VERSION ""

NS_ :

BS_:

BU_: AHLM ASBS CBC DIAGNOST DPDM DTCM ECM EHPS ESC ESL ESM ETM GPF HCP IC IRCM OCM ORC PTS RF_HUB SCCM SGW TBM TCM TPM

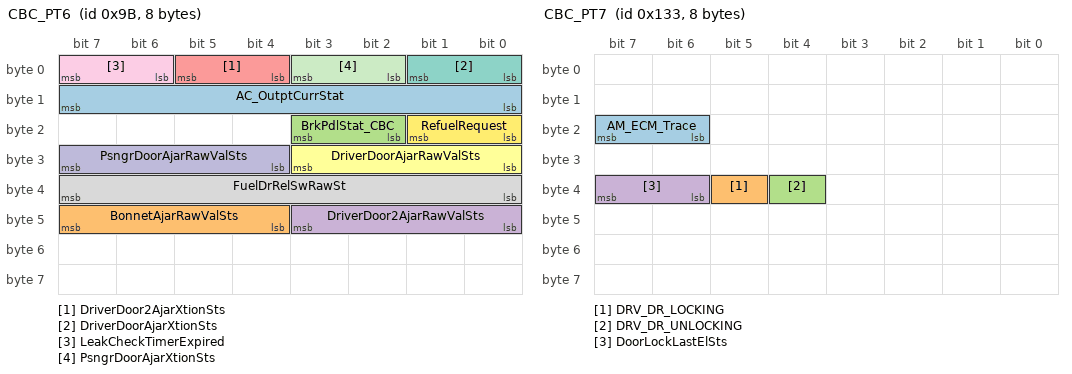
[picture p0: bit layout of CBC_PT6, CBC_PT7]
BO_ 155 CBC_PT6: 8 CBC
 SG_ AC_OutptCurrStat : 8|8@1+ (0.008,0) [0|2] "Amp"  ECM,SGW
 SG_ BonnetAjarRawValSts : 44|4@1+ (1,0) [0|0] ""  ECM,HCP,ORC,SGW
 SG_ BrkPdlStat_CBC : 18|2@1+ (1,0) [0|0] ""  RF_HUB,SGW
 SG_ DriverDoor2AjarRawValSts : 40|4@1+ (1,0) [0|0] ""  ECM,ORC,SGW
 SG_ DriverDoor2AjarXtionSts : 4|2@1+ (1,0) [0|0] ""  ECM,SGW
 SG_ DriverDoorAjarRawValSts : 24|4@1+ (1,0) [0|0] ""  ECM,ESC,ORC,SGW
 SG_ DriverDoorAjarXtionSts : 0|2@1+ (1,0) [0|0] ""  ECM,ESC,SGW
 SG_ FuelDrRelSwRawSt : 32|8@1+ (0.019607843,0) [0|4.98] "Volts"  ECM,SGW
 SG_ LeakCheckTimerExpired : 6|2@1+ (1,0) [0|0] ""  ECM,SGW
 SG_ PsngrDoorAjarRawValSts : 28|4@1+ (1,0) [0|0] ""  ECM,ESC,ORC,SGW
 SG_ PsngrDoorAjarXtionSts : 2|2@1+ (1,0) [0|0] ""  ECM,ESC,SGW
 SG_ RefuelRequest : 16|2@1+ (1,0) [0|0] ""  ECM,SGW

BO_ 307 CBC_PT7: 8 CBC
 SG_ AM_ECM_Trace : 22|2@1+ (1,0) [0|0] ""  ECM,SGW
 SG_ DRV_DR_LOCKING : 37|1@1+ (1,0) [0|1] ""  SGW
 SG_ DRV_DR_UNLOCKING : 36|1@1+ (1,0) [0|1] ""  HCP,SGW
 SG_ DoorLockLastElSts : 38|2@1+ (1,0) [0|3] ""  HCP,SGW

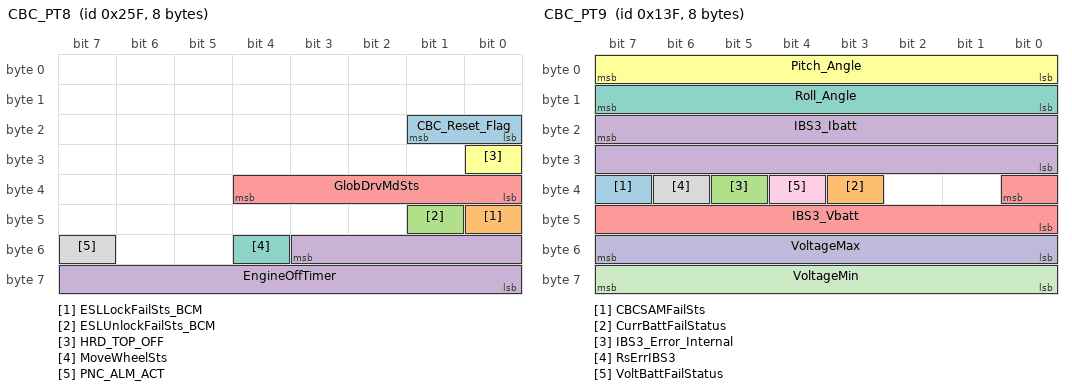
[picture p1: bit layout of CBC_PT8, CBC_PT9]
BO_ 607 CBC_PT8: 8 CBC
 SG_ CBC_Reset_Flag : 16|2@1+ (1,0) [0|0] ""  ECM,SGW
 SG_ ESLLockFailSts_BCM : 40|1@1+ (1,0) [0|0] ""  IC,SGW
 SG_ ESLUnlockFailSts_BCM : 41|1@1+ (1,0) [0|0] ""  IC,SGW
 SG_ EngineOffTimer : 51|12@0+ (1,0) [0|4080] "min"  ECM,ETM,SGW,TBM
 SG_ GlobDrvMdSts : 32|5@1+ (1,0) [0|0] ""  DTCM,ECM,ESC,IC,IRCM,ORC,SGW
 SG_ HRD_TOP_OFF : 24|1@1+ (1,0) [0|0] ""  SGW
 SG_ MoveWheelSts : 52|1@1+ (1,0) [0|0] ""  IC,SGW
 SG_ PNC_ALM_ACT : 55|1@1+ (1,0) [0|0] ""  SGW

BO_ 319 CBC_PT9: 8 CBC
 SG_ CBCSAMFailSts : 39|1@1+ (1,0) [0|0] ""  ECM,SGW
 SG_ CurrBattFailStatus : 35|1@1+ (1,0) [0|0] ""  ECM,SGW
 SG_ IBS3_Error_Internal : 37|1@1+ (1,0) [0|0] ""  ECM,SGW
 SG_ IBS3_Ibatt : 23|16@0+ (0.02,-1000) [-1000|310.68] "A"  ECM,ETM,SGW,TBM
 SG_ IBS3_Vbatt : 32|9@0+ (0.025,5) [5|17.75] "V"  ECM,ETM,HCP,ORC,SGW,TBM
 SG_ Pitch_Angle : 0|8@1+ (1,-90) [-90|90] "°"  IC,SGW
 SG_ Roll_Angle : 8|8@1+ (1,-90) [-90|90] "°"  IC,SGW
 SG_ RsErrIBS3 : 38|1@1+ (1,0) [0|0] ""  ECM,SGW
 SG_ VoltBattFailStatus : 36|1@1+ (1,0) [0|0] ""  ECM,HCP,SGW
 SG_ VoltageMax : 48|8@1+ (0.025,10.6) [10.6|16.975] "Volts"  ECM,SGW
 SG_ VoltageMin : 56|8@1+ (0.025,10.6) [10.6|16.975] "Volts"  ECM,SGW

BO_ 456 CBC_VTA: 4 CBC
 SG_ VTA_STAT : 0|3@1+ (1,0) [0|0] ""  ETM,RF_HUB,SGW,TBM

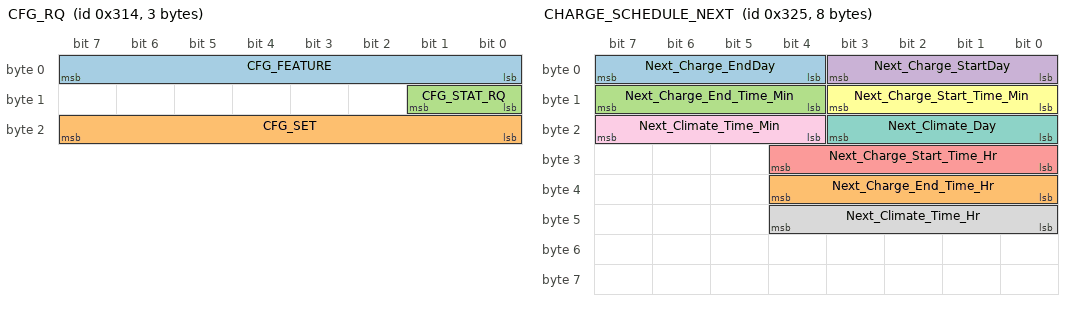
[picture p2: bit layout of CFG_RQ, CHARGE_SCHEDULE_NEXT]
BO_ 788 CFG_RQ: 3 CBC
 SG_ CFG_FEATURE : 0|8@1+ (1,0) [0|0] ""  ESC,HCP,IC,IRCM,PTS,RF_HUB,SGW
 SG_ CFG_SET : 16|8@1+ (1,0) [0|255] ""  ESC,HCP,IC,IRCM,PTS,RF_HUB,SGW
 SG_ CFG_STAT_RQ : 8|2@1+ (1,0) [0|0] ""  ESC,HCP,IC,IRCM,PTS,RF_HUB,SGW

BO_ 805 CHARGE_SCHEDULE_NEXT: 8 HCP
 SG_ Next_Charge_EndDay : 4|4@1+ (1,0) [0|0] ""  CBC,SGW
 SG_ Next_Charge_End_Time_Hr : 32|5@1+ (1,0) [0|23] "Hours"  CBC,SGW
 SG_ Next_Charge_End_Time_Min : 12|4@1+ (5,0) [0|55] "min"  CBC,SGW
 SG_ Next_Charge_StartDay : 0|4@1+ (1,0) [0|0] ""  CBC,SGW
 SG_ Next_Charge_Start_Time_Hr : 24|5@1+ (1,0) [0|23] "Hours"  CBC,SGW
 SG_ Next_Charge_Start_Time_Min : 8|4@1+ (5,0) [0|55] "min"  CBC,SGW
 SG_ Next_Climate_Day : 16|4@1+ (1,0) [0|0] ""  CBC,SGW,TBM
 SG_ Next_Climate_Time_Hr : 40|5@1+ (1,0) [0|23] "Hours"  CBC,SGW,TBM
 SG_ Next_Climate_Time_Min : 20|4@1+ (5,0) [0|55] "min"  CBC,SGW,TBM

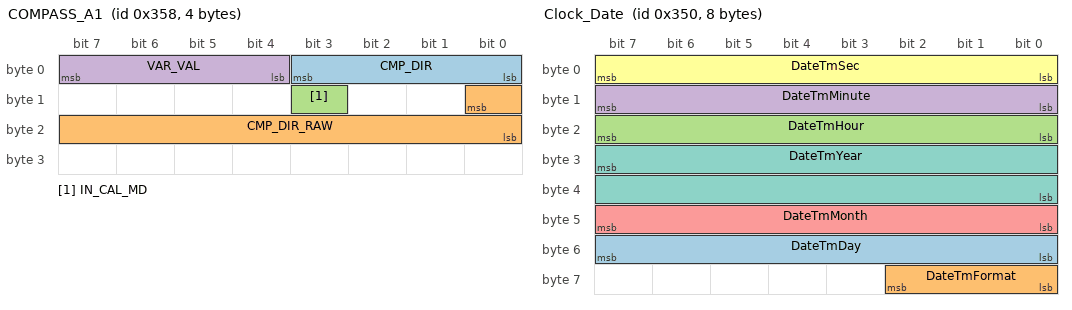
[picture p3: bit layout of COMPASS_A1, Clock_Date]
BO_ 856 COMPASS_A1: 4 CBC
 SG_ CMP_DIR : 0|4@1+ (1,0) [0|0] ""  IC,SGW
 SG_ CMP_DIR_RAW : 8|9@0+ (1,0) [0|359] "Degrees"  SGW
 SG_ IN_CAL_MD : 11|1@1+ (1,0) [0|0] ""  SGW
 SG_ VAR_VAL : 4|4@1+ (1,1) [1|15] ""  SGW

BO_ 219 CfgRqIC: 3 IC
 SG_ CfgFeature : 0|8@1+ (1,0) [0|0] ""  ORC,SGW
 SG_ CfgStatRq : 8|2@1+ (1,0) [0|0] ""  ORC,SGW

BO_ 848 Clock_Date: 8 CBC
 SG_ DateTmDay : 48|8@1+ (1,0) [1|31] "Days"  HCP,IC,RF_HUB,SGW,TPM
 SG_ DateTmFormat : 56|3@1+ (1,0) [0|0] ""  HCP,IC,SGW
 SG_ DateTmHour : 16|8@1+ (1,0) [0|23] "Hours"  HCP,IC,RF_HUB,SGW
 SG_ DateTmMinute : 8|8@1+ (1,0) [0|59] "min"  HCP,IC,RF_HUB,SGW
 SG_ DateTmMonth : 40|8@1+ (1,0) [1|12] "Months"  HCP,IC,RF_HUB,SGW,TPM
 SG_ DateTmSec : 0|8@1+ (1,0) [0|59] "sec"  HCP,IC,SGW
 SG_ DateTmYear : 31|16@0+ (1,0) [0|65534] "Years"  HCP,IC,RF_HUB,SGW,TPM

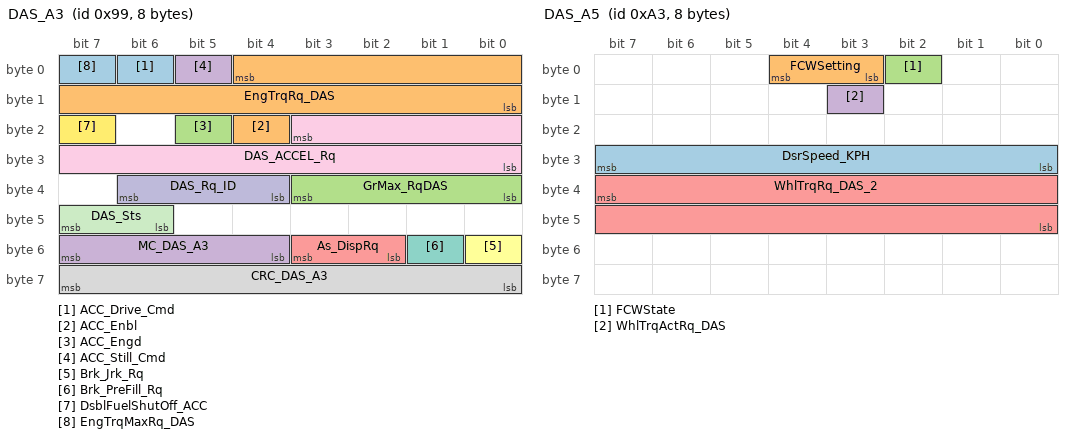
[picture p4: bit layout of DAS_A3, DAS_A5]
BO_ 153 DAS_A3: 8 IRCM
 SG_ ACC_Drive_Cmd : 6|1@1+ (1,0) [0|0] ""  ESC,SGW
 SG_ ACC_Enbl : 20|1@1+ (1,0) [0|0] ""  CBC,ESC,IC,SGW
 SG_ ACC_Engd : 21|1@1+ (1,0) [0|0] ""  ESC,ETM,IC,SGW,TBM
 SG_ ACC_Still_Cmd : 5|1@1+ (1,0) [0|0] ""  ESC,ORC,SGW
 SG_ As_DispRq : 50|2@1+ (1,0) [0|0] ""  ESC,IC,ORC,SGW
 SG_ Brk_Jrk_Rq : 48|1@1+ (1,0) [0|0] ""  ESC,SGW
 SG_ Brk_PreFill_Rq : 49|1@1+ (1,0) [0|0] ""  ESC,SGW
 SG_ CRC_DAS_A3 : 56|8@1+ (1,0) [0|0] ""  ESC,SGW
 SG_ DAS_ACCEL_Rq : 19|12@0+ (0.004885,-16) [-16|4] "m/s²"  ESC,ORC,SGW
 SG_ DAS_Rq_ID : 36|3@1+ (1,0) [0|0] ""  ESC,ORC,SGW
 SG_ DAS_Sts : 46|2@1+ (1,0) [0|0] ""  ESC,SGW
 SG_ DsblFuelShutOff_ACC : 23|1@1+ (1,0) [0|0] ""  ESC,SGW
 SG_ EngTrqMaxRq_DAS : 7|1@1+ (1,0) [0|0] ""  ESC,SGW
 SG_ EngTrqRq_DAS : 4|13@0+ (0.25,-500) [-500|1547.5] "Nm"  ESC,SGW
 SG_ GrMax_RqDAS : 32|4@1+ (1,0) [0|0] ""  ESC,SGW
 SG_ MC_DAS_A3 : 52|4@1+ (1,0) [0|15] ""  ESC,SGW

BO_ 232 DAS_A4: 8 IRCM
 SG_ ACCFaulted : 50|1@1+ (1,0) [0|0] ""  ETM,IC,ORC,SGW,TBM
 SG_ ACCNA_DASMSts : 52|1@1+ (1,0) [0|0] ""  IC,SGW
 SG_ ACCOnOff : 36|3@1+ (1,0) [0|0] ""  ECM,ETM,IC,ORC,SGW,TBM
 SG_ ACConlyNA_DASMSts : 48|1@1+ (1,0) [0|0] ""  ETM,IC,SGW,TBM
 SG_ CIPV_Fused : 30|1@1+ (1,0) [0|0] ""  ORC,SGW
 SG_ CameraBlocked : 54|1@1+ (1,0) [0|0] ""  CBC,IC,ORC,SGW
 SG_ CameraFailure : 55|1@1+ (1,0) [0|0] ""  IC,ORC,SGW
 SG_ FCWBrakingOff : 47|1@1+ (1,0) [0|0] ""  IC,SGW
 SG_ FCW_BrkOn : 29|1@1+ (1,0) [0|0] ""  CBC,ORC,SGW
 SG_ FCW_Error : 26|2@1+ (1,0) [0|0] ""  IC,ORC,SGW
 SG_ FCWonlyNA_DASMSts : 51|1@1+ (1,0) [0|0] ""  IC,SGW
 SG_ HMI_Screens : 0|8@1+ (1,0) [0|254] "Text"  IC,SGW
 SG_ NCCNA_DASMSts : 53|1@1+ (1,0) [0|0] ""  IC,SGW
 SG_ NCConlyNA_DASMSts : 49|1@1+ (1,0) [0|0] ""  ETM,IC,SGW,TBM
 SG_ ObjIntrstDist : 56|8@1+ (1,0) [0|253] "m"  ORC,SGW,TCM
 SG_ RadarBlocked : 46|1@1+ (1,0) [0|0] ""  CBC,IC,ORC,SGW
 SG_ SetSpeed_KPH : 8|8@1+ (1,0) [0|250] "km/h"  ECM,IC,SGW,TCM
 SG_ SetSpeed_MPH : 16|8@1+ (1,0) [0|250] "mph"  IC,ORC,SGW,TCM
 SG_ Sm_ICON_Dspl : 40|6@1+ (1,0) [0|0] ""  IC,SGW

BO_ 163 DAS_A5: 8 IRCM
 SG_ DsrSpeed_KPH : 24|8@1+ (1,0) [0|250] "km/h"  SGW,TCM
 SG_ FCWSetting : 3|2@1+ (1,0) [0|0] ""  CBC,ORC,SGW
 SG_ FCWState : 2|1@1+ (1,0) [0|0] ""  CBC,IC,ORC,SGW
 SG_ WhlTrqActRq_DAS : 11|1@1+ (1,0) [0|0] ""  ESC,SGW
 SG_ WhlTrqRq_DAS_2 : 39|16@0+ (2,-36878) [-36878|94190] "Nm"  ESC,SGW

BO_ 250 DAS_A6: 8 IRCM
 SG_ IRCM_AHB_On : 47|1@1+ (1,0) [0|0] ""  CBC,SGW
 SG_ Lane_DispPopupSts : 16|8@1+ (1,0) [0|254] ""  IC,SGW

BO_ 2015 DG_RQ_GLOBAL: 8 DIAGNOST
 SG_ DG_RQ_GLOBAL : 7|64@0+ (1,0) [0|0] ""  ECM,HCP,TCM

BO_ 1089 DG_RQ_GLOBAL_UDS: 8 DIAGNOST
 SG_ DG_RQ_GLOBAL_UDS : 7|64@0+ (1,0) [0|0] ""  AHLM,ASBS,CBC,DPDM,DTCM,ECM,EHPS,ESC,ESL,ESM,ETM,GPF,HCP,IC,IRCM,OCM,ORC,PTS,RF_HUB,SCCM,TBM,TCM,TPM

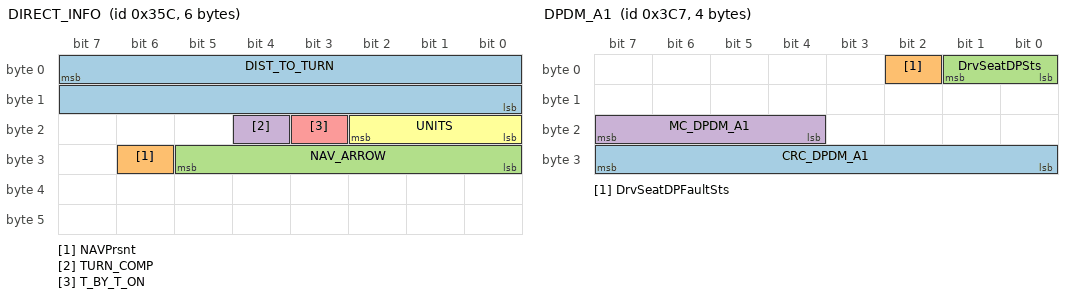
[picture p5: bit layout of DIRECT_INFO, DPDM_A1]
BO_ 860 DIRECT_INFO: 6 CBC
 SG_ DIST_TO_TURN : 7|16@0+ (1,0) [0|65534] ""  IC,SGW
 SG_ NAVPrsnt : 30|1@1+ (1,0) [0|0] ""  IC,SGW
 SG_ NAV_ARROW : 24|6@1+ (1,0) [1|63] "Arrow"  IC,SGW
 SG_ TURN_COMP : 20|1@1+ (1,0) [0|0] ""  IC,SGW
 SG_ T_BY_T_ON : 19|1@1+ (1,0) [0|0] ""  IC,SGW
 SG_ UNITS : 16|3@1+ (1,0) [0|0] ""  IC,SGW

BO_ 967 DPDM_A1: 4 DPDM
 SG_ CRC_DPDM_A1 : 24|8@1+ (1,0) [0|0] ""  ECM,SGW
 SG_ DrvSeatDPFaultSts : 2|1@1+ (1,0) [0|0] ""  ECM,ORC,SGW
 SG_ DrvSeatDPSts : 0|2@1+ (1,0) [0|0] ""  ECM,ESC,IRCM,ORC,RF_HUB,SGW
 SG_ MC_DPDM_A1 : 20|4@1+ (1,0) [0|15] ""  ECM,SGW

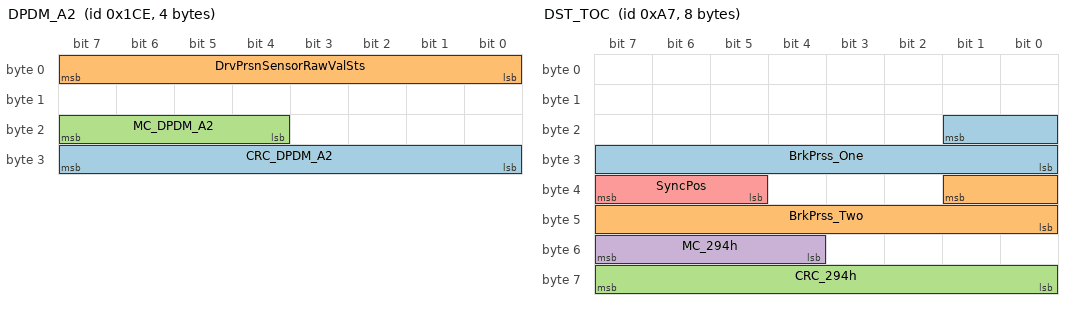
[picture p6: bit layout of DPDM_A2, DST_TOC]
BO_ 462 DPDM_A2: 4 DPDM
 SG_ CRC_DPDM_A2 : 24|8@1+ (1,0) [0|0] ""  ECM,SGW
 SG_ DrvPrsnSensorRawValSts : 0|8@1+ (1,0) [0|255] ""  ECM,SGW
 SG_ MC_DPDM_A2 : 20|4@1+ (1,0) [0|15] ""  ECM,SGW

BO_ 167 DST_TOC: 8 ESC
 SG_ BrkPrss_One : 17|10@0+ (0.0048828125,0) [0|4.9951171875] "Volts"  ECM,SGW
 SG_ BrkPrss_Two : 33|10@0+ (0.0048828125,0) [0|4.9951171875] "Volts"  ECM,SGW
 SG_ CRC_294h : 56|8@1+ (1,0) [0|0] ""  SGW
 SG_ MC_294h : 52|4@1+ (1,0) [0|15] ""  SGW
 SG_ SyncPos : 37|3@1+ (1,0) [0|0] ""  ECM,SGW

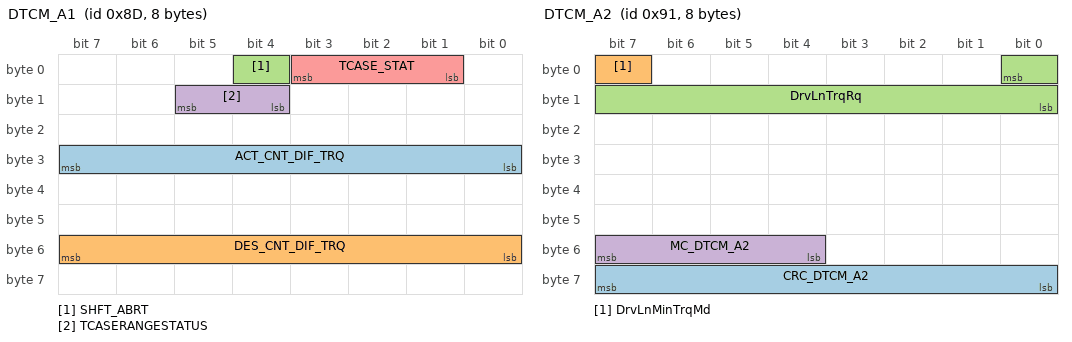
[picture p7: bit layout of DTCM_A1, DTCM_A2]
BO_ 141 DTCM_A1: 8 DTCM
 SG_ ACT_CNT_DIF_TRQ : 24|8@1+ (10,0) [0|2540] "Nm"  ESC,SGW
 SG_ DES_CNT_DIF_TRQ : 48|8@1+ (10,0) [0|2540] "Nm"  SGW
 SG_ SHFT_ABRT : 4|1@1+ (1,0) [0|0] ""  SGW
 SG_ TCASERANGESTATUS : 12|2@1+ (1,0) [0|0] ""  ECM,HCP,SGW,TCM
 SG_ TCASE_STAT : 1|3@1+ (1,0) [0|0] ""  ASBS,CBC,ECM,ESC,ETM,HCP,IC,IRCM,ORC,PTS,RF_HUB,SGW,TBM,TCM

BO_ 145 DTCM_A2: 8 DTCM
 SG_ CRC_DTCM_A2 : 56|8@1+ (1,0) [0|0] ""  ECM,SGW
 SG_ DrvLnMinTrqMd : 7|1@1+ (1,0) [0|0] ""  ECM,SGW
 SG_ DrvLnTrqRq : 0|9@0+ (2,0) [0|1020] "Nm"  ECM,SGW
 SG_ MC_DTCM_A2 : 52|4@1+ (1,0) [0|15] ""  ECM,SGW

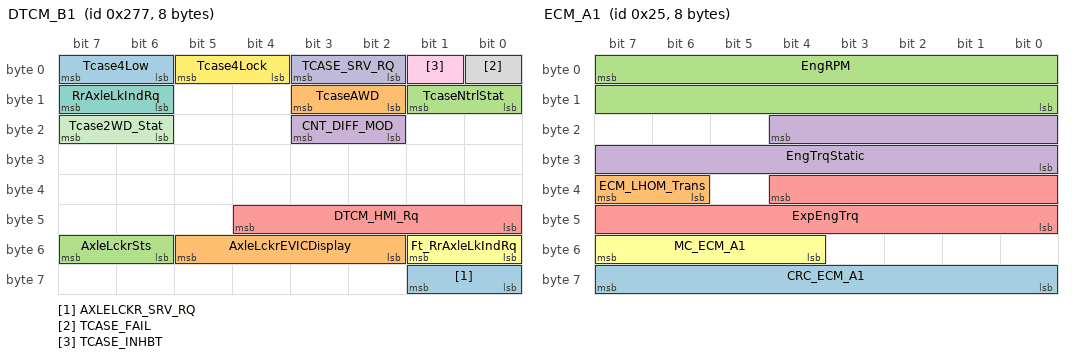
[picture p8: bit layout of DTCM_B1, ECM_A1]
BO_ 631 DTCM_B1: 8 DTCM
 SG_ AXLELCKR_SRV_RQ : 56|2@1+ (1,0) [0|0] ""  IC,SGW
 SG_ AxleLckrEVICDisplay : 50|4@1+ (1,0) [0|0] ""  ETM,IC,SGW
 SG_ AxleLckrSts : 54|2@1+ (1,0) [0|0] ""  ESC,ETM,IC,ORC,SGW
 SG_ CNT_DIFF_MOD : 18|2@1+ (1,0) [0|0] ""  SGW
 SG_ DTCM_HMI_Rq : 40|5@1+ (1,0) [0|0] ""  IC,SGW
 SG_ Ft_RrAxleLkIndRq : 48|2@1+ (1,0) [0|0] ""  CBC,ETM,IC,SGW
 SG_ RrAxleLkIndRq : 14|2@1+ (1,0) [0|0] ""  CBC,ETM,IC,ORC,SGW
 SG_ TCASE_FAIL : 0|1@1+ (1,0) [0|0] ""  ECM,SGW
 SG_ TCASE_INHBT : 1|1@1+ (1,0) [0|0] ""  SGW
 SG_ TCASE_SRV_RQ : 2|2@1+ (1,0) [0|0] ""  ESC,ETM,IC,SGW,TBM
 SG_ Tcase2WD_Stat : 22|2@1+ (1,0) [0|0] ""  CBC,ETM,IC,SGW
 SG_ Tcase4Lock : 4|2@1+ (1,0) [0|0] ""  CBC,ETM,IC,SGW
 SG_ Tcase4Low : 6|2@1+ (1,0) [0|0] ""  CBC,ETM,IC,SGW
 SG_ TcaseAWD : 10|2@1+ (1,0) [0|0] ""  CBC,ETM,IC,SGW
 SG_ TcaseNtrlStat : 8|2@1+ (1,0) [0|0] ""  CBC,ETM,IC,SGW

BO_ 1900 D_RQ_AHCP: 8 DIAGNOST
 SG_ D_RQ_AHCP : 7|64@0+ (1,0) [0|0] ""  HCP

BO_ 1897 D_RQ_AHLM: 8 DIAGNOST
 SG_ D_RQ_AHLM : 7|64@0+ (1,0) [0|0] ""  AHLM

BO_ 1866 D_RQ_ASBS: 8 DIAGNOST
 SG_ D_RQ_ASBS : 7|64@0+ (1,0) [0|0] ""  ASBS

BO_ 2023 D_RQ_BPCM: 8 DIAGNOST
 SG_ D_RQ_BPCM : 7|64@0+ (1,0) [0|0] ""  HCP

BO_ 2020 D_RQ_BSMO: 8 DIAGNOST
 SG_ D_RQ_BSMO : 7|64@0+ (1,0) [0|0] ""  ESC

BO_ 1568 D_RQ_CBC: 8 DIAGNOST
 SG_ D_RQ_CBC : 7|64@0+ (1,0) [0|0] ""  CBC

BO_ 1875 D_RQ_DASM: 8 DIAGNOST
 SG_ D_RQ_DASM : 7|64@0+ (1,0) [0|0] ""  IRCM

BO_ 1873 D_RQ_DPDM: 8 DIAGNOST
 SG_ D_RQ_DPDM : 7|64@0+ (1,0) [0|0] ""  DPDM

BO_ 1867 D_RQ_DTCM: 8 DIAGNOST
 SG_ D_RQ_DTCM : 7|64@0+ (1,0) [0|0] ""  DTCM

BO_ 2016 D_RQ_ECM: 8 DIAGNOST
 SG_ D_RQ_ECM : 7|64@0+ (1,0) [0|0] ""  ECM

BO_ 1882 D_RQ_EPS: 8 DIAGNOST
 SG_ D_RQ_EPS : 7|64@0+ (1,0) [0|0] ""  EHPS

BO_ 1863 D_RQ_ESC: 8 DIAGNOST
 SG_ D_RQ_ESC : 7|64@0+ (1,0) [0|0] ""  ESC

BO_ 1864 D_RQ_ESL: 8 DIAGNOST
 SG_ D_RQ_ESL : 7|64@0+ (1,0) [0|0] ""  ESL

BO_ 1865 D_RQ_ESM: 8 DIAGNOST
 SG_ D_RQ_ESM : 7|64@0+ (1,0) [0|0] ""  ESM

BO_ 1906 D_RQ_GPF: 8 DIAGNOST
 SG_ D_RQ_GPF : 7|64@0+ (1,0) [0|0] ""  GPF

BO_ 2018 D_RQ_HCP: 8 DIAGNOST
 SG_ D_RQ_HCP : 7|64@0+ (1,0) [0|0] ""  HCP

BO_ 1858 D_RQ_IC: 8 DIAGNOST
 SG_ D_RQ_IC : 7|64@0+ (1,0) [0|0] ""  IC

BO_ 1901 D_RQ_IDCM: 8 DIAGNOST
 SG_ D_RQ_IDCM : 7|64@0+ (1,0) [0|0] ""  HCP

BO_ 1886 D_RQ_OCM: 8 DIAGNOST
 SG_ D_RQ_OCM : 7|64@0+ (1,0) [0|0] ""  OCM

BO_ 1860 D_RQ_ORC: 8 DIAGNOST
 SG_ D_RQ_ORC : 7|64@0+ (1,0) [0|0] ""  ORC

BO_ 1890 D_RQ_PTS: 8 DIAGNOST
 SG_ D_RQ_PTS : 7|64@0+ (1,0) [0|0] ""  PTS

BO_ 1856 D_RQ_RF_HUB: 8 DIAGNOST
 SG_ D_RQ_RF_HUB : 7|64@0+ (1,0) [0|0] ""  RF_HUB

BO_ 1891 D_RQ_SCCM: 8 DIAGNOST
 SG_ D_RQ_SCCM : 7|64@0+ (1,0) [0|0] ""  SCCM

BO_ 1150 D_RQ_SGW: 8 DIAGNOST
 SG_ D_RQ_SGW : 7|64@0+ (1,0) [0|0] ""  SGW

BO_ 1963 D_RQ_TBM: 8 DIAGNOST
 SG_ D_RQ_TBM : 7|64@0+ (1,0) [0|0] ""  TBM

BO_ 2017 D_RQ_TCM: 8 DIAGNOST
 SG_ D_RQ_TCM : 7|64@0+ (1,0) [0|0] ""  TCM

BO_ 1859 D_RQ_TPM: 8 DIAGNOST
 SG_ D_RQ_TPM : 7|64@0+ (1,0) [0|0] ""  TPM

BO_ 1260 D_RS_AHCP: 8 HCP
 SG_ D_RS_AHCP : 7|64@0+ (1,0) [0|0] ""  DIAGNOST,ETM,SGW,TBM

BO_ 1257 D_RS_AHLM: 8 AHLM
 SG_ D_RS_AHLM : 7|64@0+ (1,0) [0|0] ""  DIAGNOST,ETM,SGW,TBM

BO_ 1226 D_RS_ASBS: 8 ASBS
 SG_ D_RS_ASBS : 7|64@0+ (1,0) [0|0] ""  DIAGNOST,ETM,SGW,TBM

BO_ 2031 D_RS_BPCM: 8 HCP
 SG_ D_RS_BPCM : 7|64@0+ (1,0) [0|0] ""  DIAGNOST,ETM,SGW,TBM

BO_ 2028 D_RS_BSMO: 8 ESC
 SG_ D_RS_BSMO : 7|64@0+ (1,0) [0|0] ""  DIAGNOST,ETM,SGW,TBM

BO_ 1284 D_RS_CBC: 8 CBC
 SG_ D_RS_CBC : 7|64@0+ (1,0) [0|0] ""  DIAGNOST,ETM,SGW,TBM

BO_ 1235 D_RS_DASM: 8 IRCM
 SG_ D_RS_DASM : 7|64@0+ (1,0) [0|0] ""  DIAGNOST,ETM,SGW,TBM

BO_ 1233 D_RS_DPDM: 8 DPDM
 SG_ D_RS_DPDM : 7|64@0+ (1,0) [0|0] ""  DIAGNOST,ETM,SGW,TBM

BO_ 1227 D_RS_DTCM: 8 DTCM
 SG_ D_RS_DTCM : 7|64@0+ (1,0) [0|0] ""  DIAGNOST,ETM,SGW,TBM

BO_ 2024 D_RS_ECM: 8 ECM
 SG_ D_RS_ECM : 7|64@0+ (1,0) [0|0] ""  DIAGNOST,ETM,SGW,TBM

BO_ 1242 D_RS_EPS: 8 EHPS
 SG_ D_RS_EPS : 7|64@0+ (1,0) [0|0] ""  DIAGNOST,ETM,SGW,TBM

BO_ 1223 D_RS_ESC: 8 ESC
 SG_ D_RS_ESC : 7|64@0+ (1,0) [0|0] ""  DIAGNOST,ETM,SGW,TBM

BO_ 1224 D_RS_ESL: 8 ESL
 SG_ D_RS_ESL : 7|64@0+ (1,0) [0|0] ""  DIAGNOST,ETM,SGW,TBM

BO_ 1225 D_RS_ESM: 8 ESM
 SG_ D_RS_ESM : 7|64@0+ (1,0) [0|0] ""  DIAGNOST,ETM,SGW,TBM

BO_ 1266 D_RS_GPF: 8 GPF
 SG_ D_RS_GPF : 7|64@0+ (1,0) [0|0] ""  DIAGNOST,ETM,SGW,TBM

BO_ 2026 D_RS_HCP: 8 HCP
 SG_ D_RS_HCP : 7|64@0+ (1,0) [0|0] ""  DIAGNOST,ETM,SGW,TBM

BO_ 1218 D_RS_IC: 8 IC
 SG_ D_RS_IC : 7|64@0+ (1,0) [0|0] ""  DIAGNOST,ETM,SGW,TBM

BO_ 1261 D_RS_IDCM: 8 HCP
 SG_ D_RS_IDCM : 7|64@0+ (1,0) [0|0] ""  DIAGNOST,ETM,SGW,TBM

BO_ 1246 D_RS_OCM: 8 OCM
 SG_ D_RS_OCM : 7|64@0+ (1,0) [0|0] ""  DIAGNOST,ETM,SGW,TBM

BO_ 1220 D_RS_ORC: 8 ORC
 SG_ D_RS_ORC : 7|64@0+ (1,0) [0|0] ""  DIAGNOST,ETM,SGW,TBM

BO_ 1250 D_RS_PTS: 8 PTS
 SG_ D_RS_PTS : 7|64@0+ (1,0) [0|0] ""  DIAGNOST,ETM,SGW,TBM

BO_ 1216 D_RS_RF_HUB: 8 RF_HUB
 SG_ D_RS_RF_HUB : 7|64@0+ (1,0) [0|0] ""  DIAGNOST,ETM,SGW,TBM

BO_ 1251 D_RS_SCCM: 8 SCCM
 SG_ D_RS_SCCM : 7|64@0+ (1,0) [0|0] ""  DIAGNOST,ETM,SGW,TBM

BO_ 1151 D_RS_SGW: 8 SGW
 SG_ D_RS_SGW : 7|64@0+ (1,0) [0|0] ""  DIAGNOST,ETM,TBM

BO_ 1323 D_RS_TBM: 8 SGW
 SG_ D_RS_TBM : 7|64@0+ (1,0) [0|0] ""  DIAGNOST

BO_ 2025 D_RS_TCM: 8 TCM
 SG_ D_RS_TCM : 7|64@0+ (1,0) [0|0] ""  DIAGNOST,ETM,SGW,TBM

BO_ 1219 D_RS_TPM: 8 TPM
 SG_ D_RS_TPM : 7|64@0+ (1,0) [0|0] ""  DIAGNOST,ETM,SGW,TBM

BO_ 37 ECM_A1: 8 ECM
 SG_ CRC_ECM_A1 : 56|8@1+ (1,0) [0|0] ""  ESC,IRCM,SGW,TCM
 SG_ ECM_LHOM_Trans : 38|2@1+ (1,0) [0|0] ""  SGW,TCM
 SG_ EngRPM : 7|16@0+ (1,0) [0|65534] "rpm"  AHLM,CBC,DTCM,EHPS,ESC,ETM,IC,IRCM,ORC,RF_HUB,SGW,TBM,TCM
 SG_ EngTrqStatic : 20|13@0+ (0.25,-500) [-500|1547.5] "Nm"  DTCM,ESC,ETM,IRCM,ORC,SGW,TBM,TCM
 SG_ ExpEngTrq : 36|13@0+ (0.25,-500) [-500|1547.5] "Nm"  DTCM,ESC,IRCM,SGW
 SG_ MC_ECM_A1 : 52|4@1+ (1,0) [0|15] ""  ESC,IRCM,SGW,TCM

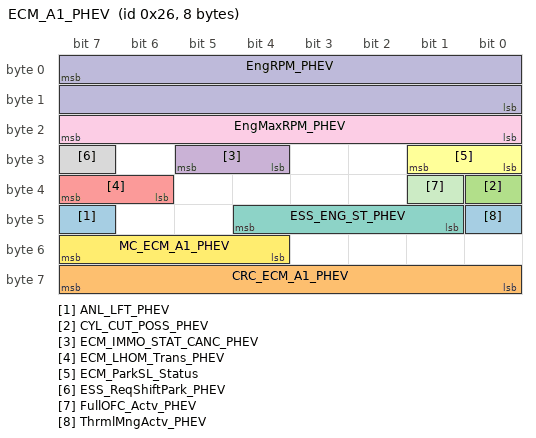
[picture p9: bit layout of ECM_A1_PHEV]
BO_ 38 ECM_A1_PHEV: 8 ECM
 SG_ ANL_LFT_PHEV : 47|1@1+ (1,0) [0|0] ""  CBC,SGW
 SG_ CRC_ECM_A1_PHEV : 56|8@1+ (1,0) [0|0] ""  DTCM,ESC,HCP,IRCM,SGW,TCM
 SG_ CYL_CUT_POSS_PHEV : 32|1@1+ (1,0) [0|0] ""  SGW
 SG_ ECM_IMMO_STAT_CANC_PHEV : 28|2@1+ (1,0) [0|0] ""  CBC,HCP,SGW
 SG_ ECM_LHOM_Trans_PHEV : 38|2@1+ (1,0) [0|0] ""  HCP,SGW
 SG_ ECM_ParkSL_Status : 24|2@1+ (1,0) [0|0] ""  SGW,TCM
 SG_ ESS_ENG_ST_PHEV : 41|4@1+ (1,0) [0|0] ""  CBC,DTCM,ESC,IC,IRCM,ORC,PTS,SGW,TCM
 SG_ ESS_ReqShiftPark_PHEV : 31|1@1+ (1,0) [0|0] ""  SGW,TCM
 SG_ EngMaxRPM_PHEV : 16|8@1+ (50,0) [0|12700] "rpm"  HCP,SGW
 SG_ EngRPM_PHEV : 7|16@0+ (1,0) [0|65534] "rpm"  AHLM,CBC,EHPS,ESC,ETM,HCP,IC,IRCM,ORC,RF_HUB,SGW,TBM,TCM
 SG_ FullOFC_Actv_PHEV : 33|1@1+ (1,0) [0|0] ""  ESC,SGW
 SG_ MC_ECM_A1_PHEV : 52|4@1+ (1,0) [0|15] ""  DTCM,ESC,HCP,IRCM,SGW,TCM
 SG_ ThrmlMngActv_PHEV : 40|1@1+ (1,0) [0|0] ""  HCP,IRCM,SGW

BO_TX_BU_ 2015 : DIAGNOST,SGW;
BO_TX_BU_ 1089 : DIAGNOST,SGW;
BO_TX_BU_ 1900 : DIAGNOST,ETM,SGW,TBM;
BO_TX_BU_ 1897 : DIAGNOST,ETM,SGW,TBM;
BO_TX_BU_ 1866 : DIAGNOST,ETM,SGW,TBM;
BO_TX_BU_ 2023 : DIAGNOST,ETM,SGW,TBM;
BO_TX_BU_ 2020 : DIAGNOST,ETM,SGW,TBM;
BO_TX_BU_ 1568 : DIAGNOST,ETM,SGW,TBM;
BO_TX_BU_ 1875 : DIAGNOST,ETM,SGW,TBM;
BO_TX_BU_ 1873 : DIAGNOST,ETM,SGW,TBM;
BO_TX_BU_ 1867 : DIAGNOST,ETM,SGW,TBM;
BO_TX_BU_ 2016 : DIAGNOST,ETM,SGW,TBM;
BO_TX_BU_ 1882 : DIAGNOST,ETM,SGW,TBM;
BO_TX_BU_ 1863 : DIAGNOST,ETM,SGW,TBM;
BO_TX_BU_ 1864 : DIAGNOST,ETM,SGW,TBM;
BO_TX_BU_ 1865 : DIAGNOST,ETM,SGW,TBM;
BO_TX_BU_ 1906 : DIAGNOST,ETM,SGW,TBM;
BO_TX_BU_ 2018 : DIAGNOST,ETM,SGW,TBM;
BO_TX_BU_ 1858 : DIAGNOST,ETM,SGW,TBM;
BO_TX_BU_ 1901 : DIAGNOST,ETM,SGW,TBM;
BO_TX_BU_ 1886 : DIAGNOST,ETM,SGW,TBM;
BO_TX_BU_ 1860 : DIAGNOST,ETM,SGW,TBM;
BO_TX_BU_ 1890 : DIAGNOST,ETM,SGW,TBM;
BO_TX_BU_ 1856 : DIAGNOST,ETM,SGW,TBM;
BO_TX_BU_ 1891 : DIAGNOST,ETM,SGW,TBM;
BO_TX_BU_ 1150 : DIAGNOST,ETM,SGW,TBM;
BO_TX_BU_ 1963 : DIAGNOST,SGW;
BO_TX_BU_ 2017 : DIAGNOST,ETM,SGW,TBM;
BO_TX_BU_ 1859 : DIAGNOST,ETM,SGW,TBM;
BO_TX_BU_ 1323 : SGW,TBM;
CM_ SG_ 155 AC_OutptCurrStat "AC output current status";
CM_ SG_ 155 BonnetAjarRawValSts "Hood ajar status";
CM_ SG_ 155 BrkPdlStat_CBC "Brake pedal state reported by CBC";
CM_ SG_ 155 DriverDoor2AjarRawValSts "Drivers door switch - 2 ajar status";
CM_ SG_ 155 DriverDoor2AjarXtionSts "Drivers door switch - 2 ajar transition status";
CM_ SG_ 155 DriverDoorAjarRawValSts "Drivers door ajar status";
CM_ SG_ 155 DriverDoorAjarXtionSts "Drivers door ajar transition status";
CM_ SG_ 155 FuelDrRelSwRawSt "Raw voltage of fuel door release switch in the cabin";
CM_ SG_ 155 LeakCheckTimerExpired "Status of leak test timer";
CM_ SG_ 155 PsngrDoorAjarRawValSts "Passengers door ajar status";
CM_ SG_ 155 PsngrDoorAjarXtionSts "Front passenger door ajar transition status";
CM_ SG_ 155 RefuelRequest "Driver has initiated a refueling event";
CM_ SG_ 307 AM_ECM_Trace "Aftermarket ECM trace";
CM_ SG_ 307 DRV_DR_LOCKING "Vehicle driver-side door is locking.";
CM_ SG_ 307 DRV_DR_UNLOCKING "Vehicle driver-side door is unlocking.";
CM_ SG_ 307 DoorLockLastElSts "Electric door lock last known status.";
CM_ SG_ 607 CBC_Reset_Flag "CBC reset flag";
CM_ SG_ 607 ESLLockFailSts_BCM "Display info on failed lock; Failed = [1]";
CM_ SG_ 607 ESLUnlockFailSts_BCM "Display info on failed unlock; Failed = [1]";
CM_ SG_ 607 EngineOffTimer "Engine off timer - engine off ignition NOT lock.";
CM_ SG_ 607 GlobDrvMdSts "Global drive mode status";
CM_ SG_ 607 HRD_TOP_OFF "Removable hard top is off";
CM_ SG_ 607 MoveWheelSts "Display message to move steering wheel; Active = [1]";
CM_ SG_ 607 PNC_ALM_ACT "Panic alarm active; [1] = True";
CM_ SG_ 319 CBCSAMFailSts "Fault present in BCM related to the SAM strategy";
CM_ SG_ 319 CurrBattFailStatus "Failure Status of Current meas. (internal defect)";
CM_ SG_ 319 IBS3_Error_Internal "Error in IBS calibration data; No Error = [0], Error = [1]";
CM_ SG_ 319 IBS3_Ibatt "Battery current";
CM_ SG_ 319 IBS3_Vbatt "Battery voltage measured at the terminals";
CM_ SG_ 319 Pitch_Angle "Pitch angle; Disable = [FE]";
CM_ SG_ 319 Roll_Angle "Roll angle";
CM_ SG_ 319 RsErrIBS3 "Response Error IBS; Error=[1]";
CM_ SG_ 319 VoltBattFailStatus "Failure Status of Voltage meas. (internal defect)";
CM_ SG_ 319 VoltageMax "Maximum regulation voltage permitted by CBC in the SAM strategy";
CM_ SG_ 319 VoltageMin "Minimum regulation voltage permitted by CBC in the SAM strategy";
CM_ SG_ 456 VTA_STAT "VTA status";
CM_ SG_ 788 CFG_FEATURE "Configurable feature";
CM_ SG_ 788 CFG_SET "Specific setting or value (see reference)";
CM_ SG_ 788 CFG_STAT_RQ "Configurable feature status request";
CM_ SG_ 805 Next_Charge_EndDay "Next schedule end day to stop charging";
CM_ SG_ 805 Next_Charge_End_Time_Hr "End time of next charge schedule window (hours, in 24hr format)";
CM_ SG_ 805 Next_Charge_End_Time_Min "End time of next charge schedule window (in minutes)";
CM_ SG_ 805 Next_Charge_StartDay "Next schedule start day for charging";
CM_ SG_ 805 Next_Charge_Start_Time_Hr "Start time of next charge schedule window (hours, in 24hr format)";
CM_ SG_ 805 Next_Charge_Start_Time_Min "Start time of next charge schedule window (in minutes)";
CM_ SG_ 805 Next_Climate_Day "Next climate scheduled departure day";
CM_ SG_ 805 Next_Climate_Time_Hr "Next climate scheduled departure time (hours, in 24hr format)";
CM_ SG_ 805 Next_Climate_Time_Min "Next climate scheduled departure time (minutes)";
CM_ SG_ 856 CMP_DIR "Compass direction (WK/LX)";
CM_ SG_ 856 CMP_DIR_RAW "Compass direction raw";
CM_ SG_ 856 IN_CAL_MD "In Calibration Mode";
CM_ SG_ 856 VAR_VAL "RCM Variance Value";
CM_ SG_ 219 CfgFeature "Configurable feature";
CM_ SG_ 219 CfgStatRq "Configurable feature status request";
CM_ SG_ 848 DateTmDay "Day";
CM_ SG_ 848 DateTmFormat "Date and Time Format";
CM_ SG_ 848 DateTmHour "Time of day: HOURS";
CM_ SG_ 848 DateTmMinute "Time of day: MINUTES";
CM_ SG_ 848 DateTmMonth "Month";
CM_ SG_ 848 DateTmSec "Time of day: SECONDS";
CM_ SG_ 848 DateTmYear "Date year";
CM_ SG_ 153 ACC_Drive_Cmd "ACC drive off commanded; True = [1]";
CM_ SG_ 153 ACC_Enbl "ACC cruise control enabled; True = [1]";
CM_ SG_ 153 ACC_Engd "ACC engaged; True = [1]";
CM_ SG_ 153 ACC_Still_Cmd "ACC stop commanded; True = [1]";
CM_ SG_ 153 As_DispRq "Assistance system display request (priority)";
CM_ SG_ 153 Brk_Jrk_Rq "Brake jerk request; True = [1]";
CM_ SG_ 153 Brk_PreFill_Rq "Brakes pre-fill request; True = [1]";
CM_ SG_ 153 CRC_DAS_A3 "CRC-checksum byte 1 to 7 according to SAE J1850";
CM_ SG_ 153 DAS_ACCEL_Rq "DASM acceleration request";
CM_ SG_ 153 DAS_Rq_ID "DAS request ID";
CM_ SG_ 153 DAS_Sts "DASM fault status";
CM_ SG_ 153 DsblFuelShutOff_ACC "Disable fuel shutoff; True = [1]";
CM_ SG_ 153 EngTrqMaxRq_DAS "Engine torque request maximum; True = [1]";
CM_ SG_ 153 EngTrqRq_DAS "Requested engine torque";
CM_ SG_ 153 GrMax_RqDAS "Requested gear, upper limit";
CM_ SG_ 153 MC_DAS_A3 "Message counter";
CM_ SG_ 232 ACCFaulted "ACC faulted; True = [1]";
CM_ SG_ 232 ACCNA_DASMSts "ACC/FCW not avail: vehicle system error; True = [1]";
CM_ SG_ 232 ACCOnOff "ACC on off status";
CM_ SG_ 232 ACConlyNA_DASMSts "ACC only not available: vehicle system error; True = [1]";
CM_ SG_ 232 CIPV_Fused "Closest in-path vehicle is fused; True = [1]";
CM_ SG_ 232 CameraBlocked "ACC FCW limited functionality: camera blocked; True = [1]";
CM_ SG_ 232 CameraFailure "ACC/FCW limited functionality: camera failure; True = [1]";
CM_ SG_ 232 FCWBrakingOff "FCW autobraking disabled; True = [1]";
CM_ SG_ 232 FCW_BrkOn "FCW braking is on; true = [1]";
CM_ SG_ 232 FCW_Error "Forward collision warning error";
CM_ SG_ 232 FCWonlyNA_DASMSts "FCW only not available: vehicle system error; True = [1]";
CM_ SG_ 232 HMI_Screens "HMI screens";
CM_ SG_ 232 NCCNA_DASMSts "NCC/FCW not avail: vehicle system error; True = [1]";
CM_ SG_ 232 NCConlyNA_DASMSts "NCC only not available: vehicle system error; True = [1]";
CM_ SG_ 232 ObjIntrstDist "Object of interest distance";
CM_ SG_ 232 RadarBlocked "ACC FCW not available: clean radar snsr; True = [1]";
CM_ SG_ 232 SetSpeed_KPH "Desired set speed in kilometers per hour";
CM_ SG_ 232 SetSpeed_MPH "Desired set speed in miles per hour";
CM_ SG_ 232 Sm_ICON_Dspl "Small graphic display";
CM_ SG_ 163 DsrSpeed_KPH "Desired speed in kilometers per hour";
CM_ SG_ 163 FCWSetting "Forward collision warning sensitivity setting";
CM_ SG_ 163 FCWState "FCW system operating state; On = [1]";
CM_ SG_ 163 WhlTrqActRq_DAS "Wheel torque request active; True = [1]";
CM_ SG_ 163 WhlTrqRq_DAS_2 "Requested wheel torque by ACC/DASM";
CM_ SG_ 250 IRCM_AHB_On "Auto high beam on request from the IRCM ECU";
CM_ SG_ 250 Lane_DispPopupSts "Lane Management Pop-up Messages.TEXT MSG n corresponds to a raw value of 'n'";
CM_ SG_ 2015 DG_RQ_GLOBAL "Diagnostic-Request";
CM_ SG_ 1089 DG_RQ_GLOBAL_UDS "Diagnostic-Request";
CM_ SG_ 860 DIST_TO_TURN "Numeric distance to next turn";
CM_ SG_ 860 NAVPrsnt "A navigation system module is present";
CM_ SG_ 860 NAV_ARROW "Navigation arrow type";
CM_ SG_ 860 TURN_COMP "Turn complete";
CM_ SG_ 860 T_BY_T_ON "Turn by turn on";
CM_ SG_ 860 UNITS "Unit of measure";
CM_ SG_ 967 CRC_DPDM_A1 "CRC-checksum byte 1 to 5 according to SAE J1850";
CM_ SG_ 967 DrvSeatDPFaultSts "Driver Detection Fault Status";
CM_ SG_ 967 DrvSeatDPSts "Driver Presence Status";
CM_ SG_ 967 MC_DPDM_A1 "Message counter";
CM_ SG_ 462 CRC_DPDM_A2 "CRC-checksum byte 1 to 5 according to SAE J1850";
CM_ SG_ 462 DrvPrsnSensorRawValSts "Pressure sensor raw value status";
CM_ SG_ 462 MC_DPDM_A2 "Message counter";
CM_ SG_ 167 BrkPrss_One "Brake Pressure One (P1)";
CM_ SG_ 167 BrkPrss_Two "Brake Pressure Two (P2 if supported)";
CM_ SG_ 167 CRC_294h "CRC-checksum byte 1 to 7 according to SAE J1850";
CM_ SG_ 167 MC_294h "Message counter";
CM_ SG_ 167 SyncPos "Signal P2 sync position";
CM_ SG_ 141 ACT_CNT_DIF_TRQ "Actual center differential torque lock";
CM_ SG_ 141 DES_CNT_DIF_TRQ "Desired center differential torque lock";
CM_ SG_ 141 SHFT_ABRT "Shift has been abortet";
CM_ SG_ 141 TCASERANGESTATUS "This signal is used for update the Transfer case Range status";
CM_ SG_ 141 TCASE_STAT "Transfer Case Status";
CM_ SG_ 145 CRC_DTCM_A2 "CRC-checksum byte 1 to 7 according to SAE J1850";
CM_ SG_ 145 DrvLnMinTrqMd "Drive line engine torque request: min.-mode";
CM_ SG_ 145 DrvLnTrqRq "Drive line requested engine torque";
CM_ SG_ 145 MC_DTCM_A2 "Message counter";
CM_ SG_ 631 AXLELCKR_SRV_RQ "Axle locker service indicator request";
CM_ SG_ 631 AxleLckrEVICDisplay "Axle locker HMI display request";
CM_ SG_ 631 AxleLckrSts "Axle locker status";
CM_ SG_ 631 CNT_DIFF_MOD "Actual mode of center differential";
CM_ SG_ 631 DTCM_HMI_Rq "DTCM AWD / 4WD HMI display request";
CM_ SG_ 631 Ft_RrAxleLkIndRq "Front and Rear axle lock indicator request";
CM_ SG_ 631 RrAxleLkIndRq "Rear axle lock indicator request";
CM_ SG_ 631 TCASE_FAIL "T Case System Fault (Limp in)";
CM_ SG_ 631 TCASE_INHBT "All wheel drive mode inhibited";
CM_ SG_ 631 TCASE_SRV_RQ "Transfer case service indicator request";
CM_ SG_ 631 Tcase2WD_Stat "Transfer case 2 wheel drive status";
CM_ SG_ 631 Tcase4Lock "Transfer case 4WD locked status";
CM_ SG_ 631 Tcase4Low "Transfer case low range LED status";
CM_ SG_ 631 TcaseAWD "Transfer case High range / AWD LED status";
CM_ SG_ 631 TcaseNtrlStat "Transfer case neutral LED status";
CM_ SG_ 1900 D_RQ_AHCP "Diagnostic-Request";
CM_ SG_ 1897 D_RQ_AHLM "Diagnostic-Request";
CM_ SG_ 1866 D_RQ_ASBS "Diagnostic-Request";
CM_ SG_ 2023 D_RQ_BPCM "Diagnostic-Request";
CM_ SG_ 2020 D_RQ_BSMO "Diagnostic-Request";
CM_ SG_ 1568 D_RQ_CBC "Diagnostic-Request";
CM_ SG_ 1875 D_RQ_DASM "Diagnostic-Request";
CM_ SG_ 1873 D_RQ_DPDM "Diagnostic-Request";
CM_ SG_ 1867 D_RQ_DTCM "Diagnostic-Request";
CM_ SG_ 2016 D_RQ_ECM "Diagnostic-Request";
CM_ SG_ 1882 D_RQ_EPS "Diagnostic-Request";
CM_ SG_ 1863 D_RQ_ESC "Diagnostic-Request";
CM_ SG_ 1864 D_RQ_ESL "Diagnostic-Request";
CM_ SG_ 1865 D_RQ_ESM "Diagnostic-Request";
CM_ SG_ 1906 D_RQ_GPF "Diagnostic-Request";
CM_ SG_ 2018 D_RQ_HCP "Diagnostic-Request";
CM_ SG_ 1858 D_RQ_IC "Diagnostic-Request";
CM_ SG_ 1901 D_RQ_IDCM "Diagnostic-Request";
CM_ SG_ 1886 D_RQ_OCM "Diagnostic-Request";
CM_ SG_ 1860 D_RQ_ORC "Diagnostic-Request";
CM_ SG_ 1890 D_RQ_PTS "Diagnostic-Request";
CM_ SG_ 1856 D_RQ_RF_HUB "Diagnostic-Request";
CM_ SG_ 1891 D_RQ_SCCM "Diagnostic-Request";
CM_ SG_ 1150 D_RQ_SGW "Diagnostic-Request";
CM_ SG_ 1963 D_RQ_TBM "Diagnostic-Request";
CM_ SG_ 2017 D_RQ_TCM "Diagnostic-Request";
CM_ SG_ 1859 D_RQ_TPM "Diagnostic-Request";
CM_ SG_ 1260 D_RS_AHCP "Diagnostic-Response";
CM_ SG_ 1257 D_RS_AHLM "Diagnostic-Response";
CM_ SG_ 1226 D_RS_ASBS "Diagnostic-Response";
CM_ SG_ 2031 D_RS_BPCM "Diagnostic-Response";
CM_ SG_ 2028 D_RS_BSMO "Diagnostic-Response";
CM_ SG_ 1284 D_RS_CBC "Diagnostic-Response";
CM_ SG_ 1235 D_RS_DASM "Diagnostic-Response";
CM_ SG_ 1233 D_RS_DPDM "Diagnostic-Response";
CM_ SG_ 1227 D_RS_DTCM "Diagnostic-Response";
CM_ SG_ 2024 D_RS_ECM "Diagnostic-Response";
CM_ SG_ 1242 D_RS_EPS "Diagnostic-Response";
CM_ SG_ 1223 D_RS_ESC "Diagnostic-Response";
CM_ SG_ 1224 D_RS_ESL "Diagnostic-Response";
CM_ SG_ 1225 D_RS_ESM "Diagnostic-Response";
CM_ SG_ 1266 D_RS_GPF "Diagnostic-Response";
CM_ SG_ 2026 D_RS_HCP "Diagnostic-Response";
CM_ SG_ 1218 D_RS_IC "Diagnostic-Response";
CM_ SG_ 1261 D_RS_IDCM "Diagnostic-Response";
CM_ SG_ 1246 D_RS_OCM "Diagnostic-Response";
CM_ SG_ 1220 D_RS_ORC "Diagnostic-Response";
CM_ SG_ 1250 D_RS_PTS "Diagnostic-Response";
CM_ SG_ 1216 D_RS_RF_HUB "Diagnostic-Response";
CM_ SG_ 1251 D_RS_SCCM "Diagnostic-Response";
CM_ SG_ 1151 D_RS_SGW "Diagnostic-Response";
CM_ SG_ 1323 D_RS_TBM "Diagnostic-Response";
CM_ SG_ 2025 D_RS_TCM "Diagnostic-Response";
CM_ SG_ 1219 D_RS_TPM "Diagnostic-Response";
CM_ SG_ 37 CRC_ECM_A1 "CRC-checksum byte 1 to 7 according to SAE J1850";
CM_ SG_ 37 ECM_LHOM_Trans "Torque Accuracy Information for Transmission";
CM_ SG_ 37 EngRPM "Engine revolutions per minute";
CM_ SG_ 37 EngTrqStatic "Static engine torque / Effective engine torque";
CM_ SG_ 37 ExpEngTrq "Expected Engine Torque based on target engine speed";
CM_ SG_ 37 MC_ECM_A1 "Message counter";
CM_ SG_ 38 ANL_LFT_PHEV "Starter motor running (Cranking)";
CM_ SG_ 38 CRC_ECM_A1_PHEV "CRC-checksum byte 1 to 7 according to SAE J1850";
CM_ SG_ 38 CYL_CUT_POSS_PHEV "Cylinder cut-out conditions fulfilled";
CM_ SG_ 38 ECM_IMMO_STAT_CANC_PHEV "ECM immobilizer status";
CM_ SG_ 38 ECM_LHOM_Trans_PHEV "Torque Accuracy Information for Transmission";
CM_ SG_ 38 ECM_ParkSL_Status "ECM command to park pawl hold solenoid (Energize/De-energize)";
CM_ SG_ 38 ESS_ENG_ST_PHEV "ESS Engine State";
CM_ SG_ 38 ESS_ReqShiftPark_PHEV "ESS Request shift to Park.  1 = True, 0 = False";
CM_ SG_ 38 EngMaxRPM_PHEV "Engine maximum RPM";
CM_ SG_ 38 EngRPM_PHEV "Engine revolutions per minute";
CM_ SG_ 38 FullOFC_Actv_PHEV "Cylinder cut-out";
CM_ SG_ 38 MC_ECM_A1_PHEV "Message counter";
CM_ SG_ 38 ThrmlMngActv_PHEV "Indicates ECM RPM Limitation Status, Active = 1";
BA_DEF_ BO_  "App-Botschaft" ENUM  "nein","ja";
BA_DEF_ BO_  "CanMsgMinLen" INT 0 8;
BA_DEF_ BO_  "DiagRequest" ENUM  "nein","ja";
BA_DEF_ BO_  "DiagResponse" ENUM  "nein","ja";
BA_DEF_ BO_  "DiagState" ENUM  "nein","ja";
BA_DEF_ BO_  "GenMsgCycleTime" INT 0 65535;
BA_DEF_ BO_  "GenMsgCycleTimeActive" INT 0 65535;
BA_DEF_ BO_  "GenMsgDelayTime" INT 0 65535;
BA_DEF_ BO_  "GenMsgNrOfRepetitions" INT 0 65535;
BA_DEF_ BO_  "GenMsgSendType" ENUM  "cyclicX","spontanX","cyclicIfActiveX","spontanWithDelay","cyclicAndSpontanX","cyclicAndSpontanWithDelay","spontanWithRepitition","cyclicIfActiveAndSpontanWD","cyclicIfActiveFast","cyclicWithRepeatOnDemand","none";
BA_DEF_ BO_  "GenMsgStartDelayTime" INT 0 65535;
BA_DEF_ BO_  "GenMsgStartValue" STRING ;
BA_DEF_ BO_  "NWM-Botschaft" ENUM  "nein","ja";
BA_DEF_ BO_  "TpTxIndex" INT 0 99;
BA_DEF_ SG_  "FlexKomComment" STRING ;
BA_DEF_ SG_  "FlexKomIsMotorola" ENUM  "nein","ja";
BA_DEF_ SG_  "FlexKomSID" INT 0 2147483647;
BA_DEF_ SG_  "FlexKomSigLaenge" INT 0 64;
BA_DEF_ SG_  "FlexKomSigName" STRING ;
BA_DEF_ SG_  "FlexKomSigStartPos" INT 0 63;
BA_DEF_ SG_  "FlexKomSigStartValue" STRING ;
BA_DEF_ SG_  "GenSigCycleTime" INT 0 65535;
BA_DEF_ SG_  "GenSigCycleTimeActive" INT 0 65535;
BA_DEF_ SG_  "GenSigSendType" ENUM  "cyclicX","spontanX","cyclicIfActiveX","spontanWithDelay","cyclicAndSpontanX","cyclicAndSpontanWithDelay","spontanWithRepitition","cyclicIfActiveAndSpontanWD","cyclicIfActiveFast","cyclicWithRepeatOnDemand","none";
BA_DEF_ SG_  "GenSigSNA" STRING ;
BA_DEF_ SG_  "GenSigStartValue" HEX 0 2147483648;
BA_DEF_ SG_  "GenSigTimeout_AHLM" INT 0 65535;
BA_DEF_ SG_  "GenSigTimeout_ASBS" INT 0 65535;
BA_DEF_ SG_  "GenSigTimeout_CBC" INT 0 65535;
BA_DEF_ SG_  "GenSigTimeout_DPDM" INT 0 65535;
BA_DEF_ SG_  "GenSigTimeout_DTCM" INT 0 65535;
BA_DEF_ SG_  "GenSigTimeout_EHPS" INT 0 65535;
BA_DEF_ SG_  "GenSigTimeout_ESC" INT 0 65535;
BA_DEF_ SG_  "GenSigTimeout_ESL" INT 0 65535;
BA_DEF_ SG_  "GenSigTimeout_ESM" INT 0 65535;
BA_DEF_ SG_  "GenSigTimeout_ETM" INT 0 65535;
BA_DEF_ SG_  "GenSigTimeout_IC" INT 0 65535;
BA_DEF_ SG_  "GenSigTimeout_OCM" INT 0 65535;
BA_DEF_ SG_  "GenSigTimeout_ORC" INT 0 65535;
BA_DEF_ SG_  "GenSigTimeout_PTS" INT 0 65535;
BA_DEF_ SG_  "GenSigTimeout_RF_HUB" INT 0 65535;
BA_DEF_ SG_  "GenSigTimeout_SCCM" INT 0 65535;
BA_DEF_ SG_  "GenSigTimeout_TBM" INT 0 65535;
BA_DEF_ SG_  "GenSigTimeout_TCM" INT 0 65535;
BA_DEF_ SG_  "GenSigTimeout_TPM" INT 0 65535;
BA_DEF_ SG_  "RID" STRING ;
BA_DEF_ SG_  "SystemSignalLongSymbol" STRING ;
BA_DEF_DEF_  "App-Botschaft" "nein";
BA_DEF_DEF_  "CanMsgMinLen" 0;
BA_DEF_DEF_  "DiagRequest" "nein";
BA_DEF_DEF_  "DiagResponse" "nein";
BA_DEF_DEF_  "DiagState" "nein";
BA_DEF_DEF_  "GenMsgCycleTime" 0;
BA_DEF_DEF_  "GenMsgCycleTimeActive" 0;
BA_DEF_DEF_  "GenMsgDelayTime" 0;
BA_DEF_DEF_  "GenMsgNrOfRepetitions" 0;
BA_DEF_DEF_  "GenMsgSendType" "cyclicX";
BA_DEF_DEF_  "GenMsgStartDelayTime" 0;
BA_DEF_DEF_  "GenMsgStartValue" "";
BA_DEF_DEF_  "NWM-Botschaft" "nein";
BA_DEF_DEF_  "TpTxIndex" 0;
BA_DEF_DEF_  "FlexKomComment" "";
BA_DEF_DEF_  "FlexKomIsMotorola" "nein";
BA_DEF_DEF_  "FlexKomSID" 0;
BA_DEF_DEF_  "FlexKomSigLaenge" 0;
BA_DEF_DEF_  "FlexKomSigName" "";
BA_DEF_DEF_  "FlexKomSigStartPos" 0;
BA_DEF_DEF_  "FlexKomSigStartValue" "";
BA_DEF_DEF_  "GenSigCycleTime" 0;
BA_DEF_DEF_  "GenSigCycleTimeActive" 0;
BA_DEF_DEF_  "GenSigSendType" "cyclicX";
BA_DEF_DEF_  "GenSigSNA" "";
BA_DEF_DEF_  "GenSigStartValue" 0;
BA_DEF_DEF_  "GenSigTimeout_AHLM" 0;
BA_DEF_DEF_  "GenSigTimeout_ASBS" 0;
BA_DEF_DEF_  "GenSigTimeout_CBC" 0;
BA_DEF_DEF_  "GenSigTimeout_DPDM" 0;
BA_DEF_DEF_  "GenSigTimeout_DTCM" 0;
BA_DEF_DEF_  "GenSigTimeout_EHPS" 0;
BA_DEF_DEF_  "GenSigTimeout_ESC" 0;
BA_DEF_DEF_  "GenSigTimeout_ESL" 0;
BA_DEF_DEF_  "GenSigTimeout_ESM" 0;
BA_DEF_DEF_  "GenSigTimeout_ETM" 0;
BA_DEF_DEF_  "GenSigTimeout_IC" 0;
BA_DEF_DEF_  "GenSigTimeout_OCM" 0;
BA_DEF_DEF_  "GenSigTimeout_ORC" 0;
BA_DEF_DEF_  "GenSigTimeout_PTS" 0;
BA_DEF_DEF_  "GenSigTimeout_RF_HUB" 0;
BA_DEF_DEF_  "GenSigTimeout_SCCM" 0;
BA_DEF_DEF_  "GenSigTimeout_TBM" 0;
BA_DEF_DEF_  "GenSigTimeout_TCM" 0;
BA_DEF_DEF_  "GenSigTimeout_TPM" 0;
BA_DEF_DEF_  "RID" "";
BA_DEF_DEF_  "SystemSignalLongSymbol" "";
BA_ "GenMsgStartValue" BO_ 155 "3FFF0C00000000FFh";
BA_ "GenMsgStartDelayTime" BO_ 155 10;
BA_ "GenMsgNrOfRepetitions" BO_ 155 2;
BA_ "GenMsgDelayTime" BO_ 155 20;
BA_ "GenMsgCycleTime" BO_ 155 20;
BA_ "GenMsgStartValue" BO_ 307 "FF030CFFh";
BA_ "GenMsgStartDelayTime" BO_ 307 10;
BA_ "GenMsgNrOfRepetitions" BO_ 307 2;
BA_ "GenMsgDelayTime" BO_ 307 20;
BA_ "GenMsgCycleTime" BO_ 307 100;
BA_ "GenMsgStartValue" BO_ 607 "0000000000000FFFh";
BA_ "GenMsgStartDelayTime" BO_ 607 40;
BA_ "GenMsgSendType" BO_ 607 5;
BA_ "GenMsgNrOfRepetitions" BO_ 607 2;
BA_ "GenMsgDelayTime" BO_ 607 20;
BA_ "GenMsgCycleTime" BO_ 607 1000;
BA_ "GenMsgStartValue" BO_ 319 "5A5AFFFF01FF0000h";
BA_ "GenMsgStartDelayTime" BO_ 319 30;
BA_ "GenMsgNrOfRepetitions" BO_ 319 2;
BA_ "GenMsgDelayTime" BO_ 319 20;
BA_ "GenMsgCycleTime" BO_ 319 100;
BA_ "GenMsgStartValue" BO_ 456 "00000000h";
BA_ "GenMsgStartDelayTime" BO_ 456 30;
BA_ "GenMsgSendType" BO_ 456 5;
BA_ "GenMsgNrOfRepetitions" BO_ 456 2;
BA_ "GenMsgDelayTime" BO_ 456 20;
BA_ "GenMsgCycleTime" BO_ 456 500;
BA_ "GenMsgStartValue" BO_ 788 "000000h";
BA_ "GenMsgSendType" BO_ 788 2;
BA_ "GenMsgNrOfRepetitions" BO_ 788 2;
BA_ "GenMsgDelayTime" BO_ 788 20;
BA_ "GenMsgCycleTimeActive" BO_ 788 50;
BA_ "GenMsgStartValue" BO_ 805 "0000000000000000h";
BA_ "GenMsgSendType" BO_ 805 5;
BA_ "GenMsgNrOfRepetitions" BO_ 805 2;
BA_ "GenMsgDelayTime" BO_ 805 20;
BA_ "GenMsgCycleTime" BO_ 805 1000;
BA_ "GenMsgStartValue" BO_ 856 "FF000000h";
BA_ "GenMsgStartDelayTime" BO_ 856 50;
BA_ "GenMsgNrOfRepetitions" BO_ 856 2;
BA_ "GenMsgDelayTime" BO_ 856 20;
BA_ "GenMsgCycleTime" BO_ 856 1000;
BA_ "GenMsgStartValue" BO_ 219 "000000h";
BA_ "GenMsgSendType" BO_ 219 2;
BA_ "GenMsgNrOfRepetitions" BO_ 219 2;
BA_ "GenMsgDelayTime" BO_ 219 20;
BA_ "GenMsgCycleTimeActive" BO_ 219 50;
BA_ "GenMsgStartValue" BO_ 848 "FFFFFFFFFFFFFF3Fh";
BA_ "GenMsgNrOfRepetitions" BO_ 848 2;
BA_ "GenMsgDelayTime" BO_ 848 20;
BA_ "GenMsgCycleTime" BO_ 848 1000;
BA_ "GenMsgStartValue" BO_ 153 "1FFF0CCB000000FFh";
BA_ "GenMsgNrOfRepetitions" BO_ 153 2;
BA_ "GenMsgDelayTime" BO_ 153 20;
BA_ "GenMsgCycleTime" BO_ 153 20;
BA_ "GenMsgStartValue" BO_ 232 "00FFFF00000000FFh";
BA_ "GenMsgNrOfRepetitions" BO_ 232 2;
BA_ "GenMsgDelayTime" BO_ 232 20;
BA_ "GenMsgCycleTime" BO_ 232 60;
BA_ "GenMsgStartValue" BO_ 163 "000000FF000000FFh";
BA_ "GenMsgNrOfRepetitions" BO_ 163 2;
BA_ "GenMsgDelayTime" BO_ 163 20;
BA_ "GenMsgCycleTime" BO_ 163 20;
BA_ "GenMsgStartValue" BO_ 250 "0000000000000000h";
BA_ "GenMsgSendType" BO_ 250 5;
BA_ "GenMsgNrOfRepetitions" BO_ 250 2;
BA_ "GenMsgDelayTime" BO_ 250 20;
BA_ "GenMsgCycleTime" BO_ 250 60;
BA_ "GenMsgStartValue" BO_ 2015 "0000000000000000h";
BA_ "GenMsgNrOfRepetitions" BO_ 2015 2;
BA_ "GenMsgDelayTime" BO_ 2015 20;
BA_ "DiagState" BO_ 2015 1;
BA_ "GenMsgStartValue" BO_ 1089 "0000000000000000h";
BA_ "GenMsgNrOfRepetitions" BO_ 1089 2;
BA_ "GenMsgDelayTime" BO_ 1089 20;
BA_ "DiagState" BO_ 1089 1;
BA_ "GenMsgStartValue" BO_ 860 "000000000FFFh";
BA_ "GenMsgSendType" BO_ 860 5;
BA_ "GenMsgNrOfRepetitions" BO_ 860 2;
BA_ "GenMsgDelayTime" BO_ 860 20;
BA_ "GenMsgCycleTime" BO_ 860 1000;
BA_ "GenMsgStartValue" BO_ 967 "000000FFh";
BA_ "GenMsgSendType" BO_ 967 5;
BA_ "GenMsgNrOfRepetitions" BO_ 967 2;
BA_ "GenMsgDelayTime" BO_ 967 20;
BA_ "GenMsgCycleTime" BO_ 967 200;
BA_ "GenMsgStartValue" BO_ 462 "FF0000FFh";
BA_ "GenMsgNrOfRepetitions" BO_ 462 2;
BA_ "GenMsgDelayTime" BO_ 462 20;
BA_ "GenMsgCycleTime" BO_ 462 50;
BA_ "GenMsgStartValue" BO_ 167 "04000000C00000FFh";
BA_ "GenMsgNrOfRepetitions" BO_ 167 2;
BA_ "GenMsgDelayTime" BO_ 167 20;
BA_ "GenMsgCycleTime" BO_ 167 20;
BA_ "GenMsgStartValue" BO_ 141 "CEC0FFFFFFFFFFFFh";
BA_ "GenMsgNrOfRepetitions" BO_ 141 2;
BA_ "GenMsgDelayTime" BO_ 141 20;
BA_ "GenMsgCycleTime" BO_ 141 20;
BA_ "GenMsgStartValue" BO_ 145 "01FF7F00000000FFh";
BA_ "GenMsgNrOfRepetitions" BO_ 145 2;
BA_ "GenMsgDelayTime" BO_ 145 20;
BA_ "GenMsgCycleTime" BO_ 145 20;
BA_ "GenMsgStartValue" BO_ 631 "0000000000000000h";
BA_ "GenMsgSendType" BO_ 631 5;
BA_ "GenMsgNrOfRepetitions" BO_ 631 2;
BA_ "GenMsgDelayTime" BO_ 631 20;
BA_ "GenMsgCycleTime" BO_ 631 1000;
BA_ "GenMsgStartValue" BO_ 1900 "0000000000000000h";
BA_ "GenMsgSendType" BO_ 1900 1;
BA_ "GenMsgNrOfRepetitions" BO_ 1900 2;
BA_ "GenMsgDelayTime" BO_ 1900 20;
BA_ "DiagRequest" BO_ 1900 1;
BA_ "GenMsgStartValue" BO_ 1897 "0000000000000000h";
BA_ "GenMsgSendType" BO_ 1897 1;
BA_ "GenMsgNrOfRepetitions" BO_ 1897 2;
BA_ "GenMsgDelayTime" BO_ 1897 20;
BA_ "DiagRequest" BO_ 1897 1;
BA_ "GenMsgStartValue" BO_ 1866 "0000000000000000h";
BA_ "GenMsgSendType" BO_ 1866 1;
BA_ "GenMsgNrOfRepetitions" BO_ 1866 2;
BA_ "GenMsgDelayTime" BO_ 1866 20;
BA_ "DiagRequest" BO_ 1866 1;
BA_ "GenMsgStartValue" BO_ 2023 "0000000000000000h";
BA_ "GenMsgSendType" BO_ 2023 1;
BA_ "GenMsgNrOfRepetitions" BO_ 2023 2;
BA_ "GenMsgDelayTime" BO_ 2023 20;
BA_ "DiagRequest" BO_ 2023 1;
BA_ "GenMsgStartValue" BO_ 2020 "0000000000000000h";
BA_ "GenMsgSendType" BO_ 2020 1;
BA_ "GenMsgNrOfRepetitions" BO_ 2020 2;
BA_ "GenMsgDelayTime" BO_ 2020 20;
BA_ "DiagRequest" BO_ 2020 1;
BA_ "GenMsgStartValue" BO_ 1568 "0000000000000000h";
BA_ "GenMsgSendType" BO_ 1568 1;
BA_ "GenMsgNrOfRepetitions" BO_ 1568 2;
BA_ "GenMsgDelayTime" BO_ 1568 20;
BA_ "DiagRequest" BO_ 1568 1;
BA_ "GenMsgStartValue" BO_ 1875 "0000000000000000h";
BA_ "GenMsgSendType" BO_ 1875 1;
BA_ "GenMsgNrOfRepetitions" BO_ 1875 2;
BA_ "GenMsgDelayTime" BO_ 1875 20;
BA_ "DiagRequest" BO_ 1875 1;
BA_ "GenMsgStartValue" BO_ 1873 "0000000000000000h";
BA_ "GenMsgSendType" BO_ 1873 1;
BA_ "GenMsgNrOfRepetitions" BO_ 1873 2;
BA_ "GenMsgDelayTime" BO_ 1873 20;
BA_ "DiagRequest" BO_ 1873 1;
BA_ "GenMsgStartValue" BO_ 1867 "0000000000000000h";
BA_ "GenMsgSendType" BO_ 1867 1;
BA_ "GenMsgNrOfRepetitions" BO_ 1867 2;
BA_ "GenMsgDelayTime" BO_ 1867 20;
BA_ "DiagRequest" BO_ 1867 1;
BA_ "GenMsgStartValue" BO_ 2016 "0000000000000000h";
BA_ "GenMsgSendType" BO_ 2016 1;
BA_ "GenMsgNrOfRepetitions" BO_ 2016 2;
BA_ "GenMsgDelayTime" BO_ 2016 20;
BA_ "DiagRequest" BO_ 2016 1;
BA_ "GenMsgStartValue" BO_ 1882 "0000000000000000h";
BA_ "GenMsgSendType" BO_ 1882 1;
BA_ "GenMsgNrOfRepetitions" BO_ 1882 2;
BA_ "GenMsgDelayTime" BO_ 1882 20;
BA_ "DiagRequest" BO_ 1882 1;
BA_ "GenMsgStartValue" BO_ 1863 "0000000000000000h";
BA_ "GenMsgSendType" BO_ 1863 1;
BA_ "GenMsgNrOfRepetitions" BO_ 1863 2;
BA_ "GenMsgDelayTime" BO_ 1863 20;
BA_ "DiagRequest" BO_ 1863 1;
BA_ "GenMsgStartValue" BO_ 1864 "0000000000000000h";
BA_ "GenMsgSendType" BO_ 1864 1;
BA_ "GenMsgNrOfRepetitions" BO_ 1864 2;
BA_ "GenMsgDelayTime" BO_ 1864 20;
BA_ "DiagRequest" BO_ 1864 1;
BA_ "GenMsgStartValue" BO_ 1865 "0000000000000000h";
BA_ "GenMsgSendType" BO_ 1865 1;
BA_ "GenMsgNrOfRepetitions" BO_ 1865 2;
BA_ "GenMsgDelayTime" BO_ 1865 20;
BA_ "DiagRequest" BO_ 1865 1;
BA_ "GenMsgStartValue" BO_ 1906 "0000000000000000h";
BA_ "GenMsgSendType" BO_ 1906 1;
BA_ "GenMsgNrOfRepetitions" BO_ 1906 2;
BA_ "GenMsgDelayTime" BO_ 1906 20;
BA_ "DiagRequest" BO_ 1906 1;
BA_ "GenMsgStartValue" BO_ 2018 "0000000000000000h";
BA_ "GenMsgSendType" BO_ 2018 1;
BA_ "GenMsgNrOfRepetitions" BO_ 2018 2;
BA_ "GenMsgDelayTime" BO_ 2018 20;
BA_ "DiagRequest" BO_ 2018 1;
BA_ "GenMsgStartValue" BO_ 1858 "0000000000000000h";
BA_ "GenMsgSendType" BO_ 1858 1;
BA_ "GenMsgNrOfRepetitions" BO_ 1858 2;
BA_ "GenMsgDelayTime" BO_ 1858 20;
BA_ "DiagRequest" BO_ 1858 1;
BA_ "GenMsgStartValue" BO_ 1901 "0000000000000000h";
BA_ "GenMsgSendType" BO_ 1901 1;
BA_ "GenMsgNrOfRepetitions" BO_ 1901 2;
BA_ "GenMsgDelayTime" BO_ 1901 20;
BA_ "DiagRequest" BO_ 1901 1;
BA_ "GenMsgStartValue" BO_ 1886 "0000000000000000h";
BA_ "GenMsgSendType" BO_ 1886 1;
BA_ "GenMsgNrOfRepetitions" BO_ 1886 2;
BA_ "GenMsgDelayTime" BO_ 1886 20;
BA_ "DiagRequest" BO_ 1886 1;
BA_ "GenMsgStartValue" BO_ 1860 "0000000000000000h";
BA_ "GenMsgSendType" BO_ 1860 1;
BA_ "GenMsgNrOfRepetitions" BO_ 1860 2;
BA_ "GenMsgDelayTime" BO_ 1860 20;
BA_ "DiagRequest" BO_ 1860 1;
BA_ "GenMsgStartValue" BO_ 1890 "0000000000000000h";
BA_ "GenMsgSendType" BO_ 1890 1;
BA_ "GenMsgNrOfRepetitions" BO_ 1890 2;
BA_ "GenMsgDelayTime" BO_ 1890 20;
BA_ "DiagRequest" BO_ 1890 1;
BA_ "GenMsgStartValue" BO_ 1856 "0000000000000000h";
BA_ "GenMsgSendType" BO_ 1856 1;
BA_ "GenMsgNrOfRepetitions" BO_ 1856 2;
BA_ "GenMsgDelayTime" BO_ 1856 20;
BA_ "DiagRequest" BO_ 1856 1;
BA_ "GenMsgStartValue" BO_ 1891 "0000000000000000h";
BA_ "GenMsgSendType" BO_ 1891 1;
BA_ "GenMsgNrOfRepetitions" BO_ 1891 2;
BA_ "GenMsgDelayTime" BO_ 1891 20;
BA_ "DiagRequest" BO_ 1891 1;
BA_ "GenMsgStartValue" BO_ 1150 "0000000000000000h";
BA_ "GenMsgSendType" BO_ 1150 1;
BA_ "GenMsgNrOfRepetitions" BO_ 1150 2;
BA_ "GenMsgDelayTime" BO_ 1150 20;
BA_ "DiagRequest" BO_ 1150 1;
BA_ "GenMsgStartValue" BO_ 1963 "0000000000000000h";
BA_ "GenMsgSendType" BO_ 1963 1;
BA_ "GenMsgNrOfRepetitions" BO_ 1963 2;
BA_ "GenMsgDelayTime" BO_ 1963 20;
BA_ "DiagRequest" BO_ 1963 1;
BA_ "GenMsgStartValue" BO_ 2017 "0000000000000000h";
BA_ "GenMsgSendType" BO_ 2017 1;
BA_ "GenMsgNrOfRepetitions" BO_ 2017 2;
BA_ "GenMsgDelayTime" BO_ 2017 20;
BA_ "DiagRequest" BO_ 2017 1;
BA_ "GenMsgStartValue" BO_ 1859 "0000000000000000h";
BA_ "GenMsgSendType" BO_ 1859 1;
BA_ "GenMsgNrOfRepetitions" BO_ 1859 2;
BA_ "GenMsgDelayTime" BO_ 1859 20;
BA_ "DiagRequest" BO_ 1859 1;
BA_ "GenMsgStartValue" BO_ 1260 "0000000000000000h";
BA_ "GenMsgSendType" BO_ 1260 1;
BA_ "GenMsgNrOfRepetitions" BO_ 1260 2;
BA_ "GenMsgDelayTime" BO_ 1260 20;
BA_ "DiagResponse" BO_ 1260 1;
BA_ "GenMsgStartValue" BO_ 1257 "0000000000000000h";
BA_ "GenMsgSendType" BO_ 1257 1;
BA_ "GenMsgNrOfRepetitions" BO_ 1257 2;
BA_ "GenMsgDelayTime" BO_ 1257 20;
BA_ "DiagResponse" BO_ 1257 1;
BA_ "GenMsgStartValue" BO_ 1226 "0000000000000000h";
BA_ "GenMsgSendType" BO_ 1226 1;
BA_ "GenMsgNrOfRepetitions" BO_ 1226 2;
BA_ "GenMsgDelayTime" BO_ 1226 20;
BA_ "DiagResponse" BO_ 1226 1;
BA_ "GenMsgStartValue" BO_ 2031 "0000000000000000h";
BA_ "GenMsgSendType" BO_ 2031 1;
BA_ "GenMsgNrOfRepetitions" BO_ 2031 2;
BA_ "GenMsgDelayTime" BO_ 2031 20;
BA_ "DiagResponse" BO_ 2031 1;
BA_ "GenMsgStartValue" BO_ 2028 "0000000000000000h";
BA_ "GenMsgSendType" BO_ 2028 1;
BA_ "GenMsgNrOfRepetitions" BO_ 2028 2;
BA_ "GenMsgDelayTime" BO_ 2028 20;
BA_ "DiagResponse" BO_ 2028 1;
BA_ "GenMsgStartValue" BO_ 1284 "0000000000000000h";
BA_ "GenMsgSendType" BO_ 1284 1;
BA_ "GenMsgNrOfRepetitions" BO_ 1284 2;
BA_ "GenMsgDelayTime" BO_ 1284 20;
BA_ "DiagResponse" BO_ 1284 1;
BA_ "GenMsgStartValue" BO_ 1235 "0000000000000000h";
BA_ "GenMsgSendType" BO_ 1235 1;
BA_ "GenMsgNrOfRepetitions" BO_ 1235 2;
BA_ "GenMsgDelayTime" BO_ 1235 20;
BA_ "DiagResponse" BO_ 1235 1;
BA_ "GenMsgStartValue" BO_ 1233 "0000000000000000h";
BA_ "GenMsgSendType" BO_ 1233 1;
BA_ "GenMsgNrOfRepetitions" BO_ 1233 2;
BA_ "GenMsgDelayTime" BO_ 1233 20;
BA_ "DiagResponse" BO_ 1233 1;
BA_ "GenMsgStartValue" BO_ 1227 "0000000000000000h";
BA_ "GenMsgSendType" BO_ 1227 1;
BA_ "GenMsgNrOfRepetitions" BO_ 1227 2;
BA_ "GenMsgDelayTime" BO_ 1227 20;
BA_ "DiagResponse" BO_ 1227 1;
BA_ "GenMsgStartValue" BO_ 2024 "0000000000000000h";
BA_ "GenMsgSendType" BO_ 2024 1;
BA_ "GenMsgNrOfRepetitions" BO_ 2024 2;
BA_ "GenMsgDelayTime" BO_ 2024 20;
BA_ "DiagResponse" BO_ 2024 1;
BA_ "GenMsgStartValue" BO_ 1242 "0000000000000000h";
BA_ "GenMsgSendType" BO_ 1242 1;
BA_ "GenMsgNrOfRepetitions" BO_ 1242 2;
BA_ "GenMsgDelayTime" BO_ 1242 20;
BA_ "DiagResponse" BO_ 1242 1;
BA_ "GenMsgStartValue" BO_ 1223 "0000000000000000h";
BA_ "GenMsgSendType" BO_ 1223 1;
BA_ "GenMsgNrOfRepetitions" BO_ 1223 2;
BA_ "GenMsgDelayTime" BO_ 1223 20;
BA_ "DiagResponse" BO_ 1223 1;
BA_ "GenMsgStartValue" BO_ 1224 "0000000000000000h";
BA_ "GenMsgSendType" BO_ 1224 1;
BA_ "GenMsgNrOfRepetitions" BO_ 1224 2;
BA_ "GenMsgDelayTime" BO_ 1224 20;
BA_ "DiagResponse" BO_ 1224 1;
BA_ "GenMsgStartValue" BO_ 1225 "0000000000000000h";
BA_ "GenMsgSendType" BO_ 1225 1;
BA_ "GenMsgNrOfRepetitions" BO_ 1225 2;
BA_ "GenMsgDelayTime" BO_ 1225 20;
BA_ "DiagResponse" BO_ 1225 1;
BA_ "GenMsgStartValue" BO_ 1266 "0000000000000000h";
BA_ "GenMsgSendType" BO_ 1266 1;
BA_ "GenMsgNrOfRepetitions" BO_ 1266 2;
BA_ "GenMsgDelayTime" BO_ 1266 20;
BA_ "DiagResponse" BO_ 1266 1;
BA_ "GenMsgStartValue" BO_ 2026 "0000000000000000h";
BA_ "GenMsgSendType" BO_ 2026 1;
BA_ "GenMsgNrOfRepetitions" BO_ 2026 2;
BA_ "GenMsgDelayTime" BO_ 2026 20;
BA_ "DiagResponse" BO_ 2026 1;
BA_ "GenMsgStartValue" BO_ 1218 "0000000000000000h";
BA_ "GenMsgSendType" BO_ 1218 1;
BA_ "GenMsgNrOfRepetitions" BO_ 1218 2;
BA_ "GenMsgDelayTime" BO_ 1218 20;
BA_ "DiagResponse" BO_ 1218 1;
BA_ "GenMsgStartValue" BO_ 1261 "0000000000000000h";
BA_ "GenMsgSendType" BO_ 1261 1;
BA_ "GenMsgNrOfRepetitions" BO_ 1261 2;
BA_ "GenMsgDelayTime" BO_ 1261 20;
BA_ "DiagResponse" BO_ 1261 1;
BA_ "GenMsgStartValue" BO_ 1246 "0000000000000000h";
BA_ "GenMsgSendType" BO_ 1246 1;
BA_ "GenMsgNrOfRepetitions" BO_ 1246 2;
BA_ "GenMsgDelayTime" BO_ 1246 20;
BA_ "DiagResponse" BO_ 1246 1;
BA_ "GenMsgStartValue" BO_ 1220 "0000000000000000h";
BA_ "GenMsgSendType" BO_ 1220 1;
BA_ "GenMsgNrOfRepetitions" BO_ 1220 2;
BA_ "GenMsgDelayTime" BO_ 1220 20;
BA_ "DiagResponse" BO_ 1220 1;
BA_ "GenMsgStartValue" BO_ 1250 "0000000000000000h";
BA_ "GenMsgSendType" BO_ 1250 1;
BA_ "GenMsgNrOfRepetitions" BO_ 1250 2;
BA_ "GenMsgDelayTime" BO_ 1250 20;
BA_ "DiagResponse" BO_ 1250 1;
BA_ "GenMsgStartValue" BO_ 1216 "0000000000000000h";
BA_ "GenMsgSendType" BO_ 1216 1;
BA_ "GenMsgNrOfRepetitions" BO_ 1216 2;
BA_ "GenMsgDelayTime" BO_ 1216 20;
BA_ "DiagResponse" BO_ 1216 1;
BA_ "GenMsgStartValue" BO_ 1251 "0000000000000000h";
BA_ "GenMsgSendType" BO_ 1251 1;
BA_ "GenMsgNrOfRepetitions" BO_ 1251 2;
BA_ "GenMsgDelayTime" BO_ 1251 20;
BA_ "DiagResponse" BO_ 1251 1;
BA_ "GenMsgStartValue" BO_ 1151 "0000000000000000h";
BA_ "GenMsgSendType" BO_ 1151 1;
BA_ "GenMsgNrOfRepetitions" BO_ 1151 2;
BA_ "GenMsgDelayTime" BO_ 1151 20;
BA_ "DiagResponse" BO_ 1151 1;
BA_ "GenMsgStartValue" BO_ 1323 "0000000000000000h";
BA_ "GenMsgSendType" BO_ 1323 1;
BA_ "GenMsgNrOfRepetitions" BO_ 1323 2;
BA_ "GenMsgDelayTime" BO_ 1323 20;
BA_ "DiagResponse" BO_ 1323 1;
BA_ "GenMsgStartValue" BO_ 2025 "0000000000000000h";
BA_ "GenMsgSendType" BO_ 2025 1;
BA_ "GenMsgNrOfRepetitions" BO_ 2025 2;
BA_ "GenMsgDelayTime" BO_ 2025 20;
BA_ "DiagResponse" BO_ 2025 1;
BA_ "GenMsgStartValue" BO_ 1219 "0000000000000000h";
BA_ "GenMsgSendType" BO_ 1219 1;
BA_ "GenMsgNrOfRepetitions" BO_ 1219 2;
BA_ "GenMsgDelayTime" BO_ 1219 20;
BA_ "DiagResponse" BO_ 1219 1;
BA_ "GenMsgStartValue" BO_ 37 "FFFF1FFF1FFF00FFh";
BA_ "GenMsgNrOfRepetitions" BO_ 37 2;
BA_ "GenMsgDelayTime" BO_ 37 20;
BA_ "GenMsgCycleTime" BO_ 37 10;
BA_ "GenMsgStartValue" BO_ 38 "FFFFFF00201E00FFh";
BA_ "GenMsgNrOfRepetitions" BO_ 38 2;
BA_ "GenMsgDelayTime" BO_ 38 20;
BA_ "GenMsgCycleTime" BO_ 38 10;
BA_ "RID" SG_ 155 AC_OutptCurrStat "3055";
BA_ "GenSigStartValue" SG_ 155 AC_OutptCurrStat 255;
BA_ "GenSigSNA" SG_ 155 AC_OutptCurrStat "FFh";
BA_ "GenSigCycleTime" SG_ 155 AC_OutptCurrStat 20;
BA_ "FlexKomSigStartValue" SG_ 155 AC_OutptCurrStat "3FFF0C00000000FFh";
BA_ "FlexKomSigStartPos" SG_ 155 AC_OutptCurrStat 7;
BA_ "FlexKomSigName" SG_ 155 AC_OutptCurrStat "CBC_PT6_Pkt";
BA_ "FlexKomSigLaenge" SG_ 155 AC_OutptCurrStat 64;
BA_ "FlexKomSID" SG_ 155 AC_OutptCurrStat 1943;
BA_ "FlexKomIsMotorola" SG_ 155 AC_OutptCurrStat 1;
BA_ "FlexKomComment" SG_ 155 AC_OutptCurrStat "CBC_PT6 message packet";
BA_ "GenSigTimeout_ORC" SG_ 155 BonnetAjarRawValSts 70;
BA_ "GenSigSNA" SG_ 155 BonnetAjarRawValSts "Fh";
BA_ "GenSigCycleTime" SG_ 155 BonnetAjarRawValSts 20;
BA_ "FlexKomSigStartValue" SG_ 155 BonnetAjarRawValSts "3FFF0C00000000FFh";
BA_ "FlexKomSigStartPos" SG_ 155 BonnetAjarRawValSts 7;
BA_ "FlexKomSigName" SG_ 155 BonnetAjarRawValSts "CBC_PT6_Pkt";
BA_ "FlexKomSigLaenge" SG_ 155 BonnetAjarRawValSts 64;
BA_ "FlexKomSID" SG_ 155 BonnetAjarRawValSts 1943;
BA_ "FlexKomIsMotorola" SG_ 155 BonnetAjarRawValSts 1;
BA_ "FlexKomComment" SG_ 155 BonnetAjarRawValSts "CBC_PT6 message packet";
BA_ "GenSigTimeout_RF_HUB" SG_ 155 BrkPdlStat_CBC 210;
BA_ "GenSigStartValue" SG_ 155 BrkPdlStat_CBC 3;
BA_ "GenSigSNA" SG_ 155 BrkPdlStat_CBC "3h";
BA_ "GenSigCycleTime" SG_ 155 BrkPdlStat_CBC 20;
BA_ "FlexKomSigStartValue" SG_ 155 BrkPdlStat_CBC "3FFF0C00000000FFh";
BA_ "FlexKomSigStartPos" SG_ 155 BrkPdlStat_CBC 7;
BA_ "FlexKomSigName" SG_ 155 BrkPdlStat_CBC "CBC_PT6_Pkt";
BA_ "FlexKomSigLaenge" SG_ 155 BrkPdlStat_CBC 64;
BA_ "FlexKomSID" SG_ 155 BrkPdlStat_CBC 1943;
BA_ "FlexKomIsMotorola" SG_ 155 BrkPdlStat_CBC 1;
BA_ "FlexKomComment" SG_ 155 BrkPdlStat_CBC "CBC_PT6 message packet";
BA_ "GenSigSNA" SG_ 155 DriverDoor2AjarRawValSts "Fh";
BA_ "GenSigCycleTime" SG_ 155 DriverDoor2AjarRawValSts 20;
BA_ "FlexKomSigStartValue" SG_ 155 DriverDoor2AjarRawValSts "3FFF0C00000000FFh";
BA_ "FlexKomSigStartPos" SG_ 155 DriverDoor2AjarRawValSts 7;
BA_ "FlexKomSigName" SG_ 155 DriverDoor2AjarRawValSts "CBC_PT6_Pkt";
BA_ "FlexKomSigLaenge" SG_ 155 DriverDoor2AjarRawValSts 64;
BA_ "FlexKomSID" SG_ 155 DriverDoor2AjarRawValSts 1943;
BA_ "FlexKomIsMotorola" SG_ 155 DriverDoor2AjarRawValSts 1;
BA_ "FlexKomComment" SG_ 155 DriverDoor2AjarRawValSts "CBC_PT6 message packet";
BA_ "GenSigStartValue" SG_ 155 DriverDoor2AjarXtionSts 3;
BA_ "GenSigSNA" SG_ 155 DriverDoor2AjarXtionSts "3h";
BA_ "GenSigCycleTime" SG_ 155 DriverDoor2AjarXtionSts 20;
BA_ "FlexKomSigStartValue" SG_ 155 DriverDoor2AjarXtionSts "3FFF0C00000000FFh";
BA_ "FlexKomSigStartPos" SG_ 155 DriverDoor2AjarXtionSts 7;
BA_ "FlexKomSigName" SG_ 155 DriverDoor2AjarXtionSts "CBC_PT6_Pkt";
BA_ "FlexKomSigLaenge" SG_ 155 DriverDoor2AjarXtionSts 64;
BA_ "FlexKomSID" SG_ 155 DriverDoor2AjarXtionSts 1943;
BA_ "FlexKomIsMotorola" SG_ 155 DriverDoor2AjarXtionSts 1;
BA_ "FlexKomComment" SG_ 155 DriverDoor2AjarXtionSts "CBC_PT6 message packet";
BA_ "GenSigTimeout_ORC" SG_ 155 DriverDoorAjarRawValSts 70;
BA_ "GenSigSNA" SG_ 155 DriverDoorAjarRawValSts "Fh";
BA_ "GenSigCycleTime" SG_ 155 DriverDoorAjarRawValSts 20;
BA_ "FlexKomSigStartValue" SG_ 155 DriverDoorAjarRawValSts "3FFF0C00000000FFh";
BA_ "FlexKomSigStartPos" SG_ 155 DriverDoorAjarRawValSts 7;
BA_ "FlexKomSigName" SG_ 155 DriverDoorAjarRawValSts "CBC_PT6_Pkt";
BA_ "FlexKomSigLaenge" SG_ 155 DriverDoorAjarRawValSts 64;
BA_ "FlexKomSID" SG_ 155 DriverDoorAjarRawValSts 1943;
BA_ "FlexKomIsMotorola" SG_ 155 DriverDoorAjarRawValSts 1;
BA_ "FlexKomComment" SG_ 155 DriverDoorAjarRawValSts "CBC_PT6 message packet";
BA_ "GenSigStartValue" SG_ 155 DriverDoorAjarXtionSts 3;
BA_ "GenSigSNA" SG_ 155 DriverDoorAjarXtionSts "3h";
BA_ "GenSigCycleTime" SG_ 155 DriverDoorAjarXtionSts 20;
BA_ "FlexKomSigStartValue" SG_ 155 DriverDoorAjarXtionSts "3FFF0C00000000FFh";
BA_ "FlexKomSigStartPos" SG_ 155 DriverDoorAjarXtionSts 7;
BA_ "FlexKomSigName" SG_ 155 DriverDoorAjarXtionSts "CBC_PT6_Pkt";
BA_ "FlexKomSigLaenge" SG_ 155 DriverDoorAjarXtionSts 64;
BA_ "FlexKomSID" SG_ 155 DriverDoorAjarXtionSts 1943;
BA_ "FlexKomIsMotorola" SG_ 155 DriverDoorAjarXtionSts 1;
BA_ "FlexKomComment" SG_ 155 DriverDoorAjarXtionSts "CBC_PT6 message packet";
BA_ "GenSigSNA" SG_ 155 FuelDrRelSwRawSt "FFh";
BA_ "GenSigCycleTime" SG_ 155 FuelDrRelSwRawSt 20;
BA_ "FlexKomSigStartValue" SG_ 155 FuelDrRelSwRawSt "3FFF0C00000000FFh";
BA_ "FlexKomSigStartPos" SG_ 155 FuelDrRelSwRawSt 7;
BA_ "FlexKomSigName" SG_ 155 FuelDrRelSwRawSt "CBC_PT6_Pkt";
BA_ "FlexKomSigLaenge" SG_ 155 FuelDrRelSwRawSt 64;
BA_ "FlexKomSID" SG_ 155 FuelDrRelSwRawSt 1943;
BA_ "FlexKomIsMotorola" SG_ 155 FuelDrRelSwRawSt 1;
BA_ "FlexKomComment" SG_ 155 FuelDrRelSwRawSt "CBC_PT6 message packet";
BA_ "GenSigSNA" SG_ 155 LeakCheckTimerExpired "3h";
BA_ "GenSigCycleTime" SG_ 155 LeakCheckTimerExpired 20;
BA_ "FlexKomSigStartValue" SG_ 155 LeakCheckTimerExpired "3FFF0C00000000FFh";
BA_ "FlexKomSigStartPos" SG_ 155 LeakCheckTimerExpired 7;
BA_ "FlexKomSigName" SG_ 155 LeakCheckTimerExpired "CBC_PT6_Pkt";
BA_ "FlexKomSigLaenge" SG_ 155 LeakCheckTimerExpired 64;
BA_ "FlexKomSID" SG_ 155 LeakCheckTimerExpired 1943;
BA_ "FlexKomIsMotorola" SG_ 155 LeakCheckTimerExpired 1;
BA_ "FlexKomComment" SG_ 155 LeakCheckTimerExpired "CBC_PT6 message packet";
BA_ "GenSigTimeout_ORC" SG_ 155 PsngrDoorAjarRawValSts 70;
BA_ "GenSigSNA" SG_ 155 PsngrDoorAjarRawValSts "Fh";
BA_ "GenSigCycleTime" SG_ 155 PsngrDoorAjarRawValSts 20;
BA_ "FlexKomSigStartValue" SG_ 155 PsngrDoorAjarRawValSts "3FFF0C00000000FFh";
BA_ "FlexKomSigStartPos" SG_ 155 PsngrDoorAjarRawValSts 7;
BA_ "FlexKomSigName" SG_ 155 PsngrDoorAjarRawValSts "CBC_PT6_Pkt";
BA_ "FlexKomSigLaenge" SG_ 155 PsngrDoorAjarRawValSts 64;
BA_ "FlexKomSID" SG_ 155 PsngrDoorAjarRawValSts 1943;
BA_ "FlexKomIsMotorola" SG_ 155 PsngrDoorAjarRawValSts 1;
BA_ "FlexKomComment" SG_ 155 PsngrDoorAjarRawValSts "CBC_PT6 message packet";
BA_ "GenSigStartValue" SG_ 155 PsngrDoorAjarXtionSts 3;
BA_ "GenSigSNA" SG_ 155 PsngrDoorAjarXtionSts "3h";
BA_ "GenSigCycleTime" SG_ 155 PsngrDoorAjarXtionSts 20;
BA_ "FlexKomSigStartValue" SG_ 155 PsngrDoorAjarXtionSts "3FFF0C00000000FFh";
BA_ "FlexKomSigStartPos" SG_ 155 PsngrDoorAjarXtionSts 7;
BA_ "FlexKomSigName" SG_ 155 PsngrDoorAjarXtionSts "CBC_PT6_Pkt";
BA_ "FlexKomSigLaenge" SG_ 155 PsngrDoorAjarXtionSts 64;
BA_ "FlexKomSID" SG_ 155 PsngrDoorAjarXtionSts 1943;
BA_ "FlexKomIsMotorola" SG_ 155 PsngrDoorAjarXtionSts 1;
BA_ "FlexKomComment" SG_ 155 PsngrDoorAjarXtionSts "CBC_PT6 message packet";
BA_ "GenSigSNA" SG_ 155 RefuelRequest "3h";
BA_ "GenSigCycleTime" SG_ 155 RefuelRequest 20;
BA_ "FlexKomSigStartValue" SG_ 155 RefuelRequest "3FFF0C00000000FFh";
BA_ "FlexKomSigStartPos" SG_ 155 RefuelRequest 7;
BA_ "FlexKomSigName" SG_ 155 RefuelRequest "CBC_PT6_Pkt";
BA_ "FlexKomSigLaenge" SG_ 155 RefuelRequest 64;
BA_ "FlexKomSID" SG_ 155 RefuelRequest 1943;
BA_ "FlexKomIsMotorola" SG_ 155 RefuelRequest 1;
BA_ "FlexKomComment" SG_ 155 RefuelRequest "CBC_PT6 message packet";
BA_ "GenSigSNA" SG_ 307 AM_ECM_Trace "3h";
BA_ "GenSigCycleTime" SG_ 307 AM_ECM_Trace 100;
BA_ "FlexKomSigStartValue" SG_ 307 AM_ECM_Trace "00h";
BA_ "FlexKomSigStartPos" SG_ 307 AM_ECM_Trace 23;
BA_ "FlexKomSigName" SG_ 307 AM_ECM_Trace "AM_ECM_Trace";
BA_ "FlexKomSigLaenge" SG_ 307 AM_ECM_Trace 2;
BA_ "FlexKomSID" SG_ 307 AM_ECM_Trace 1942;
BA_ "FlexKomIsMotorola" SG_ 307 AM_ECM_Trace 1;
BA_ "FlexKomComment" SG_ 307 AM_ECM_Trace "Aftermarket ECM trace";
BA_ "GenSigSNA" SG_ 307 DRV_DR_LOCKING "1h";
BA_ "GenSigCycleTime" SG_ 307 DRV_DR_LOCKING 100;
BA_ "FlexKomSigStartValue" SG_ 307 DRV_DR_LOCKING "00000000h";
BA_ "FlexKomSigStartPos" SG_ 307 DRV_DR_LOCKING 39;
BA_ "FlexKomSigName" SG_ 307 DRV_DR_LOCKING "Door_Lock_Sts";
BA_ "FlexKomSigLaenge" SG_ 307 DRV_DR_LOCKING 32;
BA_ "FlexKomSID" SG_ 307 DRV_DR_LOCKING 2853;
BA_ "FlexKomIsMotorola" SG_ 307 DRV_DR_LOCKING 1;
BA_ "FlexKomComment" SG_ 307 DRV_DR_LOCKING "Door Lock Last Status";
BA_ "GenSigSNA" SG_ 307 DRV_DR_UNLOCKING "1h";
BA_ "GenSigCycleTime" SG_ 307 DRV_DR_UNLOCKING 100;
BA_ "FlexKomSigStartValue" SG_ 307 DRV_DR_UNLOCKING "00000000h";
BA_ "FlexKomSigStartPos" SG_ 307 DRV_DR_UNLOCKING 39;
BA_ "FlexKomSigName" SG_ 307 DRV_DR_UNLOCKING "Door_Lock_Sts";
BA_ "FlexKomSigLaenge" SG_ 307 DRV_DR_UNLOCKING 32;
BA_ "FlexKomSID" SG_ 307 DRV_DR_UNLOCKING 2853;
BA_ "FlexKomIsMotorola" SG_ 307 DRV_DR_UNLOCKING 1;
BA_ "FlexKomComment" SG_ 307 DRV_DR_UNLOCKING "Door Lock Last Status";
BA_ "GenSigSNA" SG_ 307 DoorLockLastElSts "3h";
BA_ "GenSigCycleTime" SG_ 307 DoorLockLastElSts 100;
BA_ "FlexKomSigStartValue" SG_ 307 DoorLockLastElSts "00000000h";
BA_ "FlexKomSigStartPos" SG_ 307 DoorLockLastElSts 39;
BA_ "FlexKomSigName" SG_ 307 DoorLockLastElSts "Door_Lock_Sts";
BA_ "FlexKomSigLaenge" SG_ 307 DoorLockLastElSts 32;
BA_ "FlexKomSID" SG_ 307 DoorLockLastElSts 2853;
BA_ "FlexKomIsMotorola" SG_ 307 DoorLockLastElSts 1;
BA_ "FlexKomComment" SG_ 307 DoorLockLastElSts "Door Lock Last Status";
BA_ "GenSigSNA" SG_ 607 CBC_Reset_Flag "3h";
BA_ "GenSigSendType" SG_ 607 CBC_Reset_Flag 5;
BA_ "GenSigCycleTime" SG_ 607 CBC_Reset_Flag 1000;
BA_ "FlexKomSigStartValue" SG_ 607 CBC_Reset_Flag "00h";
BA_ "FlexKomSigStartPos" SG_ 607 CBC_Reset_Flag 17;
BA_ "FlexKomSigName" SG_ 607 CBC_Reset_Flag "CBC_Reset_Flag";
BA_ "FlexKomSigLaenge" SG_ 607 CBC_Reset_Flag 2;
BA_ "FlexKomSID" SG_ 607 CBC_Reset_Flag 2530;
BA_ "FlexKomIsMotorola" SG_ 607 CBC_Reset_Flag 1;
BA_ "FlexKomComment" SG_ 607 CBC_Reset_Flag "CBC reset flag";
BA_ "GenSigTimeout_IC" SG_ 607 ESLLockFailSts_BCM 10500;
BA_ "GenSigSNA" SG_ 607 ESLLockFailSts_BCM "0h";
BA_ "GenSigSendType" SG_ 607 ESLLockFailSts_BCM 5;
BA_ "GenSigCycleTime" SG_ 607 ESLLockFailSts_BCM 1000;
BA_ "FlexKomSigStartValue" SG_ 607 ESLLockFailSts_BCM "00h";
BA_ "FlexKomSigStartPos" SG_ 607 ESLLockFailSts_BCM 40;
BA_ "FlexKomSigName" SG_ 607 ESLLockFailSts_BCM "ESLLockFailSts_BCM";
BA_ "FlexKomSigLaenge" SG_ 607 ESLLockFailSts_BCM 1;
BA_ "FlexKomSID" SG_ 607 ESLLockFailSts_BCM 2369;
BA_ "FlexKomIsMotorola" SG_ 607 ESLLockFailSts_BCM 1;
BA_ "FlexKomComment" SG_ 607 ESLLockFailSts_BCM "Display info on failed lock; Failed = [1]";
BA_ "GenSigTimeout_IC" SG_ 607 ESLUnlockFailSts_BCM 10500;
BA_ "GenSigSNA" SG_ 607 ESLUnlockFailSts_BCM "0h";
BA_ "GenSigSendType" SG_ 607 ESLUnlockFailSts_BCM 5;
BA_ "GenSigCycleTime" SG_ 607 ESLUnlockFailSts_BCM 1000;
BA_ "FlexKomSigStartValue" SG_ 607 ESLUnlockFailSts_BCM "00h";
BA_ "FlexKomSigStartPos" SG_ 607 ESLUnlockFailSts_BCM 41;
BA_ "FlexKomSigName" SG_ 607 ESLUnlockFailSts_BCM "ESLUnlockFailSts_BCM";
BA_ "FlexKomSigLaenge" SG_ 607 ESLUnlockFailSts_BCM 1;
BA_ "FlexKomSID" SG_ 607 ESLUnlockFailSts_BCM 2370;
BA_ "FlexKomIsMotorola" SG_ 607 ESLUnlockFailSts_BCM 1;
BA_ "FlexKomComment" SG_ 607 ESLUnlockFailSts_BCM "Display info on failed unlock; Failed = [1]";
BA_ "GenSigTimeout_TBM" SG_ 607 EngineOffTimer 10500;
BA_ "GenSigStartValue" SG_ 607 EngineOffTimer 4095;
BA_ "GenSigSNA" SG_ 607 EngineOffTimer "FFFh";
BA_ "GenSigCycleTime" SG_ 607 EngineOffTimer 1000;
BA_ "FlexKomSigStartValue" SG_ 607 EngineOffTimer "0FFFh";
BA_ "FlexKomSigStartPos" SG_ 607 EngineOffTimer 55;
BA_ "FlexKomSigName" SG_ 607 EngineOffTimer "EngineOffTimer";
BA_ "FlexKomSigLaenge" SG_ 607 EngineOffTimer 16;
BA_ "FlexKomSID" SG_ 607 EngineOffTimer 1906;
BA_ "FlexKomIsMotorola" SG_ 607 EngineOffTimer 1;
BA_ "FlexKomComment" SG_ 607 EngineOffTimer "Engine off timer - engine off ignition NOT lock.";
BA_ "GenSigTimeout_IC" SG_ 607 GlobDrvMdSts 10500;
BA_ "GenSigSNA" SG_ 607 GlobDrvMdSts "1Fh";
BA_ "GenSigSendType" SG_ 607 GlobDrvMdSts 5;
BA_ "GenSigCycleTime" SG_ 607 GlobDrvMdSts 1000;
BA_ "FlexKomSigStartValue" SG_ 607 GlobDrvMdSts "00h";
BA_ "FlexKomSigStartPos" SG_ 607 GlobDrvMdSts 36;
BA_ "FlexKomSigName" SG_ 607 GlobDrvMdSts "GlobDrvMdSts";
BA_ "FlexKomSigLaenge" SG_ 607 GlobDrvMdSts 5;
BA_ "FlexKomSID" SG_ 607 GlobDrvMdSts 2392;
BA_ "FlexKomIsMotorola" SG_ 607 GlobDrvMdSts 1;
BA_ "FlexKomComment" SG_ 607 GlobDrvMdSts "Global drive mode status";
BA_ "GenSigTimeout_IC" SG_ 607 HRD_TOP_OFF 10500;
BA_ "GenSigSNA" SG_ 607 HRD_TOP_OFF "0h";
BA_ "GenSigSendType" SG_ 607 HRD_TOP_OFF 5;
BA_ "GenSigCycleTime" SG_ 607 HRD_TOP_OFF 1000;
BA_ "FlexKomSigStartValue" SG_ 607 HRD_TOP_OFF "00h";
BA_ "FlexKomSigStartPos" SG_ 607 HRD_TOP_OFF 24;
BA_ "FlexKomSigName" SG_ 607 HRD_TOP_OFF "HRD_TOP_OFF";
BA_ "FlexKomSigLaenge" SG_ 607 HRD_TOP_OFF 1;
BA_ "FlexKomSID" SG_ 607 HRD_TOP_OFF 2637;
BA_ "FlexKomIsMotorola" SG_ 607 HRD_TOP_OFF 1;
BA_ "FlexKomComment" SG_ 607 HRD_TOP_OFF "Removable hard top is off";
BA_ "GenSigTimeout_IC" SG_ 607 MoveWheelSts 10500;
BA_ "GenSigSNA" SG_ 607 MoveWheelSts "0h";
BA_ "GenSigSendType" SG_ 607 MoveWheelSts 5;
BA_ "GenSigCycleTime" SG_ 607 MoveWheelSts 1000;
BA_ "FlexKomSigStartValue" SG_ 607 MoveWheelSts "00h";
BA_ "FlexKomSigStartPos" SG_ 607 MoveWheelSts 52;
BA_ "FlexKomSigName" SG_ 607 MoveWheelSts "MoveWheelSts";
BA_ "FlexKomSigLaenge" SG_ 607 MoveWheelSts 1;
BA_ "FlexKomSID" SG_ 607 MoveWheelSts 2371;
BA_ "FlexKomIsMotorola" SG_ 607 MoveWheelSts 1;
BA_ "FlexKomComment" SG_ 607 MoveWheelSts "Display message to move steering wheel; Active = [";
BA_ "GenSigSNA" SG_ 607 PNC_ALM_ACT "0h";
BA_ "GenSigSendType" SG_ 607 PNC_ALM_ACT 5;
BA_ "GenSigCycleTime" SG_ 607 PNC_ALM_ACT 1000;
BA_ "FlexKomSigStartValue" SG_ 607 PNC_ALM_ACT "00h";
BA_ "FlexKomSigStartPos" SG_ 607 PNC_ALM_ACT 55;
BA_ "FlexKomSigName" SG_ 607 PNC_ALM_ACT "PNC_ALM_ACT";
BA_ "FlexKomSigLaenge" SG_ 607 PNC_ALM_ACT 1;
BA_ "FlexKomSID" SG_ 607 PNC_ALM_ACT 756;
BA_ "FlexKomIsMotorola" SG_ 607 PNC_ALM_ACT 1;
BA_ "FlexKomComment" SG_ 607 PNC_ALM_ACT "Panic alarm active; [1] = True";
BA_ "GenSigSNA" SG_ 319 CBCSAMFailSts "0h";
BA_ "GenSigCycleTime" SG_ 319 CBCSAMFailSts 100;
BA_ "FlexKomSigStartValue" SG_ 319 CBCSAMFailSts "00h";
BA_ "FlexKomSigStartPos" SG_ 319 CBCSAMFailSts 39;
BA_ "FlexKomSigName" SG_ 319 CBCSAMFailSts "CBCSAMFailSts";
BA_ "FlexKomSigLaenge" SG_ 319 CBCSAMFailSts 1;
BA_ "FlexKomSID" SG_ 319 CBCSAMFailSts 2648;
BA_ "FlexKomIsMotorola" SG_ 319 CBCSAMFailSts 1;
BA_ "FlexKomComment" SG_ 319 CBCSAMFailSts "Fault present in BCM related to the SAM strategy";
BA_ "RID" SG_ 319 CurrBattFailStatus "5107";
BA_ "GenSigSNA" SG_ 319 CurrBattFailStatus "0h";
BA_ "GenSigCycleTime" SG_ 319 CurrBattFailStatus 100;
BA_ "FlexKomSigStartValue" SG_ 319 CurrBattFailStatus "00h";
BA_ "FlexKomSigStartPos" SG_ 319 CurrBattFailStatus 35;
BA_ "FlexKomSigName" SG_ 319 CurrBattFailStatus "CurrBattFailStatus";
BA_ "FlexKomSigLaenge" SG_ 319 CurrBattFailStatus 1;
BA_ "FlexKomSID" SG_ 319 CurrBattFailStatus 2655;
BA_ "FlexKomIsMotorola" SG_ 319 CurrBattFailStatus 1;
BA_ "FlexKomComment" SG_ 319 CurrBattFailStatus "Failure Status of Current meas. (internal defect)";
BA_ "RID" SG_ 319 IBS3_Error_Internal "5130";
BA_ "GenSigSNA" SG_ 319 IBS3_Error_Internal "0h";
BA_ "GenSigCycleTime" SG_ 319 IBS3_Error_Internal 100;
BA_ "FlexKomSigStartValue" SG_ 319 IBS3_Error_Internal "00h";
BA_ "FlexKomSigStartPos" SG_ 319 IBS3_Error_Internal 37;
BA_ "FlexKomSigName" SG_ 319 IBS3_Error_Internal "IBS3_Error_Internal";
BA_ "FlexKomSigLaenge" SG_ 319 IBS3_Error_Internal 1;
BA_ "FlexKomSID" SG_ 319 IBS3_Error_Internal 2653;
BA_ "FlexKomIsMotorola" SG_ 319 IBS3_Error_Internal 1;
BA_ "FlexKomComment" SG_ 319 IBS3_Error_Internal "Error in IBS calibration data; No Error = [0], Err";
BA_ "RID" SG_ 319 IBS3_Ibatt "5110";
BA_ "GenSigStartValue" SG_ 319 IBS3_Ibatt 65535;
BA_ "GenSigSNA" SG_ 319 IBS3_Ibatt "FFFFh";
BA_ "GenSigCycleTime" SG_ 319 IBS3_Ibatt 100;
BA_ "FlexKomSigStartValue" SG_ 319 IBS3_Ibatt "FFFFh";
BA_ "FlexKomSigStartPos" SG_ 319 IBS3_Ibatt 23;
BA_ "FlexKomSigName" SG_ 319 IBS3_Ibatt "IBS3_Ibatt";
BA_ "FlexKomSigLaenge" SG_ 319 IBS3_Ibatt 16;
BA_ "FlexKomSID" SG_ 319 IBS3_Ibatt 2650;
BA_ "FlexKomIsMotorola" SG_ 319 IBS3_Ibatt 1;
BA_ "FlexKomComment" SG_ 319 IBS3_Ibatt "Battery current";
BA_ "RID" SG_ 319 IBS3_Vbatt "5106";
BA_ "GenSigStartValue" SG_ 319 IBS3_Vbatt 511;
BA_ "GenSigSNA" SG_ 319 IBS3_Vbatt "1FFh";
BA_ "GenSigCycleTime" SG_ 319 IBS3_Vbatt 100;
BA_ "FlexKomSigStartValue" SG_ 319 IBS3_Vbatt "01FFh";
BA_ "FlexKomSigStartPos" SG_ 319 IBS3_Vbatt 39;
BA_ "FlexKomSigName" SG_ 319 IBS3_Vbatt "IBS3_Vbatt";
BA_ "FlexKomSigLaenge" SG_ 319 IBS3_Vbatt 16;
BA_ "FlexKomSID" SG_ 319 IBS3_Vbatt 2651;
BA_ "FlexKomIsMotorola" SG_ 319 IBS3_Vbatt 1;
BA_ "FlexKomComment" SG_ 319 IBS3_Vbatt "Battery voltage measured at the terminals";
BA_ "GenSigTimeout_IC" SG_ 319 Pitch_Angle 1050;
BA_ "GenSigStartValue" SG_ 319 Pitch_Angle 90;
BA_ "GenSigSNA" SG_ 319 Pitch_Angle "FFh";
BA_ "GenSigCycleTime" SG_ 319 Pitch_Angle 100;
BA_ "FlexKomSigStartValue" SG_ 319 Pitch_Angle "5Ah";
BA_ "FlexKomSigStartPos" SG_ 319 Pitch_Angle 7;
BA_ "FlexKomSigName" SG_ 319 Pitch_Angle "Pitch_Angle";
BA_ "FlexKomSigLaenge" SG_ 319 Pitch_Angle 8;
BA_ "FlexKomSID" SG_ 319 Pitch_Angle 1963;
BA_ "FlexKomIsMotorola" SG_ 319 Pitch_Angle 1;
BA_ "FlexKomComment" SG_ 319 Pitch_Angle "Pitch angle; Disable = [FE]";
BA_ "GenSigTimeout_IC" SG_ 319 Roll_Angle 1050;
BA_ "GenSigStartValue" SG_ 319 Roll_Angle 90;
BA_ "GenSigSNA" SG_ 319 Roll_Angle "FFh";
BA_ "GenSigCycleTime" SG_ 319 Roll_Angle 100;
BA_ "FlexKomSigStartValue" SG_ 319 Roll_Angle "5Ah";
BA_ "FlexKomSigStartPos" SG_ 319 Roll_Angle 15;
BA_ "FlexKomSigName" SG_ 319 Roll_Angle "Roll_Angle";
BA_ "FlexKomSigLaenge" SG_ 319 Roll_Angle 8;
BA_ "FlexKomSID" SG_ 319 Roll_Angle 1962;
BA_ "FlexKomIsMotorola" SG_ 319 Roll_Angle 1;
BA_ "FlexKomComment" SG_ 319 Roll_Angle "Roll angle";
BA_ "RID" SG_ 319 RsErrIBS3 "5135";
BA_ "GenSigSNA" SG_ 319 RsErrIBS3 "0h";
BA_ "GenSigCycleTime" SG_ 319 RsErrIBS3 100;
BA_ "FlexKomSigStartValue" SG_ 319 RsErrIBS3 "00h";
BA_ "FlexKomSigStartPos" SG_ 319 RsErrIBS3 38;
BA_ "FlexKomSigName" SG_ 319 RsErrIBS3 "RsErrIBS3";
BA_ "FlexKomSigLaenge" SG_ 319 RsErrIBS3 1;
BA_ "FlexKomSID" SG_ 319 RsErrIBS3 2652;
BA_ "FlexKomIsMotorola" SG_ 319 RsErrIBS3 1;
BA_ "FlexKomComment" SG_ 319 RsErrIBS3 "Response Error IBS; Error=[1]";
BA_ "RID" SG_ 319 VoltBattFailStatus "5083";
BA_ "GenSigSNA" SG_ 319 VoltBattFailStatus "0h";
BA_ "GenSigCycleTime" SG_ 319 VoltBattFailStatus 100;
BA_ "FlexKomSigStartValue" SG_ 319 VoltBattFailStatus "00h";
BA_ "FlexKomSigStartPos" SG_ 319 VoltBattFailStatus 36;
BA_ "FlexKomSigName" SG_ 319 VoltBattFailStatus "VoltBattFailStatus";
BA_ "FlexKomSigLaenge" SG_ 319 VoltBattFailStatus 1;
BA_ "FlexKomSID" SG_ 319 VoltBattFailStatus 2654;
BA_ "FlexKomIsMotorola" SG_ 319 VoltBattFailStatus 1;
BA_ "FlexKomComment" SG_ 319 VoltBattFailStatus "Failure Status of Voltage meas. (internal defect)";
BA_ "GenSigSNA" SG_ 319 VoltageMax "0h";
BA_ "GenSigCycleTime" SG_ 319 VoltageMax 100;
BA_ "FlexKomSigStartValue" SG_ 319 VoltageMax "0000h";
BA_ "FlexKomSigStartPos" SG_ 319 VoltageMax 55;
BA_ "FlexKomSigName" SG_ 319 VoltageMax "VoltageRange";
BA_ "FlexKomSigLaenge" SG_ 319 VoltageMax 16;
BA_ "FlexKomSID" SG_ 319 VoltageMax 2647;
BA_ "FlexKomIsMotorola" SG_ 319 VoltageMax 1;
BA_ "FlexKomComment" SG_ 319 VoltageMax "Voltage range packet related to SAM strategy";
BA_ "GenSigSNA" SG_ 319 VoltageMin "0h";
BA_ "GenSigCycleTime" SG_ 319 VoltageMin 100;
BA_ "FlexKomSigStartValue" SG_ 319 VoltageMin "0000h";
BA_ "FlexKomSigStartPos" SG_ 319 VoltageMin 55;
BA_ "FlexKomSigName" SG_ 319 VoltageMin "VoltageRange";
BA_ "FlexKomSigLaenge" SG_ 319 VoltageMin 16;
BA_ "FlexKomSID" SG_ 319 VoltageMin 2647;
BA_ "FlexKomIsMotorola" SG_ 319 VoltageMin 1;
BA_ "FlexKomComment" SG_ 319 VoltageMin "Voltage range packet related to SAM strategy";
BA_ "GenSigTimeout_TBM" SG_ 456 VTA_STAT 5250;
BA_ "GenSigSNA" SG_ 456 VTA_STAT "7h";
BA_ "GenSigSendType" SG_ 456 VTA_STAT 5;
BA_ "GenSigCycleTime" SG_ 456 VTA_STAT 500;
BA_ "FlexKomSigStartValue" SG_ 456 VTA_STAT "00000000h";
BA_ "FlexKomSigStartPos" SG_ 456 VTA_STAT 7;
BA_ "FlexKomSigName" SG_ 456 VTA_STAT "VTA_PKT";
BA_ "FlexKomSigLaenge" SG_ 456 VTA_STAT 32;
BA_ "FlexKomSID" SG_ 456 VTA_STAT 1207;
BA_ "FlexKomIsMotorola" SG_ 456 VTA_STAT 1;
BA_ "FlexKomComment" SG_ 456 VTA_STAT "Vehicle theft alarm packet";
BA_ "RID" SG_ 788 CFG_FEATURE "1144";
BA_ "GenSigSNA" SG_ 788 CFG_FEATURE "0h";
BA_ "GenSigSendType" SG_ 788 CFG_FEATURE 2;
BA_ "GenSigCycleTimeActive" SG_ 788 CFG_FEATURE 50;
BA_ "FlexKomSigStartValue" SG_ 788 CFG_FEATURE "000000h";
BA_ "FlexKomSigStartPos" SG_ 788 CFG_FEATURE 7;
BA_ "FlexKomSigName" SG_ 788 CFG_FEATURE "CFG_RQ";
BA_ "FlexKomSigLaenge" SG_ 788 CFG_FEATURE 24;
BA_ "FlexKomSID" SG_ 788 CFG_FEATURE 442;
BA_ "FlexKomIsMotorola" SG_ 788 CFG_FEATURE 1;
BA_ "FlexKomComment" SG_ 788 CFG_FEATURE "Configurable display request";
BA_ "RID" SG_ 788 CFG_SET "1173";
BA_ "GenSigSNA" SG_ 788 CFG_SET "0h";
BA_ "GenSigSendType" SG_ 788 CFG_SET 2;
BA_ "GenSigCycleTimeActive" SG_ 788 CFG_SET 50;
BA_ "FlexKomSigStartValue" SG_ 788 CFG_SET "000000h";
BA_ "FlexKomSigStartPos" SG_ 788 CFG_SET 7;
BA_ "FlexKomSigName" SG_ 788 CFG_SET "CFG_RQ";
BA_ "FlexKomSigLaenge" SG_ 788 CFG_SET 24;
BA_ "FlexKomSID" SG_ 788 CFG_SET 442;
BA_ "FlexKomIsMotorola" SG_ 788 CFG_SET 1;
BA_ "FlexKomComment" SG_ 788 CFG_SET "Configurable display request";
BA_ "RID" SG_ 788 CFG_STAT_RQ "1228";
BA_ "GenSigSNA" SG_ 788 CFG_STAT_RQ "0h";
BA_ "GenSigSendType" SG_ 788 CFG_STAT_RQ 2;
BA_ "GenSigCycleTimeActive" SG_ 788 CFG_STAT_RQ 50;
BA_ "FlexKomSigStartValue" SG_ 788 CFG_STAT_RQ "000000h";
BA_ "FlexKomSigStartPos" SG_ 788 CFG_STAT_RQ 7;
BA_ "FlexKomSigName" SG_ 788 CFG_STAT_RQ "CFG_RQ";
BA_ "FlexKomSigLaenge" SG_ 788 CFG_STAT_RQ 24;
BA_ "FlexKomSID" SG_ 788 CFG_STAT_RQ 442;
BA_ "FlexKomIsMotorola" SG_ 788 CFG_STAT_RQ 1;
BA_ "FlexKomComment" SG_ 788 CFG_STAT_RQ "Configurable display request";
BA_ "RID" SG_ 805 Next_Charge_EndDay "6712";
BA_ "GenSigSNA" SG_ 805 Next_Charge_EndDay "Fh";
BA_ "GenSigSendType" SG_ 805 Next_Charge_EndDay 5;
BA_ "GenSigCycleTime" SG_ 805 Next_Charge_EndDay 1000;
BA_ "FlexKomSigStartValue" SG_ 805 Next_Charge_EndDay "0000000000000000h";
BA_ "FlexKomSigStartPos" SG_ 805 Next_Charge_EndDay 7;
BA_ "FlexKomSigName" SG_ 805 Next_Charge_EndDay "CHARGE_SCHEDULE_NEXT";
BA_ "FlexKomSigLaenge" SG_ 805 Next_Charge_EndDay 64;
BA_ "FlexKomSID" SG_ 805 Next_Charge_EndDay 3103;
BA_ "FlexKomIsMotorola" SG_ 805 Next_Charge_EndDay 1;
BA_ "FlexKomComment" SG_ 805 Next_Charge_EndDay "CHARGE_SCHEDULE_NEXT";
BA_ "RID" SG_ 805 Next_Charge_End_Time_Hr "6708";
BA_ "GenSigSNA" SG_ 805 Next_Charge_End_Time_Hr "1Fh";
BA_ "GenSigSendType" SG_ 805 Next_Charge_End_Time_Hr 5;
BA_ "GenSigCycleTime" SG_ 805 Next_Charge_End_Time_Hr 1000;
BA_ "FlexKomSigStartValue" SG_ 805 Next_Charge_End_Time_Hr "0000000000000000h";
BA_ "FlexKomSigStartPos" SG_ 805 Next_Charge_End_Time_Hr 7;
BA_ "FlexKomSigName" SG_ 805 Next_Charge_End_Time_Hr "CHARGE_SCHEDULE_NEXT";
BA_ "FlexKomSigLaenge" SG_ 805 Next_Charge_End_Time_Hr 64;
BA_ "FlexKomSID" SG_ 805 Next_Charge_End_Time_Hr 3103;
BA_ "FlexKomIsMotorola" SG_ 805 Next_Charge_End_Time_Hr 1;
BA_ "FlexKomComment" SG_ 805 Next_Charge_End_Time_Hr "CHARGE_SCHEDULE_NEXT";
BA_ "RID" SG_ 805 Next_Charge_End_Time_Min "6707";
BA_ "GenSigSNA" SG_ 805 Next_Charge_End_Time_Min "Fh";
BA_ "GenSigSendType" SG_ 805 Next_Charge_End_Time_Min 5;
BA_ "GenSigCycleTime" SG_ 805 Next_Charge_End_Time_Min 1000;
BA_ "FlexKomSigStartValue" SG_ 805 Next_Charge_End_Time_Min "0000000000000000h";
BA_ "FlexKomSigStartPos" SG_ 805 Next_Charge_End_Time_Min 7;
BA_ "FlexKomSigName" SG_ 805 Next_Charge_End_Time_Min "CHARGE_SCHEDULE_NEXT";
BA_ "FlexKomSigLaenge" SG_ 805 Next_Charge_End_Time_Min 64;
BA_ "FlexKomSID" SG_ 805 Next_Charge_End_Time_Min 3103;
BA_ "FlexKomIsMotorola" SG_ 805 Next_Charge_End_Time_Min 1;
BA_ "FlexKomComment" SG_ 805 Next_Charge_End_Time_Min "CHARGE_SCHEDULE_NEXT";
BA_ "RID" SG_ 805 Next_Charge_StartDay "6716";
BA_ "GenSigSNA" SG_ 805 Next_Charge_StartDay "Fh";
BA_ "GenSigSendType" SG_ 805 Next_Charge_StartDay 5;
BA_ "GenSigCycleTime" SG_ 805 Next_Charge_StartDay 1000;
BA_ "FlexKomSigStartValue" SG_ 805 Next_Charge_StartDay "0000000000000000h";
BA_ "FlexKomSigStartPos" SG_ 805 Next_Charge_StartDay 7;
BA_ "FlexKomSigName" SG_ 805 Next_Charge_StartDay "CHARGE_SCHEDULE_NEXT";
BA_ "FlexKomSigLaenge" SG_ 805 Next_Charge_StartDay 64;
BA_ "FlexKomSID" SG_ 805 Next_Charge_StartDay 3103;
BA_ "FlexKomIsMotorola" SG_ 805 Next_Charge_StartDay 1;
BA_ "FlexKomComment" SG_ 805 Next_Charge_StartDay "CHARGE_SCHEDULE_NEXT";
BA_ "RID" SG_ 805 Next_Charge_Start_Time_Hr "6718";
BA_ "GenSigSNA" SG_ 805 Next_Charge_Start_Time_Hr "1Fh";
BA_ "GenSigSendType" SG_ 805 Next_Charge_Start_Time_Hr 5;
BA_ "GenSigCycleTime" SG_ 805 Next_Charge_Start_Time_Hr 1000;
BA_ "FlexKomSigStartValue" SG_ 805 Next_Charge_Start_Time_Hr "0000000000000000h";
BA_ "FlexKomSigStartPos" SG_ 805 Next_Charge_Start_Time_Hr 7;
BA_ "FlexKomSigName" SG_ 805 Next_Charge_Start_Time_Hr "CHARGE_SCHEDULE_NEXT";
BA_ "FlexKomSigLaenge" SG_ 805 Next_Charge_Start_Time_Hr 64;
BA_ "FlexKomSID" SG_ 805 Next_Charge_Start_Time_Hr 3103;
BA_ "FlexKomIsMotorola" SG_ 805 Next_Charge_Start_Time_Hr 1;
BA_ "FlexKomComment" SG_ 805 Next_Charge_Start_Time_Hr "CHARGE_SCHEDULE_NEXT";
BA_ "RID" SG_ 805 Next_Charge_Start_Time_Min "6717";
BA_ "GenSigSNA" SG_ 805 Next_Charge_Start_Time_Min "Fh";
BA_ "GenSigSendType" SG_ 805 Next_Charge_Start_Time_Min 5;
BA_ "GenSigCycleTime" SG_ 805 Next_Charge_Start_Time_Min 1000;
BA_ "FlexKomSigStartValue" SG_ 805 Next_Charge_Start_Time_Min "0000000000000000h";
BA_ "FlexKomSigStartPos" SG_ 805 Next_Charge_Start_Time_Min 7;
BA_ "FlexKomSigName" SG_ 805 Next_Charge_Start_Time_Min "CHARGE_SCHEDULE_NEXT";
BA_ "FlexKomSigLaenge" SG_ 805 Next_Charge_Start_Time_Min 64;
BA_ "FlexKomSID" SG_ 805 Next_Charge_Start_Time_Min 3103;
BA_ "FlexKomIsMotorola" SG_ 805 Next_Charge_Start_Time_Min 1;
BA_ "FlexKomComment" SG_ 805 Next_Charge_Start_Time_Min "CHARGE_SCHEDULE_NEXT";
BA_ "RID" SG_ 805 Next_Climate_Day "6706";
BA_ "GenSigSNA" SG_ 805 Next_Climate_Day "Fh";
BA_ "GenSigSendType" SG_ 805 Next_Climate_Day 5;
BA_ "GenSigCycleTime" SG_ 805 Next_Climate_Day 1000;
BA_ "FlexKomSigStartValue" SG_ 805 Next_Climate_Day "0000000000000000h";
BA_ "FlexKomSigStartPos" SG_ 805 Next_Climate_Day 7;
BA_ "FlexKomSigName" SG_ 805 Next_Climate_Day "CHARGE_SCHEDULE_NEXT";
BA_ "FlexKomSigLaenge" SG_ 805 Next_Climate_Day 64;
BA_ "FlexKomSID" SG_ 805 Next_Climate_Day 3103;
BA_ "FlexKomIsMotorola" SG_ 805 Next_Climate_Day 1;
BA_ "FlexKomComment" SG_ 805 Next_Climate_Day "CHARGE_SCHEDULE_NEXT";
BA_ "RID" SG_ 805 Next_Climate_Time_Hr "6711";
BA_ "GenSigSNA" SG_ 805 Next_Climate_Time_Hr "1Fh";
BA_ "GenSigSendType" SG_ 805 Next_Climate_Time_Hr 5;
BA_ "GenSigCycleTime" SG_ 805 Next_Climate_Time_Hr 1000;
BA_ "FlexKomSigStartValue" SG_ 805 Next_Climate_Time_Hr "0000000000000000h";
BA_ "FlexKomSigStartPos" SG_ 805 Next_Climate_Time_Hr 7;
BA_ "FlexKomSigName" SG_ 805 Next_Climate_Time_Hr "CHARGE_SCHEDULE_NEXT";
BA_ "FlexKomSigLaenge" SG_ 805 Next_Climate_Time_Hr 64;
BA_ "FlexKomSID" SG_ 805 Next_Climate_Time_Hr 3103;
BA_ "FlexKomIsMotorola" SG_ 805 Next_Climate_Time_Hr 1;
BA_ "FlexKomComment" SG_ 805 Next_Climate_Time_Hr "CHARGE_SCHEDULE_NEXT";
BA_ "RID" SG_ 805 Next_Climate_Time_Min "6710";
BA_ "GenSigSNA" SG_ 805 Next_Climate_Time_Min "Fh";
BA_ "GenSigSendType" SG_ 805 Next_Climate_Time_Min 5;
BA_ "GenSigCycleTime" SG_ 805 Next_Climate_Time_Min 1000;
BA_ "FlexKomSigStartValue" SG_ 805 Next_Climate_Time_Min "0000000000000000h";
BA_ "FlexKomSigStartPos" SG_ 805 Next_Climate_Time_Min 7;
BA_ "FlexKomSigName" SG_ 805 Next_Climate_Time_Min "CHARGE_SCHEDULE_NEXT";
BA_ "FlexKomSigLaenge" SG_ 805 Next_Climate_Time_Min 64;
BA_ "FlexKomSID" SG_ 805 Next_Climate_Time_Min 3103;
BA_ "FlexKomIsMotorola" SG_ 805 Next_Climate_Time_Min 1;
BA_ "FlexKomComment" SG_ 805 Next_Climate_Time_Min "CHARGE_SCHEDULE_NEXT";
BA_ "RID" SG_ 856 CMP_DIR "289";
BA_ "GenSigTimeout_IC" SG_ 856 CMP_DIR 10500;
BA_ "GenSigStartValue" SG_ 856 CMP_DIR 15;
BA_ "GenSigSNA" SG_ 856 CMP_DIR "Fh";
BA_ "GenSigCycleTime" SG_ 856 CMP_DIR 1000;
BA_ "FlexKomSigStartValue" SG_ 856 CMP_DIR "0Fh";
BA_ "FlexKomSigStartPos" SG_ 856 CMP_DIR 3;
BA_ "FlexKomSigName" SG_ 856 CMP_DIR "CMP_DIR";
BA_ "FlexKomSigLaenge" SG_ 856 CMP_DIR 4;
BA_ "FlexKomSID" SG_ 856 CMP_DIR 817;
BA_ "FlexKomIsMotorola" SG_ 856 CMP_DIR 1;
BA_ "FlexKomComment" SG_ 856 CMP_DIR "Compass direction (WK/LX)";
BA_ "RID" SG_ 856 CMP_DIR_RAW "341";
BA_ "GenSigTimeout_IC" SG_ 856 CMP_DIR_RAW 10500;
BA_ "GenSigSNA" SG_ 856 CMP_DIR_RAW "0h";
BA_ "GenSigCycleTime" SG_ 856 CMP_DIR_RAW 1000;
BA_ "FlexKomSigStartValue" SG_ 856 CMP_DIR_RAW "0000h";
BA_ "FlexKomSigStartPos" SG_ 856 CMP_DIR_RAW 15;
BA_ "FlexKomSigName" SG_ 856 CMP_DIR_RAW "CMP_DIR_RAW";
BA_ "FlexKomSigLaenge" SG_ 856 CMP_DIR_RAW 16;
BA_ "FlexKomSID" SG_ 856 CMP_DIR_RAW 818;
BA_ "FlexKomIsMotorola" SG_ 856 CMP_DIR_RAW 1;
BA_ "FlexKomComment" SG_ 856 CMP_DIR_RAW "Compass direction raw";
BA_ "RID" SG_ 856 IN_CAL_MD "563";
BA_ "GenSigTimeout_IC" SG_ 856 IN_CAL_MD 10500;
BA_ "GenSigSNA" SG_ 856 IN_CAL_MD "0h";
BA_ "GenSigCycleTime" SG_ 856 IN_CAL_MD 1000;
BA_ "FlexKomSigStartValue" SG_ 856 IN_CAL_MD "00h";
BA_ "FlexKomSigStartPos" SG_ 856 IN_CAL_MD 11;
BA_ "FlexKomSigName" SG_ 856 IN_CAL_MD "IN_CAL_MD";
BA_ "FlexKomSigLaenge" SG_ 856 IN_CAL_MD 1;
BA_ "FlexKomSID" SG_ 856 IN_CAL_MD 814;
BA_ "FlexKomIsMotorola" SG_ 856 IN_CAL_MD 1;
BA_ "FlexKomComment" SG_ 856 IN_CAL_MD "In Calibration Mode";
BA_ "RID" SG_ 856 VAR_VAL "293";
BA_ "GenSigTimeout_IC" SG_ 856 VAR_VAL 10500;
BA_ "GenSigStartValue" SG_ 856 VAR_VAL 15;
BA_ "GenSigSNA" SG_ 856 VAR_VAL "Fh";
BA_ "GenSigCycleTime" SG_ 856 VAR_VAL 1000;
BA_ "FlexKomSigStartValue" SG_ 856 VAR_VAL "0Fh";
BA_ "FlexKomSigStartPos" SG_ 856 VAR_VAL 7;
BA_ "FlexKomSigName" SG_ 856 VAR_VAL "VAR_VAL";
BA_ "FlexKomSigLaenge" SG_ 856 VAR_VAL 4;
BA_ "FlexKomSID" SG_ 856 VAR_VAL 811;
BA_ "FlexKomIsMotorola" SG_ 856 VAR_VAL 1;
BA_ "FlexKomComment" SG_ 856 VAR_VAL "RCM Variance Value";
BA_ "GenSigSNA" SG_ 219 CfgFeature "0h";
BA_ "GenSigSendType" SG_ 219 CfgFeature 2;
BA_ "GenSigCycleTimeActive" SG_ 219 CfgFeature 50;
BA_ "FlexKomSigStartValue" SG_ 219 CfgFeature "000000h";
BA_ "FlexKomSigStartPos" SG_ 219 CfgFeature 7;
BA_ "FlexKomSigName" SG_ 219 CfgFeature "CfgRqIC";
BA_ "FlexKomSigLaenge" SG_ 219 CfgFeature 24;
BA_ "FlexKomSID" SG_ 219 CfgFeature 1563;
BA_ "FlexKomIsMotorola" SG_ 219 CfgFeature 1;
BA_ "FlexKomComment" SG_ 219 CfgFeature "Configurable display request from IC";
BA_ "GenSigSNA" SG_ 219 CfgStatRq "0h";
BA_ "GenSigSendType" SG_ 219 CfgStatRq 2;
BA_ "GenSigCycleTimeActive" SG_ 219 CfgStatRq 50;
BA_ "FlexKomSigStartValue" SG_ 219 CfgStatRq "000000h";
BA_ "FlexKomSigStartPos" SG_ 219 CfgStatRq 7;
BA_ "FlexKomSigName" SG_ 219 CfgStatRq "CfgRqIC";
BA_ "FlexKomSigLaenge" SG_ 219 CfgStatRq 24;
BA_ "FlexKomSID" SG_ 219 CfgStatRq 1563;
BA_ "FlexKomIsMotorola" SG_ 219 CfgStatRq 1;
BA_ "FlexKomComment" SG_ 219 CfgStatRq "Configurable display request from IC";
BA_ "RID" SG_ 848 DateTmDay "1029";
BA_ "GenSigTimeout_TPM" SG_ 848 DateTmDay 15500;
BA_ "GenSigTimeout_RF_HUB" SG_ 848 DateTmDay 10500;
BA_ "GenSigTimeout_IC" SG_ 848 DateTmDay 10500;
BA_ "GenSigStartValue" SG_ 848 DateTmDay 255;
BA_ "GenSigSNA" SG_ 848 DateTmDay "FFh";
BA_ "GenSigCycleTime" SG_ 848 DateTmDay 1000;
BA_ "FlexKomSigStartValue" SG_ 848 DateTmDay "FFFFFFFFh";
BA_ "FlexKomSigStartPos" SG_ 848 DateTmDay 31;
BA_ "FlexKomSigName" SG_ 848 DateTmDay "DATE";
BA_ "FlexKomSigLaenge" SG_ 848 DateTmDay 32;
BA_ "FlexKomSID" SG_ 848 DateTmDay 645;
BA_ "FlexKomIsMotorola" SG_ 848 DateTmDay 1;
BA_ "FlexKomComment" SG_ 848 DateTmDay "DATE";
BA_ "RID" SG_ 848 DateTmFormat "1111";
BA_ "GenSigTimeout_IC" SG_ 848 DateTmFormat 10500;
BA_ "GenSigStartValue" SG_ 848 DateTmFormat 7;
BA_ "GenSigSNA" SG_ 848 DateTmFormat "7h";
BA_ "GenSigCycleTime" SG_ 848 DateTmFormat 1000;
BA_ "FlexKomSigStartValue" SG_ 848 DateTmFormat "07h";
BA_ "FlexKomSigStartPos" SG_ 848 DateTmFormat 58;
BA_ "FlexKomSigName" SG_ 848 DateTmFormat "DateTmFormat";
BA_ "FlexKomSigLaenge" SG_ 848 DateTmFormat 3;
BA_ "FlexKomSID" SG_ 848 DateTmFormat 971;
BA_ "FlexKomIsMotorola" SG_ 848 DateTmFormat 1;
BA_ "FlexKomComment" SG_ 848 DateTmFormat "Date and Time Format";
BA_ "RID" SG_ 848 DateTmHour "1116";
BA_ "GenSigTimeout_RF_HUB" SG_ 848 DateTmHour 10500;
BA_ "GenSigTimeout_IC" SG_ 848 DateTmHour 10500;
BA_ "GenSigStartValue" SG_ 848 DateTmHour 255;
BA_ "GenSigSNA" SG_ 848 DateTmHour "FFh";
BA_ "GenSigCycleTime" SG_ 848 DateTmHour 1000;
BA_ "FlexKomSigStartValue" SG_ 848 DateTmHour "FFFFFFh";
BA_ "FlexKomSigStartPos" SG_ 848 DateTmHour 7;
BA_ "FlexKomSigName" SG_ 848 DateTmHour "Clock";
BA_ "FlexKomSigLaenge" SG_ 848 DateTmHour 24;
BA_ "FlexKomSID" SG_ 848 DateTmHour 398;
BA_ "FlexKomIsMotorola" SG_ 848 DateTmHour 1;
BA_ "FlexKomComment" SG_ 848 DateTmHour "Time of day clock";
BA_ "RID" SG_ 848 DateTmMinute "1174";
BA_ "GenSigTimeout_RF_HUB" SG_ 848 DateTmMinute 10500;
BA_ "GenSigTimeout_IC" SG_ 848 DateTmMinute 10500;
BA_ "GenSigStartValue" SG_ 848 DateTmMinute 255;
BA_ "GenSigSNA" SG_ 848 DateTmMinute "FFh";
BA_ "GenSigCycleTime" SG_ 848 DateTmMinute 1000;
BA_ "FlexKomSigStartValue" SG_ 848 DateTmMinute "FFFFFFh";
BA_ "FlexKomSigStartPos" SG_ 848 DateTmMinute 7;
BA_ "FlexKomSigName" SG_ 848 DateTmMinute "Clock";
BA_ "FlexKomSigLaenge" SG_ 848 DateTmMinute 24;
BA_ "FlexKomSID" SG_ 848 DateTmMinute 398;
BA_ "FlexKomIsMotorola" SG_ 848 DateTmMinute 1;
BA_ "FlexKomComment" SG_ 848 DateTmMinute "Time of day clock";
BA_ "RID" SG_ 848 DateTmMonth "1112";
BA_ "GenSigTimeout_TPM" SG_ 848 DateTmMonth 15500;
BA_ "GenSigTimeout_RF_HUB" SG_ 848 DateTmMonth 10500;
BA_ "GenSigTimeout_IC" SG_ 848 DateTmMonth 10500;
BA_ "GenSigStartValue" SG_ 848 DateTmMonth 255;
BA_ "GenSigSNA" SG_ 848 DateTmMonth "FFh";
BA_ "GenSigCycleTime" SG_ 848 DateTmMonth 1000;
BA_ "FlexKomSigStartValue" SG_ 848 DateTmMonth "FFFFFFFFh";
BA_ "FlexKomSigStartPos" SG_ 848 DateTmMonth 31;
BA_ "FlexKomSigName" SG_ 848 DateTmMonth "DATE";
BA_ "FlexKomSigLaenge" SG_ 848 DateTmMonth 32;
BA_ "FlexKomSID" SG_ 848 DateTmMonth 645;
BA_ "FlexKomIsMotorola" SG_ 848 DateTmMonth 1;
BA_ "FlexKomComment" SG_ 848 DateTmMonth "DATE";
BA_ "RID" SG_ 848 DateTmSec "1071";
BA_ "GenSigTimeout_RF_HUB" SG_ 848 DateTmSec 10500;
BA_ "GenSigTimeout_IC" SG_ 848 DateTmSec 10500;
BA_ "GenSigStartValue" SG_ 848 DateTmSec 255;
BA_ "GenSigSNA" SG_ 848 DateTmSec "FFh";
BA_ "GenSigCycleTime" SG_ 848 DateTmSec 1000;
BA_ "FlexKomSigStartValue" SG_ 848 DateTmSec "FFFFFFh";
BA_ "FlexKomSigStartPos" SG_ 848 DateTmSec 7;
BA_ "FlexKomSigName" SG_ 848 DateTmSec "Clock";
BA_ "FlexKomSigLaenge" SG_ 848 DateTmSec 24;
BA_ "FlexKomSID" SG_ 848 DateTmSec 398;
BA_ "FlexKomIsMotorola" SG_ 848 DateTmSec 1;
BA_ "FlexKomComment" SG_ 848 DateTmSec "Time of day clock";
BA_ "RID" SG_ 848 DateTmYear "1218";
BA_ "GenSigTimeout_TPM" SG_ 848 DateTmYear 15500;
BA_ "GenSigTimeout_RF_HUB" SG_ 848 DateTmYear 10500;
BA_ "GenSigTimeout_IC" SG_ 848 DateTmYear 10500;
BA_ "GenSigStartValue" SG_ 848 DateTmYear 65535;
BA_ "GenSigSNA" SG_ 848 DateTmYear "FFFFh";
BA_ "GenSigCycleTime" SG_ 848 DateTmYear 1000;
BA_ "FlexKomSigStartValue" SG_ 848 DateTmYear "FFFFFFFFh";
BA_ "FlexKomSigStartPos" SG_ 848 DateTmYear 31;
BA_ "FlexKomSigName" SG_ 848 DateTmYear "DATE";
BA_ "FlexKomSigLaenge" SG_ 848 DateTmYear 32;
BA_ "FlexKomSID" SG_ 848 DateTmYear 645;
BA_ "FlexKomIsMotorola" SG_ 848 DateTmYear 1;
BA_ "FlexKomComment" SG_ 848 DateTmYear "DATE";
BA_ "GenSigTimeout_ORC" SG_ 153 ACC_Drive_Cmd 70;
BA_ "GenSigSNA" SG_ 153 ACC_Drive_Cmd "0h";
BA_ "GenSigCycleTime" SG_ 153 ACC_Drive_Cmd 20;
BA_ "FlexKomSigStartValue" SG_ 153 ACC_Drive_Cmd "1FFF0CCB000000FFh";
BA_ "FlexKomSigStartPos" SG_ 153 ACC_Drive_Cmd 7;
BA_ "FlexKomSigName" SG_ 153 ACC_Drive_Cmd "DAS_A3_PKT";
BA_ "FlexKomSigLaenge" SG_ 153 ACC_Drive_Cmd 64;
BA_ "FlexKomSID" SG_ 153 ACC_Drive_Cmd 1043;
BA_ "FlexKomIsMotorola" SG_ 153 ACC_Drive_Cmd 1;
BA_ "FlexKomComment" SG_ 153 ACC_Drive_Cmd "DAS_A3_PKT";
BA_ "GenSigTimeout_ORC" SG_ 153 ACC_Enbl 70;
BA_ "GenSigTimeout_IC" SG_ 153 ACC_Enbl 210;
BA_ "GenSigSNA" SG_ 153 ACC_Enbl "0h";
BA_ "GenSigCycleTime" SG_ 153 ACC_Enbl 20;
BA_ "FlexKomSigStartValue" SG_ 153 ACC_Enbl "1FFF0CCB000000FFh";
BA_ "FlexKomSigStartPos" SG_ 153 ACC_Enbl 7;
BA_ "FlexKomSigName" SG_ 153 ACC_Enbl "DAS_A3_PKT";
BA_ "FlexKomSigLaenge" SG_ 153 ACC_Enbl 64;
BA_ "FlexKomSID" SG_ 153 ACC_Enbl 1043;
BA_ "FlexKomIsMotorola" SG_ 153 ACC_Enbl 1;
BA_ "FlexKomComment" SG_ 153 ACC_Enbl "DAS_A3_PKT";
BA_ "RID" SG_ 153 ACC_Engd "6421";
BA_ "GenSigTimeout_ORC" SG_ 153 ACC_Engd 70;
BA_ "GenSigTimeout_IC" SG_ 153 ACC_Engd 210;
BA_ "GenSigSNA" SG_ 153 ACC_Engd "0h";
BA_ "GenSigCycleTime" SG_ 153 ACC_Engd 20;
BA_ "FlexKomSigStartValue" SG_ 153 ACC_Engd "1FFF0CCB000000FFh";
BA_ "FlexKomSigStartPos" SG_ 153 ACC_Engd 7;
BA_ "FlexKomSigName" SG_ 153 ACC_Engd "DAS_A3_PKT";
BA_ "FlexKomSigLaenge" SG_ 153 ACC_Engd 64;
BA_ "FlexKomSID" SG_ 153 ACC_Engd 1043;
BA_ "FlexKomIsMotorola" SG_ 153 ACC_Engd 1;
BA_ "FlexKomComment" SG_ 153 ACC_Engd "DAS_A3_PKT";
BA_ "GenSigTimeout_ORC" SG_ 153 ACC_Still_Cmd 70;
BA_ "GenSigSNA" SG_ 153 ACC_Still_Cmd "0h";
BA_ "GenSigCycleTime" SG_ 153 ACC_Still_Cmd 20;
BA_ "FlexKomSigStartValue" SG_ 153 ACC_Still_Cmd "1FFF0CCB000000FFh";
BA_ "FlexKomSigStartPos" SG_ 153 ACC_Still_Cmd 7;
BA_ "FlexKomSigName" SG_ 153 ACC_Still_Cmd "DAS_A3_PKT";
BA_ "FlexKomSigLaenge" SG_ 153 ACC_Still_Cmd 64;
BA_ "FlexKomSID" SG_ 153 ACC_Still_Cmd 1043;
BA_ "FlexKomIsMotorola" SG_ 153 ACC_Still_Cmd 1;
BA_ "FlexKomComment" SG_ 153 ACC_Still_Cmd "DAS_A3_PKT";
BA_ "GenSigTimeout_ORC" SG_ 153 As_DispRq 70;
BA_ "GenSigTimeout_IC" SG_ 153 As_DispRq 210;
BA_ "GenSigSNA" SG_ 153 As_DispRq "3h";
BA_ "GenSigCycleTime" SG_ 153 As_DispRq 20;
BA_ "FlexKomSigStartValue" SG_ 153 As_DispRq "1FFF0CCB000000FFh";
BA_ "FlexKomSigStartPos" SG_ 153 As_DispRq 7;
BA_ "FlexKomSigName" SG_ 153 As_DispRq "DAS_A3_PKT";
BA_ "FlexKomSigLaenge" SG_ 153 As_DispRq 64;
BA_ "FlexKomSID" SG_ 153 As_DispRq 1043;
BA_ "FlexKomIsMotorola" SG_ 153 As_DispRq 1;
BA_ "FlexKomComment" SG_ 153 As_DispRq "DAS_A3_PKT";
BA_ "GenSigSNA" SG_ 153 Brk_Jrk_Rq "0h";
BA_ "GenSigCycleTime" SG_ 153 Brk_Jrk_Rq 20;
BA_ "FlexKomSigStartValue" SG_ 153 Brk_Jrk_Rq "1FFF0CCB000000FFh";
BA_ "FlexKomSigStartPos" SG_ 153 Brk_Jrk_Rq 7;
BA_ "FlexKomSigName" SG_ 153 Brk_Jrk_Rq "DAS_A3_PKT";
BA_ "FlexKomSigLaenge" SG_ 153 Brk_Jrk_Rq 64;
BA_ "FlexKomSID" SG_ 153 Brk_Jrk_Rq 1043;
BA_ "FlexKomIsMotorola" SG_ 153 Brk_Jrk_Rq 1;
BA_ "FlexKomComment" SG_ 153 Brk_Jrk_Rq "DAS_A3_PKT";
BA_ "GenSigTimeout_ORC" SG_ 153 Brk_PreFill_Rq 70;
BA_ "GenSigSNA" SG_ 153 Brk_PreFill_Rq "0h";
BA_ "GenSigCycleTime" SG_ 153 Brk_PreFill_Rq 20;
BA_ "FlexKomSigStartValue" SG_ 153 Brk_PreFill_Rq "1FFF0CCB000000FFh";
BA_ "FlexKomSigStartPos" SG_ 153 Brk_PreFill_Rq 7;
BA_ "FlexKomSigName" SG_ 153 Brk_PreFill_Rq "DAS_A3_PKT";
BA_ "FlexKomSigLaenge" SG_ 153 Brk_PreFill_Rq 64;
BA_ "FlexKomSID" SG_ 153 Brk_PreFill_Rq 1043;
BA_ "FlexKomIsMotorola" SG_ 153 Brk_PreFill_Rq 1;
BA_ "FlexKomComment" SG_ 153 Brk_PreFill_Rq "DAS_A3_PKT";
BA_ "GenSigStartValue" SG_ 153 CRC_DAS_A3 255;
BA_ "GenSigSNA" SG_ 153 CRC_DAS_A3 "FFh";
BA_ "GenSigCycleTime" SG_ 153 CRC_DAS_A3 20;
BA_ "FlexKomSigStartValue" SG_ 153 CRC_DAS_A3 "1FFF0CCB000000FFh";
BA_ "FlexKomSigStartPos" SG_ 153 CRC_DAS_A3 7;
BA_ "FlexKomSigName" SG_ 153 CRC_DAS_A3 "DAS_A3_PKT";
BA_ "FlexKomSigLaenge" SG_ 153 CRC_DAS_A3 64;
BA_ "FlexKomSID" SG_ 153 CRC_DAS_A3 1043;
BA_ "FlexKomIsMotorola" SG_ 153 CRC_DAS_A3 1;
BA_ "FlexKomComment" SG_ 153 CRC_DAS_A3 "DAS_A3_PKT";
BA_ "GenSigTimeout_ORC" SG_ 153 DAS_ACCEL_Rq 70;
BA_ "GenSigStartValue" SG_ 153 DAS_ACCEL_Rq 3275;
BA_ "GenSigSNA" SG_ 153 DAS_ACCEL_Rq "FFFh";
BA_ "GenSigCycleTime" SG_ 153 DAS_ACCEL_Rq 20;
BA_ "FlexKomSigStartValue" SG_ 153 DAS_ACCEL_Rq "1FFF0CCB000000FFh";
BA_ "FlexKomSigStartPos" SG_ 153 DAS_ACCEL_Rq 7;
BA_ "FlexKomSigName" SG_ 153 DAS_ACCEL_Rq "DAS_A3_PKT";
BA_ "FlexKomSigLaenge" SG_ 153 DAS_ACCEL_Rq 64;
BA_ "FlexKomSID" SG_ 153 DAS_ACCEL_Rq 1043;
BA_ "FlexKomIsMotorola" SG_ 153 DAS_ACCEL_Rq 1;
BA_ "FlexKomComment" SG_ 153 DAS_ACCEL_Rq "DAS_A3_PKT";
BA_ "GenSigTimeout_ORC" SG_ 153 DAS_Rq_ID 70;
BA_ "GenSigSNA" SG_ 153 DAS_Rq_ID "7h";
BA_ "GenSigCycleTime" SG_ 153 DAS_Rq_ID 20;
BA_ "FlexKomSigStartValue" SG_ 153 DAS_Rq_ID "1FFF0CCB000000FFh";
BA_ "FlexKomSigStartPos" SG_ 153 DAS_Rq_ID 7;
BA_ "FlexKomSigName" SG_ 153 DAS_Rq_ID "DAS_A3_PKT";
BA_ "FlexKomSigLaenge" SG_ 153 DAS_Rq_ID 64;
BA_ "FlexKomSID" SG_ 153 DAS_Rq_ID 1043;
BA_ "FlexKomIsMotorola" SG_ 153 DAS_Rq_ID 1;
BA_ "FlexKomComment" SG_ 153 DAS_Rq_ID "DAS_A3_PKT";
BA_ "GenSigSNA" SG_ 153 DAS_Sts "3h";
BA_ "GenSigCycleTime" SG_ 153 DAS_Sts 20;
BA_ "FlexKomSigStartValue" SG_ 153 DAS_Sts "1FFF0CCB000000FFh";
BA_ "FlexKomSigStartPos" SG_ 153 DAS_Sts 7;
BA_ "FlexKomSigName" SG_ 153 DAS_Sts "DAS_A3_PKT";
BA_ "FlexKomSigLaenge" SG_ 153 DAS_Sts 64;
BA_ "FlexKomSID" SG_ 153 DAS_Sts 1043;
BA_ "FlexKomIsMotorola" SG_ 153 DAS_Sts 1;
BA_ "FlexKomComment" SG_ 153 DAS_Sts "DAS_A3_PKT";
BA_ "GenSigSNA" SG_ 153 DsblFuelShutOff_ACC "0h";
BA_ "GenSigCycleTime" SG_ 153 DsblFuelShutOff_ACC 20;
BA_ "FlexKomSigStartValue" SG_ 153 DsblFuelShutOff_ACC "1FFF0CCB000000FFh";
BA_ "FlexKomSigStartPos" SG_ 153 DsblFuelShutOff_ACC 7;
BA_ "FlexKomSigName" SG_ 153 DsblFuelShutOff_ACC "DAS_A3_PKT";
BA_ "FlexKomSigLaenge" SG_ 153 DsblFuelShutOff_ACC 64;
BA_ "FlexKomSID" SG_ 153 DsblFuelShutOff_ACC 1043;
BA_ "FlexKomIsMotorola" SG_ 153 DsblFuelShutOff_ACC 1;
BA_ "FlexKomComment" SG_ 153 DsblFuelShutOff_ACC "DAS_A3_PKT";
BA_ "GenSigTimeout_ORC" SG_ 153 EngTrqMaxRq_DAS 70;
BA_ "GenSigSNA" SG_ 153 EngTrqMaxRq_DAS "0h";
BA_ "GenSigCycleTime" SG_ 153 EngTrqMaxRq_DAS 20;
BA_ "FlexKomSigStartValue" SG_ 153 EngTrqMaxRq_DAS "1FFF0CCB000000FFh";
BA_ "FlexKomSigStartPos" SG_ 153 EngTrqMaxRq_DAS 7;
BA_ "FlexKomSigName" SG_ 153 EngTrqMaxRq_DAS "DAS_A3_PKT";
BA_ "FlexKomSigLaenge" SG_ 153 EngTrqMaxRq_DAS 64;
BA_ "FlexKomSID" SG_ 153 EngTrqMaxRq_DAS 1043;
BA_ "FlexKomIsMotorola" SG_ 153 EngTrqMaxRq_DAS 1;
BA_ "FlexKomComment" SG_ 153 EngTrqMaxRq_DAS "DAS_A3_PKT";
BA_ "GenSigTimeout_TBM" SG_ 153 EngTrqRq_DAS 210;
BA_ "GenSigStartValue" SG_ 153 EngTrqRq_DAS 8191;
BA_ "GenSigSNA" SG_ 153 EngTrqRq_DAS "1FFFh";
BA_ "GenSigCycleTime" SG_ 153 EngTrqRq_DAS 20;
BA_ "FlexKomSigStartValue" SG_ 153 EngTrqRq_DAS "1FFF0CCB000000FFh";
BA_ "FlexKomSigStartPos" SG_ 153 EngTrqRq_DAS 7;
BA_ "FlexKomSigName" SG_ 153 EngTrqRq_DAS "DAS_A3_PKT";
BA_ "FlexKomSigLaenge" SG_ 153 EngTrqRq_DAS 64;
BA_ "FlexKomSID" SG_ 153 EngTrqRq_DAS 1043;
BA_ "FlexKomIsMotorola" SG_ 153 EngTrqRq_DAS 1;
BA_ "FlexKomComment" SG_ 153 EngTrqRq_DAS "DAS_A3_PKT";
BA_ "GenSigTimeout_ORC" SG_ 153 GrMax_RqDAS 70;
BA_ "GenSigSNA" SG_ 153 GrMax_RqDAS "0h";
BA_ "GenSigCycleTime" SG_ 153 GrMax_RqDAS 20;
BA_ "FlexKomSigStartValue" SG_ 153 GrMax_RqDAS "1FFF0CCB000000FFh";
BA_ "FlexKomSigStartPos" SG_ 153 GrMax_RqDAS 7;
BA_ "FlexKomSigName" SG_ 153 GrMax_RqDAS "DAS_A3_PKT";
BA_ "FlexKomSigLaenge" SG_ 153 GrMax_RqDAS 64;
BA_ "FlexKomSID" SG_ 153 GrMax_RqDAS 1043;
BA_ "FlexKomIsMotorola" SG_ 153 GrMax_RqDAS 1;
BA_ "FlexKomComment" SG_ 153 GrMax_RqDAS "DAS_A3_PKT";
BA_ "GenSigSNA" SG_ 153 MC_DAS_A3 "0h";
BA_ "GenSigCycleTime" SG_ 153 MC_DAS_A3 20;
BA_ "FlexKomSigStartValue" SG_ 153 MC_DAS_A3 "1FFF0CCB000000FFh";
BA_ "FlexKomSigStartPos" SG_ 153 MC_DAS_A3 7;
BA_ "FlexKomSigName" SG_ 153 MC_DAS_A3 "DAS_A3_PKT";
BA_ "FlexKomSigLaenge" SG_ 153 MC_DAS_A3 64;
BA_ "FlexKomSID" SG_ 153 MC_DAS_A3 1043;
BA_ "FlexKomIsMotorola" SG_ 153 MC_DAS_A3 1;
BA_ "FlexKomComment" SG_ 153 MC_DAS_A3 "DAS_A3_PKT";
BA_ "GenSigTimeout_ORC" SG_ 232 ACCFaulted 210;
BA_ "GenSigTimeout_IC" SG_ 232 ACCFaulted 630;
BA_ "GenSigSNA" SG_ 232 ACCFaulted "0h";
BA_ "GenSigCycleTime" SG_ 232 ACCFaulted 60;
BA_ "FlexKomSigStartValue" SG_ 232 ACCFaulted "00FFFF00000000FFh";
BA_ "FlexKomSigStartPos" SG_ 232 ACCFaulted 7;
BA_ "FlexKomSigName" SG_ 232 ACCFaulted "DAS_A4_PKT";
BA_ "FlexKomSigLaenge" SG_ 232 ACCFaulted 64;
BA_ "FlexKomSID" SG_ 232 ACCFaulted 1717;
BA_ "FlexKomIsMotorola" SG_ 232 ACCFaulted 1;
BA_ "FlexKomComment" SG_ 232 ACCFaulted "DAS_A4 Packet";
BA_ "GenSigTimeout_ORC" SG_ 232 ACCNA_DASMSts 210;
BA_ "GenSigTimeout_IC" SG_ 232 ACCNA_DASMSts 630;
BA_ "GenSigSNA" SG_ 232 ACCNA_DASMSts "0h";
BA_ "GenSigCycleTime" SG_ 232 ACCNA_DASMSts 60;
BA_ "FlexKomSigStartValue" SG_ 232 ACCNA_DASMSts "00FFFF00000000FFh";
BA_ "FlexKomSigStartPos" SG_ 232 ACCNA_DASMSts 7;
BA_ "FlexKomSigName" SG_ 232 ACCNA_DASMSts "DAS_A4_PKT";
BA_ "FlexKomSigLaenge" SG_ 232 ACCNA_DASMSts 64;
BA_ "FlexKomSID" SG_ 232 ACCNA_DASMSts 1717;
BA_ "FlexKomIsMotorola" SG_ 232 ACCNA_DASMSts 1;
BA_ "FlexKomComment" SG_ 232 ACCNA_DASMSts "DAS_A4 Packet";
BA_ "GenSigTimeout_ORC" SG_ 232 ACCOnOff 210;
BA_ "GenSigTimeout_IC" SG_ 232 ACCOnOff 630;
BA_ "GenSigSNA" SG_ 232 ACCOnOff "7h";
BA_ "GenSigCycleTime" SG_ 232 ACCOnOff 60;
BA_ "FlexKomSigStartValue" SG_ 232 ACCOnOff "00FFFF00000000FFh";
BA_ "FlexKomSigStartPos" SG_ 232 ACCOnOff 7;
BA_ "FlexKomSigName" SG_ 232 ACCOnOff "DAS_A4_PKT";
BA_ "FlexKomSigLaenge" SG_ 232 ACCOnOff 64;
BA_ "FlexKomSID" SG_ 232 ACCOnOff 1717;
BA_ "FlexKomIsMotorola" SG_ 232 ACCOnOff 1;
BA_ "FlexKomComment" SG_ 232 ACCOnOff "DAS_A4 Packet";
BA_ "GenSigTimeout_IC" SG_ 232 ACConlyNA_DASMSts 630;
BA_ "GenSigSNA" SG_ 232 ACConlyNA_DASMSts "0h";
BA_ "GenSigCycleTime" SG_ 232 ACConlyNA_DASMSts 60;
BA_ "FlexKomSigStartValue" SG_ 232 ACConlyNA_DASMSts "00FFFF00000000FFh";
BA_ "FlexKomSigStartPos" SG_ 232 ACConlyNA_DASMSts 7;
BA_ "FlexKomSigName" SG_ 232 ACConlyNA_DASMSts "DAS_A4_PKT";
BA_ "FlexKomSigLaenge" SG_ 232 ACConlyNA_DASMSts 64;
BA_ "FlexKomSID" SG_ 232 ACConlyNA_DASMSts 1717;
BA_ "FlexKomIsMotorola" SG_ 232 ACConlyNA_DASMSts 1;
BA_ "FlexKomComment" SG_ 232 ACConlyNA_DASMSts "DAS_A4 Packet";
BA_ "GenSigTimeout_ORC" SG_ 232 CIPV_Fused 210;
BA_ "GenSigSNA" SG_ 232 CIPV_Fused "0h";
BA_ "GenSigCycleTime" SG_ 232 CIPV_Fused 60;
BA_ "FlexKomSigStartValue" SG_ 232 CIPV_Fused "00FFFF00000000FFh";
BA_ "FlexKomSigStartPos" SG_ 232 CIPV_Fused 7;
BA_ "FlexKomSigName" SG_ 232 CIPV_Fused "DAS_A4_PKT";
BA_ "FlexKomSigLaenge" SG_ 232 CIPV_Fused 64;
BA_ "FlexKomSID" SG_ 232 CIPV_Fused 1717;
BA_ "FlexKomIsMotorola" SG_ 232 CIPV_Fused 1;
BA_ "FlexKomComment" SG_ 232 CIPV_Fused "DAS_A4 Packet";
BA_ "GenSigTimeout_ORC" SG_ 232 CameraBlocked 210;
BA_ "GenSigTimeout_IC" SG_ 232 CameraBlocked 630;
BA_ "GenSigSNA" SG_ 232 CameraBlocked "0h";
BA_ "GenSigCycleTime" SG_ 232 CameraBlocked 60;
BA_ "FlexKomSigStartValue" SG_ 232 CameraBlocked "00FFFF00000000FFh";
BA_ "FlexKomSigStartPos" SG_ 232 CameraBlocked 7;
BA_ "FlexKomSigName" SG_ 232 CameraBlocked "DAS_A4_PKT";
BA_ "FlexKomSigLaenge" SG_ 232 CameraBlocked 64;
BA_ "FlexKomSID" SG_ 232 CameraBlocked 1717;
BA_ "FlexKomIsMotorola" SG_ 232 CameraBlocked 1;
BA_ "FlexKomComment" SG_ 232 CameraBlocked "DAS_A4 Packet";
BA_ "GenSigTimeout_ORC" SG_ 232 CameraFailure 210;
BA_ "GenSigTimeout_IC" SG_ 232 CameraFailure 630;
BA_ "GenSigSNA" SG_ 232 CameraFailure "0h";
BA_ "GenSigCycleTime" SG_ 232 CameraFailure 60;
BA_ "FlexKomSigStartValue" SG_ 232 CameraFailure "00FFFF00000000FFh";
BA_ "FlexKomSigStartPos" SG_ 232 CameraFailure 7;
BA_ "FlexKomSigName" SG_ 232 CameraFailure "DAS_A4_PKT";
BA_ "FlexKomSigLaenge" SG_ 232 CameraFailure 64;
BA_ "FlexKomSID" SG_ 232 CameraFailure 1717;
BA_ "FlexKomIsMotorola" SG_ 232 CameraFailure 1;
BA_ "FlexKomComment" SG_ 232 CameraFailure "DAS_A4 Packet";
BA_ "GenSigTimeout_ORC" SG_ 232 FCWBrakingOff 210;
BA_ "GenSigTimeout_IC" SG_ 232 FCWBrakingOff 630;
BA_ "GenSigSNA" SG_ 232 FCWBrakingOff "0h";
BA_ "GenSigCycleTime" SG_ 232 FCWBrakingOff 60;
BA_ "FlexKomSigStartValue" SG_ 232 FCWBrakingOff "00FFFF00000000FFh";
BA_ "FlexKomSigStartPos" SG_ 232 FCWBrakingOff 7;
BA_ "FlexKomSigName" SG_ 232 FCWBrakingOff "DAS_A4_PKT";
BA_ "FlexKomSigLaenge" SG_ 232 FCWBrakingOff 64;
BA_ "FlexKomSID" SG_ 232 FCWBrakingOff 1717;
BA_ "FlexKomIsMotorola" SG_ 232 FCWBrakingOff 1;
BA_ "FlexKomComment" SG_ 232 FCWBrakingOff "DAS_A4 Packet";
BA_ "RID" SG_ 232 FCW_BrkOn "1882";
BA_ "GenSigTimeout_ORC" SG_ 232 FCW_BrkOn 210;
BA_ "GenSigTimeout_IC" SG_ 232 FCW_BrkOn 630;
BA_ "GenSigTimeout_CBC" SG_ 232 FCW_BrkOn 630;
BA_ "GenSigSNA" SG_ 232 FCW_BrkOn "0h";
BA_ "GenSigCycleTime" SG_ 232 FCW_BrkOn 60;
BA_ "FlexKomSigStartValue" SG_ 232 FCW_BrkOn "00FFFF00000000FFh";
BA_ "FlexKomSigStartPos" SG_ 232 FCW_BrkOn 7;
BA_ "FlexKomSigName" SG_ 232 FCW_BrkOn "DAS_A4_PKT";
BA_ "FlexKomSigLaenge" SG_ 232 FCW_BrkOn 64;
BA_ "FlexKomSID" SG_ 232 FCW_BrkOn 1717;
BA_ "FlexKomIsMotorola" SG_ 232 FCW_BrkOn 1;
BA_ "FlexKomComment" SG_ 232 FCW_BrkOn "DAS_A4 Packet";
BA_ "GenSigTimeout_ORC" SG_ 232 FCW_Error 210;
BA_ "GenSigTimeout_IC" SG_ 232 FCW_Error 630;
BA_ "GenSigSNA" SG_ 232 FCW_Error "3h";
BA_ "GenSigCycleTime" SG_ 232 FCW_Error 60;
BA_ "FlexKomSigStartValue" SG_ 232 FCW_Error "00FFFF00000000FFh";
BA_ "FlexKomSigStartPos" SG_ 232 FCW_Error 7;
BA_ "FlexKomSigName" SG_ 232 FCW_Error "DAS_A4_PKT";
BA_ "FlexKomSigLaenge" SG_ 232 FCW_Error 64;
BA_ "FlexKomSID" SG_ 232 FCW_Error 1717;
BA_ "FlexKomIsMotorola" SG_ 232 FCW_Error 1;
BA_ "FlexKomComment" SG_ 232 FCW_Error "DAS_A4 Packet";
BA_ "GenSigSNA" SG_ 232 FCWonlyNA_DASMSts "0h";
BA_ "GenSigCycleTime" SG_ 232 FCWonlyNA_DASMSts 60;
BA_ "FlexKomSigStartValue" SG_ 232 FCWonlyNA_DASMSts "00FFFF00000000FFh";
BA_ "FlexKomSigStartPos" SG_ 232 FCWonlyNA_DASMSts 7;
BA_ "FlexKomSigName" SG_ 232 FCWonlyNA_DASMSts "DAS_A4_PKT";
BA_ "FlexKomSigLaenge" SG_ 232 FCWonlyNA_DASMSts 64;
BA_ "FlexKomSID" SG_ 232 FCWonlyNA_DASMSts 1717;
BA_ "FlexKomIsMotorola" SG_ 232 FCWonlyNA_DASMSts 1;
BA_ "FlexKomComment" SG_ 232 FCWonlyNA_DASMSts "DAS_A4 Packet";
BA_ "GenSigTimeout_ORC" SG_ 232 HMI_Screens 210;
BA_ "GenSigTimeout_IC" SG_ 232 HMI_Screens 630;
BA_ "GenSigSNA" SG_ 232 HMI_Screens "FFh";
BA_ "GenSigCycleTime" SG_ 232 HMI_Screens 60;
BA_ "FlexKomSigStartValue" SG_ 232 HMI_Screens "00FFFF00000000FFh";
BA_ "FlexKomSigStartPos" SG_ 232 HMI_Screens 7;
BA_ "FlexKomSigName" SG_ 232 HMI_Screens "DAS_A4_PKT";
BA_ "FlexKomSigLaenge" SG_ 232 HMI_Screens 64;
BA_ "FlexKomSID" SG_ 232 HMI_Screens 1717;
BA_ "FlexKomIsMotorola" SG_ 232 HMI_Screens 1;
BA_ "FlexKomComment" SG_ 232 HMI_Screens "DAS_A4 Packet";
BA_ "GenSigTimeout_ORC" SG_ 232 NCCNA_DASMSts 210;
BA_ "GenSigTimeout_IC" SG_ 232 NCCNA_DASMSts 630;
BA_ "GenSigSNA" SG_ 232 NCCNA_DASMSts "0h";
BA_ "GenSigCycleTime" SG_ 232 NCCNA_DASMSts 60;
BA_ "FlexKomSigStartValue" SG_ 232 NCCNA_DASMSts "00FFFF00000000FFh";
BA_ "FlexKomSigStartPos" SG_ 232 NCCNA_DASMSts 7;
BA_ "FlexKomSigName" SG_ 232 NCCNA_DASMSts "DAS_A4_PKT";
BA_ "FlexKomSigLaenge" SG_ 232 NCCNA_DASMSts 64;
BA_ "FlexKomSID" SG_ 232 NCCNA_DASMSts 1717;
BA_ "FlexKomIsMotorola" SG_ 232 NCCNA_DASMSts 1;
BA_ "FlexKomComment" SG_ 232 NCCNA_DASMSts "DAS_A4 Packet";
BA_ "GenSigTimeout_IC" SG_ 232 NCConlyNA_DASMSts 630;
BA_ "GenSigSNA" SG_ 232 NCConlyNA_DASMSts "0h";
BA_ "GenSigCycleTime" SG_ 232 NCConlyNA_DASMSts 60;
BA_ "FlexKomSigStartValue" SG_ 232 NCConlyNA_DASMSts "00FFFF00000000FFh";
BA_ "FlexKomSigStartPos" SG_ 232 NCConlyNA_DASMSts 7;
BA_ "FlexKomSigName" SG_ 232 NCConlyNA_DASMSts "DAS_A4_PKT";
BA_ "FlexKomSigLaenge" SG_ 232 NCConlyNA_DASMSts 64;
BA_ "FlexKomSID" SG_ 232 NCConlyNA_DASMSts 1717;
BA_ "FlexKomIsMotorola" SG_ 232 NCConlyNA_DASMSts 1;
BA_ "FlexKomComment" SG_ 232 NCConlyNA_DASMSts "DAS_A4 Packet";
BA_ "GenSigTimeout_ORC" SG_ 232 ObjIntrstDist 210;
BA_ "GenSigStartValue" SG_ 232 ObjIntrstDist 255;
BA_ "GenSigSNA" SG_ 232 ObjIntrstDist "FFh";
BA_ "GenSigCycleTime" SG_ 232 ObjIntrstDist 60;
BA_ "FlexKomSigStartValue" SG_ 232 ObjIntrstDist "00FFFF00000000FFh";
BA_ "FlexKomSigStartPos" SG_ 232 ObjIntrstDist 7;
BA_ "FlexKomSigName" SG_ 232 ObjIntrstDist "DAS_A4_PKT";
BA_ "FlexKomSigLaenge" SG_ 232 ObjIntrstDist 64;
BA_ "FlexKomSID" SG_ 232 ObjIntrstDist 1717;
BA_ "FlexKomIsMotorola" SG_ 232 ObjIntrstDist 1;
BA_ "FlexKomComment" SG_ 232 ObjIntrstDist "DAS_A4 Packet";
BA_ "GenSigTimeout_ORC" SG_ 232 RadarBlocked 210;
BA_ "GenSigTimeout_IC" SG_ 232 RadarBlocked 630;
BA_ "GenSigSNA" SG_ 232 RadarBlocked "0h";
BA_ "GenSigCycleTime" SG_ 232 RadarBlocked 60;
BA_ "FlexKomSigStartValue" SG_ 232 RadarBlocked "00FFFF00000000FFh";
BA_ "FlexKomSigStartPos" SG_ 232 RadarBlocked 7;
BA_ "FlexKomSigName" SG_ 232 RadarBlocked "DAS_A4_PKT";
BA_ "FlexKomSigLaenge" SG_ 232 RadarBlocked 64;
BA_ "FlexKomSID" SG_ 232 RadarBlocked 1717;
BA_ "FlexKomIsMotorola" SG_ 232 RadarBlocked 1;
BA_ "FlexKomComment" SG_ 232 RadarBlocked "DAS_A4 Packet";
BA_ "GenSigTimeout_IC" SG_ 232 SetSpeed_KPH 630;
BA_ "GenSigStartValue" SG_ 232 SetSpeed_KPH 255;
BA_ "GenSigSNA" SG_ 232 SetSpeed_KPH "FFh";
BA_ "GenSigCycleTime" SG_ 232 SetSpeed_KPH 60;
BA_ "FlexKomSigStartValue" SG_ 232 SetSpeed_KPH "00FFFF00000000FFh";
BA_ "FlexKomSigStartPos" SG_ 232 SetSpeed_KPH 7;
BA_ "FlexKomSigName" SG_ 232 SetSpeed_KPH "DAS_A4_PKT";
BA_ "FlexKomSigLaenge" SG_ 232 SetSpeed_KPH 64;
BA_ "FlexKomSID" SG_ 232 SetSpeed_KPH 1717;
BA_ "FlexKomIsMotorola" SG_ 232 SetSpeed_KPH 1;
BA_ "FlexKomComment" SG_ 232 SetSpeed_KPH "DAS_A4 Packet";
BA_ "GenSigTimeout_ORC" SG_ 232 SetSpeed_MPH 210;
BA_ "GenSigTimeout_IC" SG_ 232 SetSpeed_MPH 630;
BA_ "GenSigStartValue" SG_ 232 SetSpeed_MPH 255;
BA_ "GenSigSNA" SG_ 232 SetSpeed_MPH "FFh";
BA_ "GenSigCycleTime" SG_ 232 SetSpeed_MPH 60;
BA_ "FlexKomSigStartValue" SG_ 232 SetSpeed_MPH "00FFFF00000000FFh";
BA_ "FlexKomSigStartPos" SG_ 232 SetSpeed_MPH 7;
BA_ "FlexKomSigName" SG_ 232 SetSpeed_MPH "DAS_A4_PKT";
BA_ "FlexKomSigLaenge" SG_ 232 SetSpeed_MPH 64;
BA_ "FlexKomSID" SG_ 232 SetSpeed_MPH 1717;
BA_ "FlexKomIsMotorola" SG_ 232 SetSpeed_MPH 1;
BA_ "FlexKomComment" SG_ 232 SetSpeed_MPH "DAS_A4 Packet";
BA_ "GenSigTimeout_IC" SG_ 232 Sm_ICON_Dspl 630;
BA_ "GenSigSNA" SG_ 232 Sm_ICON_Dspl "3Fh";
BA_ "GenSigCycleTime" SG_ 232 Sm_ICON_Dspl 60;
BA_ "FlexKomSigStartValue" SG_ 232 Sm_ICON_Dspl "00FFFF00000000FFh";
BA_ "FlexKomSigStartPos" SG_ 232 Sm_ICON_Dspl 7;
BA_ "FlexKomSigName" SG_ 232 Sm_ICON_Dspl "DAS_A4_PKT";
BA_ "FlexKomSigLaenge" SG_ 232 Sm_ICON_Dspl 64;
BA_ "FlexKomSID" SG_ 232 Sm_ICON_Dspl 1717;
BA_ "FlexKomIsMotorola" SG_ 232 Sm_ICON_Dspl 1;
BA_ "FlexKomComment" SG_ 232 Sm_ICON_Dspl "DAS_A4 Packet";
BA_ "GenSigTimeout_IC" SG_ 163 DsrSpeed_KPH 210;
BA_ "GenSigStartValue" SG_ 163 DsrSpeed_KPH 255;
BA_ "GenSigSNA" SG_ 163 DsrSpeed_KPH "FFh";
BA_ "GenSigCycleTime" SG_ 163 DsrSpeed_KPH 20;
BA_ "FlexKomSigStartValue" SG_ 163 DsrSpeed_KPH "000000FF000000FFh";
BA_ "FlexKomSigStartPos" SG_ 163 DsrSpeed_KPH 7;
BA_ "FlexKomSigName" SG_ 163 DsrSpeed_KPH "DAS_A5_PKT";
BA_ "FlexKomSigLaenge" SG_ 163 DsrSpeed_KPH 64;
BA_ "FlexKomSID" SG_ 163 DsrSpeed_KPH 2333;
BA_ "FlexKomIsMotorola" SG_ 163 DsrSpeed_KPH 1;
BA_ "FlexKomComment" SG_ 163 DsrSpeed_KPH "DAS_A5 Packet";
BA_ "RID" SG_ 163 FCWSetting "2163";
BA_ "GenSigTimeout_ORC" SG_ 163 FCWSetting 70;
BA_ "GenSigTimeout_IC" SG_ 163 FCWSetting 210;
BA_ "GenSigTimeout_CBC" SG_ 163 FCWSetting 210;
BA_ "GenSigSNA" SG_ 163 FCWSetting "0h";
BA_ "GenSigCycleTime" SG_ 163 FCWSetting 20;
BA_ "FlexKomSigStartValue" SG_ 163 FCWSetting "000000FF000000FFh";
BA_ "FlexKomSigStartPos" SG_ 163 FCWSetting 7;
BA_ "FlexKomSigName" SG_ 163 FCWSetting "DAS_A5_PKT";
BA_ "FlexKomSigLaenge" SG_ 163 FCWSetting 64;
BA_ "FlexKomSID" SG_ 163 FCWSetting 2333;
BA_ "FlexKomIsMotorola" SG_ 163 FCWSetting 1;
BA_ "FlexKomComment" SG_ 163 FCWSetting "DAS_A5 Packet";
BA_ "RID" SG_ 163 FCWState "2171";
BA_ "GenSigTimeout_ORC" SG_ 163 FCWState 70;
BA_ "GenSigTimeout_IC" SG_ 163 FCWState 210;
BA_ "GenSigSNA" SG_ 163 FCWState "0h";
BA_ "GenSigCycleTime" SG_ 163 FCWState 20;
BA_ "FlexKomSigStartValue" SG_ 163 FCWState "000000FF000000FFh";
BA_ "FlexKomSigStartPos" SG_ 163 FCWState 7;
BA_ "FlexKomSigName" SG_ 163 FCWState "DAS_A5_PKT";
BA_ "FlexKomSigLaenge" SG_ 163 FCWState 64;
BA_ "FlexKomSID" SG_ 163 FCWState 2333;
BA_ "FlexKomIsMotorola" SG_ 163 FCWState 1;
BA_ "FlexKomComment" SG_ 163 FCWState "DAS_A5 Packet";
BA_ "GenSigSNA" SG_ 163 WhlTrqActRq_DAS "0h";
BA_ "GenSigCycleTime" SG_ 163 WhlTrqActRq_DAS 20;
BA_ "FlexKomSigStartValue" SG_ 163 WhlTrqActRq_DAS "000000FF000000FFh";
BA_ "FlexKomSigStartPos" SG_ 163 WhlTrqActRq_DAS 7;
BA_ "FlexKomSigName" SG_ 163 WhlTrqActRq_DAS "DAS_A5_PKT";
BA_ "FlexKomSigLaenge" SG_ 163 WhlTrqActRq_DAS 64;
BA_ "FlexKomSID" SG_ 163 WhlTrqActRq_DAS 2333;
BA_ "FlexKomIsMotorola" SG_ 163 WhlTrqActRq_DAS 1;
BA_ "FlexKomComment" SG_ 163 WhlTrqActRq_DAS "DAS_A5 Packet";
BA_ "GenSigSNA" SG_ 163 WhlTrqRq_DAS_2 "FFFFh";
BA_ "GenSigCycleTime" SG_ 163 WhlTrqRq_DAS_2 20;
BA_ "FlexKomSigStartValue" SG_ 163 WhlTrqRq_DAS_2 "000000FF000000FFh";
BA_ "FlexKomSigStartPos" SG_ 163 WhlTrqRq_DAS_2 7;
BA_ "FlexKomSigName" SG_ 163 WhlTrqRq_DAS_2 "DAS_A5_PKT";
BA_ "FlexKomSigLaenge" SG_ 163 WhlTrqRq_DAS_2 64;
BA_ "FlexKomSID" SG_ 163 WhlTrqRq_DAS_2 2333;
BA_ "FlexKomIsMotorola" SG_ 163 WhlTrqRq_DAS_2 1;
BA_ "FlexKomComment" SG_ 163 WhlTrqRq_DAS_2 "DAS_A5 Packet";
BA_ "GenSigSNA" SG_ 250 IRCM_AHB_On "0h";
BA_ "GenSigSendType" SG_ 250 IRCM_AHB_On 4;
BA_ "GenSigCycleTime" SG_ 250 IRCM_AHB_On 60;
BA_ "FlexKomSigStartValue" SG_ 250 IRCM_AHB_On "0000000000000000h";
BA_ "FlexKomSigStartPos" SG_ 250 IRCM_AHB_On 7;
BA_ "FlexKomSigName" SG_ 250 IRCM_AHB_On "DAS_A6_pkt";
BA_ "FlexKomSigLaenge" SG_ 250 IRCM_AHB_On 64;
BA_ "FlexKomSID" SG_ 250 IRCM_AHB_On 2702;
BA_ "FlexKomIsMotorola" SG_ 250 IRCM_AHB_On 1;
BA_ "FlexKomComment" SG_ 250 IRCM_AHB_On "DAS_A6_pkt";
BA_ "GenSigTimeout_IC" SG_ 250 Lane_DispPopupSts 5040;
BA_ "GenSigSNA" SG_ 250 Lane_DispPopupSts "FFh";
BA_ "GenSigSendType" SG_ 250 Lane_DispPopupSts 5;
BA_ "GenSigCycleTime" SG_ 250 Lane_DispPopupSts 60;
BA_ "FlexKomSigStartValue" SG_ 250 Lane_DispPopupSts "0000000000000000h";
BA_ "FlexKomSigStartPos" SG_ 250 Lane_DispPopupSts 7;
BA_ "FlexKomSigName" SG_ 250 Lane_DispPopupSts "DAS_A6_pkt";
BA_ "FlexKomSigLaenge" SG_ 250 Lane_DispPopupSts 64;
BA_ "FlexKomSID" SG_ 250 Lane_DispPopupSts 2702;
BA_ "FlexKomIsMotorola" SG_ 250 Lane_DispPopupSts 1;
BA_ "FlexKomComment" SG_ 250 Lane_DispPopupSts "DAS_A6_pkt";
BA_ "GenSigSNA" SG_ 2015 DG_RQ_GLOBAL "0h";
BA_ "FlexKomSigStartValue" SG_ 2015 DG_RQ_GLOBAL "0000000000000000h";
BA_ "FlexKomSigStartPos" SG_ 2015 DG_RQ_GLOBAL 7;
BA_ "FlexKomSigName" SG_ 2015 DG_RQ_GLOBAL "DG_RQ_GLOBAL";
BA_ "FlexKomSigLaenge" SG_ 2015 DG_RQ_GLOBAL 64;
BA_ "FlexKomSID" SG_ 2015 DG_RQ_GLOBAL 392;
BA_ "FlexKomIsMotorola" SG_ 2015 DG_RQ_GLOBAL 1;
BA_ "FlexKomComment" SG_ 2015 DG_RQ_GLOBAL "Diagnostic-Request";
BA_ "GenSigSNA" SG_ 1089 DG_RQ_GLOBAL_UDS "0h";
BA_ "FlexKomSigStartValue" SG_ 1089 DG_RQ_GLOBAL_UDS "0000000000000000h";
BA_ "FlexKomSigStartPos" SG_ 1089 DG_RQ_GLOBAL_UDS 7;
BA_ "FlexKomSigName" SG_ 1089 DG_RQ_GLOBAL_UDS "DG_RQ_GLOBAL_UDS";
BA_ "FlexKomSigLaenge" SG_ 1089 DG_RQ_GLOBAL_UDS 64;
BA_ "FlexKomSID" SG_ 1089 DG_RQ_GLOBAL_UDS 393;
BA_ "FlexKomIsMotorola" SG_ 1089 DG_RQ_GLOBAL_UDS 1;
BA_ "FlexKomComment" SG_ 1089 DG_RQ_GLOBAL_UDS "Diagnostic-Request";
BA_ "RID" SG_ 860 DIST_TO_TURN "1204";
BA_ "GenSigTimeout_IC" SG_ 860 DIST_TO_TURN 10500;
BA_ "GenSigSNA" SG_ 860 DIST_TO_TURN "FFFFh";
BA_ "GenSigSendType" SG_ 860 DIST_TO_TURN 5;
BA_ "GenSigCycleTime" SG_ 860 DIST_TO_TURN 1000;
BA_ "FlexKomSigStartValue" SG_ 860 DIST_TO_TURN "00000000h";
BA_ "FlexKomSigStartPos" SG_ 860 DIST_TO_TURN 7;
BA_ "FlexKomSigName" SG_ 860 DIST_TO_TURN "TURN_INFO";
BA_ "FlexKomSigLaenge" SG_ 860 DIST_TO_TURN 32;
BA_ "FlexKomSID" SG_ 860 DIST_TO_TURN 986;
BA_ "FlexKomIsMotorola" SG_ 860 DIST_TO_TURN 1;
BA_ "FlexKomComment" SG_ 860 DIST_TO_TURN "Navigation turn information packet";
BA_ "RID" SG_ 860 NAVPrsnt "1198";
BA_ "GenSigSNA" SG_ 860 NAVPrsnt "0h";
BA_ "GenSigSendType" SG_ 860 NAVPrsnt 5;
BA_ "GenSigCycleTime" SG_ 860 NAVPrsnt 1000;
BA_ "FlexKomSigStartValue" SG_ 860 NAVPrsnt "00000000h";
BA_ "FlexKomSigStartPos" SG_ 860 NAVPrsnt 7;
BA_ "FlexKomSigName" SG_ 860 NAVPrsnt "TURN_INFO";
BA_ "FlexKomSigLaenge" SG_ 860 NAVPrsnt 32;
BA_ "FlexKomSID" SG_ 860 NAVPrsnt 986;
BA_ "FlexKomIsMotorola" SG_ 860 NAVPrsnt 1;
BA_ "FlexKomComment" SG_ 860 NAVPrsnt "Navigation turn information packet";
BA_ "RID" SG_ 860 NAV_ARROW "1033";
BA_ "GenSigTimeout_IC" SG_ 860 NAV_ARROW 10500;
BA_ "GenSigSNA" SG_ 860 NAV_ARROW "0h";
BA_ "GenSigSendType" SG_ 860 NAV_ARROW 5;
BA_ "GenSigCycleTime" SG_ 860 NAV_ARROW 1000;
BA_ "FlexKomSigStartValue" SG_ 860 NAV_ARROW "00000000h";
BA_ "FlexKomSigStartPos" SG_ 860 NAV_ARROW 7;
BA_ "FlexKomSigName" SG_ 860 NAV_ARROW "TURN_INFO";
BA_ "FlexKomSigLaenge" SG_ 860 NAV_ARROW 32;
BA_ "FlexKomSID" SG_ 860 NAV_ARROW 986;
BA_ "FlexKomIsMotorola" SG_ 860 NAV_ARROW 1;
BA_ "FlexKomComment" SG_ 860 NAV_ARROW "Navigation turn information packet";
BA_ "RID" SG_ 860 TURN_COMP "1064";
BA_ "GenSigTimeout_IC" SG_ 860 TURN_COMP 10500;
BA_ "GenSigSNA" SG_ 860 TURN_COMP "0h";
BA_ "GenSigSendType" SG_ 860 TURN_COMP 5;
BA_ "GenSigCycleTime" SG_ 860 TURN_COMP 1000;
BA_ "FlexKomSigStartValue" SG_ 860 TURN_COMP "00000000h";
BA_ "FlexKomSigStartPos" SG_ 860 TURN_COMP 7;
BA_ "FlexKomSigName" SG_ 860 TURN_COMP "TURN_INFO";
BA_ "FlexKomSigLaenge" SG_ 860 TURN_COMP 32;
BA_ "FlexKomSID" SG_ 860 TURN_COMP 986;
BA_ "FlexKomIsMotorola" SG_ 860 TURN_COMP 1;
BA_ "FlexKomComment" SG_ 860 TURN_COMP "Navigation turn information packet";
BA_ "RID" SG_ 860 T_BY_T_ON "1194";
BA_ "GenSigTimeout_IC" SG_ 860 T_BY_T_ON 10500;
BA_ "GenSigSNA" SG_ 860 T_BY_T_ON "0h";
BA_ "GenSigSendType" SG_ 860 T_BY_T_ON 5;
BA_ "GenSigCycleTime" SG_ 860 T_BY_T_ON 1000;
BA_ "FlexKomSigStartValue" SG_ 860 T_BY_T_ON "00000000h";
BA_ "FlexKomSigStartPos" SG_ 860 T_BY_T_ON 7;
BA_ "FlexKomSigName" SG_ 860 T_BY_T_ON "TURN_INFO";
BA_ "FlexKomSigLaenge" SG_ 860 T_BY_T_ON 32;
BA_ "FlexKomSID" SG_ 860 T_BY_T_ON 986;
BA_ "FlexKomIsMotorola" SG_ 860 T_BY_T_ON 1;
BA_ "FlexKomComment" SG_ 860 T_BY_T_ON "Navigation turn information packet";
BA_ "RID" SG_ 860 UNITS "1217";
BA_ "GenSigTimeout_IC" SG_ 860 UNITS 10500;
BA_ "GenSigSNA" SG_ 860 UNITS "7h";
BA_ "GenSigSendType" SG_ 860 UNITS 5;
BA_ "GenSigCycleTime" SG_ 860 UNITS 1000;
BA_ "FlexKomSigStartValue" SG_ 860 UNITS "00000000h";
BA_ "FlexKomSigStartPos" SG_ 860 UNITS 7;
BA_ "FlexKomSigName" SG_ 860 UNITS "TURN_INFO";
BA_ "FlexKomSigLaenge" SG_ 860 UNITS 32;
BA_ "FlexKomSID" SG_ 860 UNITS 986;
BA_ "FlexKomIsMotorola" SG_ 860 UNITS 1;
BA_ "FlexKomComment" SG_ 860 UNITS "Navigation turn information packet";
BA_ "GenSigStartValue" SG_ 967 CRC_DPDM_A1 255;
BA_ "GenSigSNA" SG_ 967 CRC_DPDM_A1 "FFh";
BA_ "GenSigSendType" SG_ 967 CRC_DPDM_A1 5;
BA_ "GenSigCycleTime" SG_ 967 CRC_DPDM_A1 200;
BA_ "FlexKomSigStartValue" SG_ 967 CRC_DPDM_A1 "020000FFh";
BA_ "FlexKomSigStartPos" SG_ 967 CRC_DPDM_A1 7;
BA_ "FlexKomSigName" SG_ 967 CRC_DPDM_A1 "DPDM_A1_PKT";
BA_ "FlexKomSigLaenge" SG_ 967 CRC_DPDM_A1 32;
BA_ "FlexKomSID" SG_ 967 CRC_DPDM_A1 2682;
BA_ "FlexKomIsMotorola" SG_ 967 CRC_DPDM_A1 1;
BA_ "FlexKomComment" SG_ 967 CRC_DPDM_A1 "DPDM_A1_PKT";
BA_ "GenSigSNA" SG_ 967 DrvSeatDPFaultSts "0h";
BA_ "GenSigSendType" SG_ 967 DrvSeatDPFaultSts 5;
BA_ "GenSigCycleTime" SG_ 967 DrvSeatDPFaultSts 200;
BA_ "FlexKomSigStartValue" SG_ 967 DrvSeatDPFaultSts "020000FFh";
BA_ "FlexKomSigStartPos" SG_ 967 DrvSeatDPFaultSts 7;
BA_ "FlexKomSigName" SG_ 967 DrvSeatDPFaultSts "DPDM_A1_PKT";
BA_ "FlexKomSigLaenge" SG_ 967 DrvSeatDPFaultSts 32;
BA_ "FlexKomSID" SG_ 967 DrvSeatDPFaultSts 2682;
BA_ "FlexKomIsMotorola" SG_ 967 DrvSeatDPFaultSts 1;
BA_ "FlexKomComment" SG_ 967 DrvSeatDPFaultSts "DPDM_A1_PKT";
BA_ "GenSigStartValue" SG_ 967 DrvSeatDPSts 2;
BA_ "GenSigSNA" SG_ 967 DrvSeatDPSts "3h";
BA_ "GenSigSendType" SG_ 967 DrvSeatDPSts 5;
BA_ "GenSigCycleTime" SG_ 967 DrvSeatDPSts 200;
BA_ "FlexKomSigStartValue" SG_ 967 DrvSeatDPSts "020000FFh";
BA_ "FlexKomSigStartPos" SG_ 967 DrvSeatDPSts 7;
BA_ "FlexKomSigName" SG_ 967 DrvSeatDPSts "DPDM_A1_PKT";
BA_ "FlexKomSigLaenge" SG_ 967 DrvSeatDPSts 32;
BA_ "FlexKomSID" SG_ 967 DrvSeatDPSts 2682;
BA_ "FlexKomIsMotorola" SG_ 967 DrvSeatDPSts 1;
BA_ "FlexKomComment" SG_ 967 DrvSeatDPSts "DPDM_A1_PKT";
BA_ "GenSigSNA" SG_ 967 MC_DPDM_A1 "0h";
BA_ "GenSigSendType" SG_ 967 MC_DPDM_A1 5;
BA_ "GenSigCycleTime" SG_ 967 MC_DPDM_A1 200;
BA_ "FlexKomSigStartValue" SG_ 967 MC_DPDM_A1 "020000FFh";
BA_ "FlexKomSigStartPos" SG_ 967 MC_DPDM_A1 7;
BA_ "FlexKomSigName" SG_ 967 MC_DPDM_A1 "DPDM_A1_PKT";
BA_ "FlexKomSigLaenge" SG_ 967 MC_DPDM_A1 32;
BA_ "FlexKomSID" SG_ 967 MC_DPDM_A1 2682;
BA_ "FlexKomIsMotorola" SG_ 967 MC_DPDM_A1 1;
BA_ "FlexKomComment" SG_ 967 MC_DPDM_A1 "DPDM_A1_PKT";
BA_ "GenSigStartValue" SG_ 462 CRC_DPDM_A2 255;
BA_ "GenSigSNA" SG_ 462 CRC_DPDM_A2 "FFh";
BA_ "GenSigCycleTime" SG_ 462 CRC_DPDM_A2 50;
BA_ "FlexKomSigStartValue" SG_ 462 CRC_DPDM_A2 "000000FFh";
BA_ "FlexKomSigStartPos" SG_ 462 CRC_DPDM_A2 7;
BA_ "FlexKomSigName" SG_ 462 CRC_DPDM_A2 "DPDM_A2_PKT";
BA_ "FlexKomSigLaenge" SG_ 462 CRC_DPDM_A2 32;
BA_ "FlexKomSID" SG_ 462 CRC_DPDM_A2 2683;
BA_ "FlexKomIsMotorola" SG_ 462 CRC_DPDM_A2 1;
BA_ "FlexKomComment" SG_ 462 CRC_DPDM_A2 "DPDM_A2_PKT";
BA_ "GenSigSNA" SG_ 462 DrvPrsnSensorRawValSts "0h";
BA_ "GenSigCycleTime" SG_ 462 DrvPrsnSensorRawValSts 50;
BA_ "FlexKomSigStartValue" SG_ 462 DrvPrsnSensorRawValSts "000000FFh";
BA_ "FlexKomSigStartPos" SG_ 462 DrvPrsnSensorRawValSts 7;
BA_ "FlexKomSigName" SG_ 462 DrvPrsnSensorRawValSts "DPDM_A2_PKT";
BA_ "FlexKomSigLaenge" SG_ 462 DrvPrsnSensorRawValSts 32;
BA_ "FlexKomSID" SG_ 462 DrvPrsnSensorRawValSts 2683;
BA_ "FlexKomIsMotorola" SG_ 462 DrvPrsnSensorRawValSts 1;
BA_ "FlexKomComment" SG_ 462 DrvPrsnSensorRawValSts "DPDM_A2_PKT";
BA_ "GenSigSNA" SG_ 462 MC_DPDM_A2 "0h";
BA_ "GenSigCycleTime" SG_ 462 MC_DPDM_A2 50;
BA_ "FlexKomSigStartValue" SG_ 462 MC_DPDM_A2 "000000FFh";
BA_ "FlexKomSigStartPos" SG_ 462 MC_DPDM_A2 7;
BA_ "FlexKomSigName" SG_ 462 MC_DPDM_A2 "DPDM_A2_PKT";
BA_ "FlexKomSigLaenge" SG_ 462 MC_DPDM_A2 32;
BA_ "FlexKomSID" SG_ 462 MC_DPDM_A2 2683;
BA_ "FlexKomIsMotorola" SG_ 462 MC_DPDM_A2 1;
BA_ "FlexKomComment" SG_ 462 MC_DPDM_A2 "DPDM_A2_PKT";
BA_ "GenSigSNA" SG_ 167 BrkPrss_One "0h";
BA_ "GenSigCycleTime" SG_ 167 BrkPrss_One 20;
BA_ "FlexKomSigStartValue" SG_ 167 BrkPrss_One "04000000C00000FFh";
BA_ "FlexKomSigStartPos" SG_ 167 BrkPrss_One 7;
BA_ "FlexKomSigName" SG_ 167 BrkPrss_One "DST_TOC";
BA_ "FlexKomSigLaenge" SG_ 167 BrkPrss_One 64;
BA_ "FlexKomSID" SG_ 167 BrkPrss_One 1909;
BA_ "FlexKomIsMotorola" SG_ 167 BrkPrss_One 1;
BA_ "FlexKomComment" SG_ 167 BrkPrss_One "DST_TOC";
BA_ "GenSigSNA" SG_ 167 BrkPrss_Two "0h";
BA_ "GenSigCycleTime" SG_ 167 BrkPrss_Two 20;
BA_ "FlexKomSigStartValue" SG_ 167 BrkPrss_Two "04000000C00000FFh";
BA_ "FlexKomSigStartPos" SG_ 167 BrkPrss_Two 7;
BA_ "FlexKomSigName" SG_ 167 BrkPrss_Two "DST_TOC";
BA_ "FlexKomSigLaenge" SG_ 167 BrkPrss_Two 64;
BA_ "FlexKomSID" SG_ 167 BrkPrss_Two 1909;
BA_ "FlexKomIsMotorola" SG_ 167 BrkPrss_Two 1;
BA_ "FlexKomComment" SG_ 167 BrkPrss_Two "DST_TOC";
BA_ "GenSigStartValue" SG_ 167 CRC_294h 255;
BA_ "GenSigSNA" SG_ 167 CRC_294h "FFh";
BA_ "GenSigCycleTime" SG_ 167 CRC_294h 20;
BA_ "FlexKomSigStartValue" SG_ 167 CRC_294h "04000000C00000FFh";
BA_ "FlexKomSigStartPos" SG_ 167 CRC_294h 7;
BA_ "FlexKomSigName" SG_ 167 CRC_294h "DST_TOC";
BA_ "FlexKomSigLaenge" SG_ 167 CRC_294h 64;
BA_ "FlexKomSID" SG_ 167 CRC_294h 1909;
BA_ "FlexKomIsMotorola" SG_ 167 CRC_294h 1;
BA_ "FlexKomComment" SG_ 167 CRC_294h "DST_TOC";
BA_ "GenSigSNA" SG_ 167 MC_294h "0h";
BA_ "GenSigCycleTime" SG_ 167 MC_294h 20;
BA_ "FlexKomSigStartValue" SG_ 167 MC_294h "04000000C00000FFh";
BA_ "FlexKomSigStartPos" SG_ 167 MC_294h 7;
BA_ "FlexKomSigName" SG_ 167 MC_294h "DST_TOC";
BA_ "FlexKomSigLaenge" SG_ 167 MC_294h 64;
BA_ "FlexKomSID" SG_ 167 MC_294h 1909;
BA_ "FlexKomIsMotorola" SG_ 167 MC_294h 1;
BA_ "FlexKomComment" SG_ 167 MC_294h "DST_TOC";
BA_ "GenSigStartValue" SG_ 167 SyncPos 6;
BA_ "GenSigSNA" SG_ 167 SyncPos "7h";
BA_ "GenSigCycleTime" SG_ 167 SyncPos 20;
BA_ "FlexKomSigStartValue" SG_ 167 SyncPos "04000000C00000FFh";
BA_ "FlexKomSigStartPos" SG_ 167 SyncPos 7;
BA_ "FlexKomSigName" SG_ 167 SyncPos "DST_TOC";
BA_ "FlexKomSigLaenge" SG_ 167 SyncPos 64;
BA_ "FlexKomSID" SG_ 167 SyncPos 1909;
BA_ "FlexKomIsMotorola" SG_ 167 SyncPos 1;
BA_ "FlexKomComment" SG_ 167 SyncPos "DST_TOC";
BA_ "RID" SG_ 141 ACT_CNT_DIF_TRQ "1268";
BA_ "GenSigTimeout_ETM" SG_ 141 ACT_CNT_DIF_TRQ 210;
BA_ "GenSigTimeout_CBC" SG_ 141 ACT_CNT_DIF_TRQ 210;
BA_ "GenSigStartValue" SG_ 141 ACT_CNT_DIF_TRQ 255;
BA_ "GenSigSNA" SG_ 141 ACT_CNT_DIF_TRQ "FFh";
BA_ "GenSigCycleTime" SG_ 141 ACT_CNT_DIF_TRQ 20;
BA_ "FlexKomSigStartValue" SG_ 141 ACT_CNT_DIF_TRQ "CEC0FFFFFFFFFFFFh";
BA_ "FlexKomSigStartPos" SG_ 141 ACT_CNT_DIF_TRQ 7;
BA_ "FlexKomSigName" SG_ 141 ACT_CNT_DIF_TRQ "DTCM_A1_PKT";
BA_ "FlexKomSigLaenge" SG_ 141 ACT_CNT_DIF_TRQ 64;
BA_ "FlexKomSID" SG_ 141 ACT_CNT_DIF_TRQ 807;
BA_ "FlexKomIsMotorola" SG_ 141 ACT_CNT_DIF_TRQ 1;
BA_ "FlexKomComment" SG_ 141 ACT_CNT_DIF_TRQ "DTCM_A1_PKT";
BA_ "GenSigStartValue" SG_ 141 DES_CNT_DIF_TRQ 255;
BA_ "GenSigSNA" SG_ 141 DES_CNT_DIF_TRQ "FFh";
BA_ "GenSigCycleTime" SG_ 141 DES_CNT_DIF_TRQ 20;
BA_ "FlexKomSigStartValue" SG_ 141 DES_CNT_DIF_TRQ "CEC0FFFFFFFFFFFFh";
BA_ "FlexKomSigStartPos" SG_ 141 DES_CNT_DIF_TRQ 7;
BA_ "FlexKomSigName" SG_ 141 DES_CNT_DIF_TRQ "DTCM_A1_PKT";
BA_ "FlexKomSigLaenge" SG_ 141 DES_CNT_DIF_TRQ 64;
BA_ "FlexKomSID" SG_ 141 DES_CNT_DIF_TRQ 807;
BA_ "FlexKomIsMotorola" SG_ 141 DES_CNT_DIF_TRQ 1;
BA_ "FlexKomComment" SG_ 141 DES_CNT_DIF_TRQ "DTCM_A1_PKT";
BA_ "GenSigSNA" SG_ 141 SHFT_ABRT "1h";
BA_ "GenSigCycleTime" SG_ 141 SHFT_ABRT 20;
BA_ "FlexKomSigStartValue" SG_ 141 SHFT_ABRT "CEC0FFFFFFFFFFFFh";
BA_ "FlexKomSigStartPos" SG_ 141 SHFT_ABRT 7;
BA_ "FlexKomSigName" SG_ 141 SHFT_ABRT "DTCM_A1_PKT";
BA_ "FlexKomSigLaenge" SG_ 141 SHFT_ABRT 64;
BA_ "FlexKomSID" SG_ 141 SHFT_ABRT 807;
BA_ "FlexKomIsMotorola" SG_ 141 SHFT_ABRT 1;
BA_ "FlexKomComment" SG_ 141 SHFT_ABRT "DTCM_A1_PKT";
BA_ "GenSigSNA" SG_ 141 TCASERANGESTATUS "3h";
BA_ "GenSigCycleTime" SG_ 141 TCASERANGESTATUS 20;
BA_ "FlexKomSigStartValue" SG_ 141 TCASERANGESTATUS "CEC0FFFFFFFFFFFFh";
BA_ "FlexKomSigStartPos" SG_ 141 TCASERANGESTATUS 7;
BA_ "FlexKomSigName" SG_ 141 TCASERANGESTATUS "DTCM_A1_PKT";
BA_ "FlexKomSigLaenge" SG_ 141 TCASERANGESTATUS 64;
BA_ "FlexKomSID" SG_ 141 TCASERANGESTATUS 807;
BA_ "FlexKomIsMotorola" SG_ 141 TCASERANGESTATUS 1;
BA_ "FlexKomComment" SG_ 141 TCASERANGESTATUS "DTCM_A1_PKT";
BA_ "RID" SG_ 141 TCASE_STAT "1238";
BA_ "GenSigTimeout_TCM" SG_ 141 TCASE_STAT 210;
BA_ "GenSigTimeout_RF_HUB" SG_ 141 TCASE_STAT 210;
BA_ "GenSigTimeout_PTS" SG_ 141 TCASE_STAT 210;
BA_ "GenSigTimeout_ORC" SG_ 141 TCASE_STAT 70;
BA_ "GenSigTimeout_IC" SG_ 141 TCASE_STAT 210;
BA_ "GenSigTimeout_ETM" SG_ 141 TCASE_STAT 210;
BA_ "GenSigTimeout_CBC" SG_ 141 TCASE_STAT 210;
BA_ "GenSigStartValue" SG_ 141 TCASE_STAT 7;
BA_ "GenSigSNA" SG_ 141 TCASE_STAT "7h";
BA_ "GenSigCycleTime" SG_ 141 TCASE_STAT 20;
BA_ "FlexKomSigStartValue" SG_ 141 TCASE_STAT "CEC0FFFFFFFFFFFFh";
BA_ "FlexKomSigStartPos" SG_ 141 TCASE_STAT 7;
BA_ "FlexKomSigName" SG_ 141 TCASE_STAT "DTCM_A1_PKT";
BA_ "FlexKomSigLaenge" SG_ 141 TCASE_STAT 64;
BA_ "FlexKomSID" SG_ 141 TCASE_STAT 807;
BA_ "FlexKomIsMotorola" SG_ 141 TCASE_STAT 1;
BA_ "FlexKomComment" SG_ 141 TCASE_STAT "DTCM_A1_PKT";
BA_ "GenSigStartValue" SG_ 145 CRC_DTCM_A2 255;
BA_ "GenSigSNA" SG_ 145 CRC_DTCM_A2 "FFh";
BA_ "GenSigCycleTime" SG_ 145 CRC_DTCM_A2 20;
BA_ "FlexKomSigStartValue" SG_ 145 CRC_DTCM_A2 "01FF7F00000000FFh";
BA_ "FlexKomSigStartPos" SG_ 145 CRC_DTCM_A2 7;
BA_ "FlexKomSigName" SG_ 145 CRC_DTCM_A2 "DTCM_A2_PKT";
BA_ "FlexKomSigLaenge" SG_ 145 CRC_DTCM_A2 64;
BA_ "FlexKomSID" SG_ 145 CRC_DTCM_A2 1520;
BA_ "FlexKomIsMotorola" SG_ 145 CRC_DTCM_A2 1;
BA_ "FlexKomComment" SG_ 145 CRC_DTCM_A2 "DTCM_A2_PKT";
BA_ "GenSigSNA" SG_ 145 DrvLnMinTrqMd "0h";
BA_ "GenSigCycleTime" SG_ 145 DrvLnMinTrqMd 20;
BA_ "FlexKomSigStartValue" SG_ 145 DrvLnMinTrqMd "01FF7F00000000FFh";
BA_ "FlexKomSigStartPos" SG_ 145 DrvLnMinTrqMd 7;
BA_ "FlexKomSigName" SG_ 145 DrvLnMinTrqMd "DTCM_A2_PKT";
BA_ "FlexKomSigLaenge" SG_ 145 DrvLnMinTrqMd 64;
BA_ "FlexKomSID" SG_ 145 DrvLnMinTrqMd 1520;
BA_ "FlexKomIsMotorola" SG_ 145 DrvLnMinTrqMd 1;
BA_ "FlexKomComment" SG_ 145 DrvLnMinTrqMd "DTCM_A2_PKT";
BA_ "GenSigStartValue" SG_ 145 DrvLnTrqRq 511;
BA_ "GenSigSNA" SG_ 145 DrvLnTrqRq "1FFh";
BA_ "GenSigCycleTime" SG_ 145 DrvLnTrqRq 20;
BA_ "FlexKomSigStartValue" SG_ 145 DrvLnTrqRq "01FF7F00000000FFh";
BA_ "FlexKomSigStartPos" SG_ 145 DrvLnTrqRq 7;
BA_ "FlexKomSigName" SG_ 145 DrvLnTrqRq "DTCM_A2_PKT";
BA_ "FlexKomSigLaenge" SG_ 145 DrvLnTrqRq 64;
BA_ "FlexKomSID" SG_ 145 DrvLnTrqRq 1520;
BA_ "FlexKomIsMotorola" SG_ 145 DrvLnTrqRq 1;
BA_ "FlexKomComment" SG_ 145 DrvLnTrqRq "DTCM_A2_PKT";
BA_ "GenSigSNA" SG_ 145 MC_DTCM_A2 "0h";
BA_ "GenSigCycleTime" SG_ 145 MC_DTCM_A2 20;
BA_ "FlexKomSigStartValue" SG_ 145 MC_DTCM_A2 "01FF7F00000000FFh";
BA_ "FlexKomSigStartPos" SG_ 145 MC_DTCM_A2 7;
BA_ "FlexKomSigName" SG_ 145 MC_DTCM_A2 "DTCM_A2_PKT";
BA_ "FlexKomSigLaenge" SG_ 145 MC_DTCM_A2 64;
BA_ "FlexKomSID" SG_ 145 MC_DTCM_A2 1520;
BA_ "FlexKomIsMotorola" SG_ 145 MC_DTCM_A2 1;
BA_ "FlexKomComment" SG_ 145 MC_DTCM_A2 "DTCM_A2_PKT";
BA_ "GenSigTimeout_IC" SG_ 631 AXLELCKR_SRV_RQ 10500;
BA_ "GenSigTimeout_ETM" SG_ 631 AXLELCKR_SRV_RQ 10500;
BA_ "GenSigSNA" SG_ 631 AXLELCKR_SRV_RQ "3h";
BA_ "GenSigSendType" SG_ 631 AXLELCKR_SRV_RQ 5;
BA_ "GenSigCycleTime" SG_ 631 AXLELCKR_SRV_RQ 1000;
BA_ "FlexKomSigStartValue" SG_ 631 AXLELCKR_SRV_RQ "0000000000000000h";
BA_ "FlexKomSigStartPos" SG_ 631 AXLELCKR_SRV_RQ 7;
BA_ "FlexKomSigName" SG_ 631 AXLELCKR_SRV_RQ "DTCM_B1_PKT";
BA_ "FlexKomSigLaenge" SG_ 631 AXLELCKR_SRV_RQ 64;
BA_ "FlexKomSID" SG_ 631 AXLELCKR_SRV_RQ 808;
BA_ "FlexKomIsMotorola" SG_ 631 AXLELCKR_SRV_RQ 1;
BA_ "FlexKomComment" SG_ 631 AXLELCKR_SRV_RQ "DTCM_B1_PKT";
BA_ "GenSigTimeout_IC" SG_ 631 AxleLckrEVICDisplay 10500;
BA_ "GenSigSNA" SG_ 631 AxleLckrEVICDisplay "Fh";
BA_ "GenSigSendType" SG_ 631 AxleLckrEVICDisplay 5;
BA_ "GenSigCycleTime" SG_ 631 AxleLckrEVICDisplay 1000;
BA_ "FlexKomSigStartValue" SG_ 631 AxleLckrEVICDisplay "0000000000000000h";
BA_ "FlexKomSigStartPos" SG_ 631 AxleLckrEVICDisplay 7;
BA_ "FlexKomSigName" SG_ 631 AxleLckrEVICDisplay "DTCM_B1_PKT";
BA_ "FlexKomSigLaenge" SG_ 631 AxleLckrEVICDisplay 64;
BA_ "FlexKomSID" SG_ 631 AxleLckrEVICDisplay 808;
BA_ "FlexKomIsMotorola" SG_ 631 AxleLckrEVICDisplay 1;
BA_ "FlexKomComment" SG_ 631 AxleLckrEVICDisplay "DTCM_B1_PKT";
BA_ "GenSigTimeout_IC" SG_ 631 AxleLckrSts 10500;
BA_ "GenSigSNA" SG_ 631 AxleLckrSts "3h";
BA_ "GenSigSendType" SG_ 631 AxleLckrSts 5;
BA_ "GenSigCycleTime" SG_ 631 AxleLckrSts 1000;
BA_ "FlexKomSigStartValue" SG_ 631 AxleLckrSts "0000000000000000h";
BA_ "FlexKomSigStartPos" SG_ 631 AxleLckrSts 7;
BA_ "FlexKomSigName" SG_ 631 AxleLckrSts "DTCM_B1_PKT";
BA_ "FlexKomSigLaenge" SG_ 631 AxleLckrSts 64;
BA_ "FlexKomSID" SG_ 631 AxleLckrSts 808;
BA_ "FlexKomIsMotorola" SG_ 631 AxleLckrSts 1;
BA_ "FlexKomComment" SG_ 631 AxleLckrSts "DTCM_B1_PKT";
BA_ "GenSigTimeout_IC" SG_ 631 CNT_DIFF_MOD 10500;
BA_ "GenSigSNA" SG_ 631 CNT_DIFF_MOD "3h";
BA_ "GenSigSendType" SG_ 631 CNT_DIFF_MOD 5;
BA_ "GenSigCycleTime" SG_ 631 CNT_DIFF_MOD 1000;
BA_ "FlexKomSigStartValue" SG_ 631 CNT_DIFF_MOD "0000000000000000h";
BA_ "FlexKomSigStartPos" SG_ 631 CNT_DIFF_MOD 7;
BA_ "FlexKomSigName" SG_ 631 CNT_DIFF_MOD "DTCM_B1_PKT";
BA_ "FlexKomSigLaenge" SG_ 631 CNT_DIFF_MOD 64;
BA_ "FlexKomSID" SG_ 631 CNT_DIFF_MOD 808;
BA_ "FlexKomIsMotorola" SG_ 631 CNT_DIFF_MOD 1;
BA_ "FlexKomComment" SG_ 631 CNT_DIFF_MOD "DTCM_B1_PKT";
BA_ "GenSigTimeout_IC" SG_ 631 DTCM_HMI_Rq 10500;
BA_ "GenSigSNA" SG_ 631 DTCM_HMI_Rq "1Fh";
BA_ "GenSigSendType" SG_ 631 DTCM_HMI_Rq 5;
BA_ "GenSigCycleTime" SG_ 631 DTCM_HMI_Rq 1000;
BA_ "FlexKomSigStartValue" SG_ 631 DTCM_HMI_Rq "0000000000000000h";
BA_ "FlexKomSigStartPos" SG_ 631 DTCM_HMI_Rq 7;
BA_ "FlexKomSigName" SG_ 631 DTCM_HMI_Rq "DTCM_B1_PKT";
BA_ "FlexKomSigLaenge" SG_ 631 DTCM_HMI_Rq 64;
BA_ "FlexKomSID" SG_ 631 DTCM_HMI_Rq 808;
BA_ "FlexKomIsMotorola" SG_ 631 DTCM_HMI_Rq 1;
BA_ "FlexKomComment" SG_ 631 DTCM_HMI_Rq "DTCM_B1_PKT";
BA_ "RID" SG_ 631 Ft_RrAxleLkIndRq "5154";
BA_ "GenSigTimeout_IC" SG_ 631 Ft_RrAxleLkIndRq 10500;
BA_ "GenSigTimeout_CBC" SG_ 631 Ft_RrAxleLkIndRq 10500;
BA_ "GenSigSNA" SG_ 631 Ft_RrAxleLkIndRq "3h";
BA_ "GenSigSendType" SG_ 631 Ft_RrAxleLkIndRq 5;
BA_ "GenSigCycleTime" SG_ 631 Ft_RrAxleLkIndRq 1000;
BA_ "FlexKomSigStartValue" SG_ 631 Ft_RrAxleLkIndRq "0000000000000000h";
BA_ "FlexKomSigStartPos" SG_ 631 Ft_RrAxleLkIndRq 7;
BA_ "FlexKomSigName" SG_ 631 Ft_RrAxleLkIndRq "DTCM_B1_PKT";
BA_ "FlexKomSigLaenge" SG_ 631 Ft_RrAxleLkIndRq 64;
BA_ "FlexKomSID" SG_ 631 Ft_RrAxleLkIndRq 808;
BA_ "FlexKomIsMotorola" SG_ 631 Ft_RrAxleLkIndRq 1;
BA_ "FlexKomComment" SG_ 631 Ft_RrAxleLkIndRq "DTCM_B1_PKT";
BA_ "RID" SG_ 631 RrAxleLkIndRq "2884 3589 5126";
BA_ "GenSigTimeout_IC" SG_ 631 RrAxleLkIndRq 10500;
BA_ "GenSigSNA" SG_ 631 RrAxleLkIndRq "3h";
BA_ "GenSigSendType" SG_ 631 RrAxleLkIndRq 5;
BA_ "GenSigCycleTime" SG_ 631 RrAxleLkIndRq 1000;
BA_ "FlexKomSigStartValue" SG_ 631 RrAxleLkIndRq "0000000000000000h";
BA_ "FlexKomSigStartPos" SG_ 631 RrAxleLkIndRq 7;
BA_ "FlexKomSigName" SG_ 631 RrAxleLkIndRq "DTCM_B1_PKT";
BA_ "FlexKomSigLaenge" SG_ 631 RrAxleLkIndRq 64;
BA_ "FlexKomSID" SG_ 631 RrAxleLkIndRq 808;
BA_ "FlexKomIsMotorola" SG_ 631 RrAxleLkIndRq 1;
BA_ "FlexKomComment" SG_ 631 RrAxleLkIndRq "DTCM_B1_PKT";
BA_ "GenSigTimeout_IC" SG_ 631 TCASE_FAIL 10500;
BA_ "GenSigTimeout_ETM" SG_ 631 TCASE_FAIL 10500;
BA_ "GenSigSNA" SG_ 631 TCASE_FAIL "0h";
BA_ "GenSigSendType" SG_ 631 TCASE_FAIL 5;
BA_ "GenSigCycleTime" SG_ 631 TCASE_FAIL 1000;
BA_ "FlexKomSigStartValue" SG_ 631 TCASE_FAIL "0000000000000000h";
BA_ "FlexKomSigStartPos" SG_ 631 TCASE_FAIL 7;
BA_ "FlexKomSigName" SG_ 631 TCASE_FAIL "DTCM_B1_PKT";
BA_ "FlexKomSigLaenge" SG_ 631 TCASE_FAIL 64;
BA_ "FlexKomSID" SG_ 631 TCASE_FAIL 808;
BA_ "FlexKomIsMotorola" SG_ 631 TCASE_FAIL 1;
BA_ "FlexKomComment" SG_ 631 TCASE_FAIL "DTCM_B1_PKT";
BA_ "GenSigTimeout_IC" SG_ 631 TCASE_INHBT 10500;
BA_ "GenSigTimeout_ETM" SG_ 631 TCASE_INHBT 10500;
BA_ "GenSigSNA" SG_ 631 TCASE_INHBT "0h";
BA_ "GenSigSendType" SG_ 631 TCASE_INHBT 5;
BA_ "GenSigCycleTime" SG_ 631 TCASE_INHBT 1000;
BA_ "FlexKomSigStartValue" SG_ 631 TCASE_INHBT "0000000000000000h";
BA_ "FlexKomSigStartPos" SG_ 631 TCASE_INHBT 7;
BA_ "FlexKomSigName" SG_ 631 TCASE_INHBT "DTCM_B1_PKT";
BA_ "FlexKomSigLaenge" SG_ 631 TCASE_INHBT 64;
BA_ "FlexKomSID" SG_ 631 TCASE_INHBT 808;
BA_ "FlexKomIsMotorola" SG_ 631 TCASE_INHBT 1;
BA_ "FlexKomComment" SG_ 631 TCASE_INHBT "DTCM_B1_PKT";
BA_ "GenSigTimeout_IC" SG_ 631 TCASE_SRV_RQ 10500;
BA_ "GenSigTimeout_ETM" SG_ 631 TCASE_SRV_RQ 10500;
BA_ "GenSigSNA" SG_ 631 TCASE_SRV_RQ "3h";
BA_ "GenSigSendType" SG_ 631 TCASE_SRV_RQ 5;
BA_ "GenSigCycleTime" SG_ 631 TCASE_SRV_RQ 1000;
BA_ "FlexKomSigStartValue" SG_ 631 TCASE_SRV_RQ "0000000000000000h";
BA_ "FlexKomSigStartPos" SG_ 631 TCASE_SRV_RQ 7;
BA_ "FlexKomSigName" SG_ 631 TCASE_SRV_RQ "DTCM_B1_PKT";
BA_ "FlexKomSigLaenge" SG_ 631 TCASE_SRV_RQ 64;
BA_ "FlexKomSID" SG_ 631 TCASE_SRV_RQ 808;
BA_ "FlexKomIsMotorola" SG_ 631 TCASE_SRV_RQ 1;
BA_ "FlexKomComment" SG_ 631 TCASE_SRV_RQ "DTCM_B1_PKT";
BA_ "RID" SG_ 631 Tcase2WD_Stat "1641 5141";
BA_ "GenSigTimeout_IC" SG_ 631 Tcase2WD_Stat 10500;
BA_ "GenSigTimeout_CBC" SG_ 631 Tcase2WD_Stat 10500;
BA_ "GenSigSNA" SG_ 631 Tcase2WD_Stat "3h";
BA_ "GenSigSendType" SG_ 631 Tcase2WD_Stat 5;
BA_ "GenSigCycleTime" SG_ 631 Tcase2WD_Stat 1000;
BA_ "FlexKomSigStartValue" SG_ 631 Tcase2WD_Stat "0000000000000000h";
BA_ "FlexKomSigStartPos" SG_ 631 Tcase2WD_Stat 7;
BA_ "FlexKomSigName" SG_ 631 Tcase2WD_Stat "DTCM_B1_PKT";
BA_ "FlexKomSigLaenge" SG_ 631 Tcase2WD_Stat 64;
BA_ "FlexKomSID" SG_ 631 Tcase2WD_Stat 808;
BA_ "FlexKomIsMotorola" SG_ 631 Tcase2WD_Stat 1;
BA_ "FlexKomComment" SG_ 631 Tcase2WD_Stat "DTCM_B1_PKT";
BA_ "RID" SG_ 631 Tcase4Lock "6524";
BA_ "GenSigTimeout_IC" SG_ 631 Tcase4Lock 10500;
BA_ "GenSigTimeout_ETM" SG_ 631 Tcase4Lock 10500;
BA_ "GenSigTimeout_CBC" SG_ 631 Tcase4Lock 10500;
BA_ "GenSigSNA" SG_ 631 Tcase4Lock "3h";
BA_ "GenSigSendType" SG_ 631 Tcase4Lock 5;
BA_ "GenSigCycleTime" SG_ 631 Tcase4Lock 1000;
BA_ "FlexKomSigStartValue" SG_ 631 Tcase4Lock "0000000000000000h";
BA_ "FlexKomSigStartPos" SG_ 631 Tcase4Lock 7;
BA_ "FlexKomSigName" SG_ 631 Tcase4Lock "DTCM_B1_PKT";
BA_ "FlexKomSigLaenge" SG_ 631 Tcase4Lock 64;
BA_ "FlexKomSID" SG_ 631 Tcase4Lock 808;
BA_ "FlexKomIsMotorola" SG_ 631 Tcase4Lock 1;
BA_ "FlexKomComment" SG_ 631 Tcase4Lock "DTCM_B1_PKT";
BA_ "RID" SG_ 631 Tcase4Low "1640 1747";
BA_ "GenSigTimeout_IC" SG_ 631 Tcase4Low 10500;
BA_ "GenSigTimeout_ETM" SG_ 631 Tcase4Low 10500;
BA_ "GenSigTimeout_CBC" SG_ 631 Tcase4Low 10500;
BA_ "GenSigSNA" SG_ 631 Tcase4Low "3h";
BA_ "GenSigSendType" SG_ 631 Tcase4Low 5;
BA_ "GenSigCycleTime" SG_ 631 Tcase4Low 1000;
BA_ "FlexKomSigStartValue" SG_ 631 Tcase4Low "0000000000000000h";
BA_ "FlexKomSigStartPos" SG_ 631 Tcase4Low 7;
BA_ "FlexKomSigName" SG_ 631 Tcase4Low "DTCM_B1_PKT";
BA_ "FlexKomSigLaenge" SG_ 631 Tcase4Low 64;
BA_ "FlexKomSID" SG_ 631 Tcase4Low 808;
BA_ "FlexKomIsMotorola" SG_ 631 Tcase4Low 1;
BA_ "FlexKomComment" SG_ 631 Tcase4Low "DTCM_B1_PKT";
BA_ "RID" SG_ 631 TcaseAWD "1635 1746";
BA_ "GenSigTimeout_IC" SG_ 631 TcaseAWD 10500;
BA_ "GenSigTimeout_ETM" SG_ 631 TcaseAWD 10500;
BA_ "GenSigTimeout_CBC" SG_ 631 TcaseAWD 10500;
BA_ "GenSigSNA" SG_ 631 TcaseAWD "3h";
BA_ "GenSigSendType" SG_ 631 TcaseAWD 5;
BA_ "GenSigCycleTime" SG_ 631 TcaseAWD 1000;
BA_ "FlexKomSigStartValue" SG_ 631 TcaseAWD "0000000000000000h";
BA_ "FlexKomSigStartPos" SG_ 631 TcaseAWD 7;
BA_ "FlexKomSigName" SG_ 631 TcaseAWD "DTCM_B1_PKT";
BA_ "FlexKomSigLaenge" SG_ 631 TcaseAWD 64;
BA_ "FlexKomSID" SG_ 631 TcaseAWD 808;
BA_ "FlexKomIsMotorola" SG_ 631 TcaseAWD 1;
BA_ "FlexKomComment" SG_ 631 TcaseAWD "DTCM_B1_PKT";
BA_ "RID" SG_ 631 TcaseNtrlStat "1638 1705";
BA_ "GenSigTimeout_IC" SG_ 631 TcaseNtrlStat 10500;
BA_ "GenSigTimeout_ETM" SG_ 631 TcaseNtrlStat 10500;
BA_ "GenSigTimeout_CBC" SG_ 631 TcaseNtrlStat 10500;
BA_ "GenSigSNA" SG_ 631 TcaseNtrlStat "3h";
BA_ "GenSigSendType" SG_ 631 TcaseNtrlStat 5;
BA_ "GenSigCycleTime" SG_ 631 TcaseNtrlStat 1000;
BA_ "FlexKomSigStartValue" SG_ 631 TcaseNtrlStat "0000000000000000h";
BA_ "FlexKomSigStartPos" SG_ 631 TcaseNtrlStat 7;
BA_ "FlexKomSigName" SG_ 631 TcaseNtrlStat "DTCM_B1_PKT";
BA_ "FlexKomSigLaenge" SG_ 631 TcaseNtrlStat 64;
BA_ "FlexKomSID" SG_ 631 TcaseNtrlStat 808;
BA_ "FlexKomIsMotorola" SG_ 631 TcaseNtrlStat 1;
BA_ "FlexKomComment" SG_ 631 TcaseNtrlStat "DTCM_B1_PKT";
BA_ "GenSigSNA" SG_ 1900 D_RQ_AHCP "0h";
BA_ "GenSigSendType" SG_ 1900 D_RQ_AHCP 1;
BA_ "FlexKomSigStartValue" SG_ 1900 D_RQ_AHCP "0000000000000000h";
BA_ "FlexKomSigStartPos" SG_ 1900 D_RQ_AHCP 7;
BA_ "FlexKomSigName" SG_ 1900 D_RQ_AHCP "D_RQ_AHCP";
BA_ "FlexKomSigLaenge" SG_ 1900 D_RQ_AHCP 64;
BA_ "FlexKomSID" SG_ 1900 D_RQ_AHCP 2517;
BA_ "FlexKomIsMotorola" SG_ 1900 D_RQ_AHCP 1;
BA_ "FlexKomComment" SG_ 1900 D_RQ_AHCP "Diagnostic-Request";
BA_ "GenSigSNA" SG_ 1897 D_RQ_AHLM "0h";
BA_ "GenSigSendType" SG_ 1897 D_RQ_AHLM 1;
BA_ "FlexKomSigStartValue" SG_ 1897 D_RQ_AHLM "0000000000000000h";
BA_ "FlexKomSigStartPos" SG_ 1897 D_RQ_AHLM 7;
BA_ "FlexKomSigName" SG_ 1897 D_RQ_AHLM "D_RQ_AHLM";
BA_ "FlexKomSigLaenge" SG_ 1897 D_RQ_AHLM 64;
BA_ "FlexKomSID" SG_ 1897 D_RQ_AHLM 73;
BA_ "FlexKomIsMotorola" SG_ 1897 D_RQ_AHLM 1;
BA_ "FlexKomComment" SG_ 1897 D_RQ_AHLM "Diagnostic-Request";
BA_ "GenSigSNA" SG_ 1866 D_RQ_ASBS "0h";
BA_ "GenSigSendType" SG_ 1866 D_RQ_ASBS 1;
BA_ "FlexKomSigStartValue" SG_ 1866 D_RQ_ASBS "0000000000000000h";
BA_ "FlexKomSigStartPos" SG_ 1866 D_RQ_ASBS 7;
BA_ "FlexKomSigName" SG_ 1866 D_RQ_ASBS "D_RQ_ASBS";
BA_ "FlexKomSigLaenge" SG_ 1866 D_RQ_ASBS 64;
BA_ "FlexKomSID" SG_ 1866 D_RQ_ASBS 2621;
BA_ "FlexKomIsMotorola" SG_ 1866 D_RQ_ASBS 1;
BA_ "FlexKomComment" SG_ 1866 D_RQ_ASBS "Diagnostic-Request";
BA_ "GenSigSNA" SG_ 2023 D_RQ_BPCM "0h";
BA_ "GenSigSendType" SG_ 2023 D_RQ_BPCM 1;
BA_ "FlexKomSigStartValue" SG_ 2023 D_RQ_BPCM "0000000000000000h";
BA_ "FlexKomSigStartPos" SG_ 2023 D_RQ_BPCM 7;
BA_ "FlexKomSigName" SG_ 2023 D_RQ_BPCM "D_RQ_BPCM";
BA_ "FlexKomSigLaenge" SG_ 2023 D_RQ_BPCM 64;
BA_ "FlexKomSID" SG_ 2023 D_RQ_BPCM 2138;
BA_ "FlexKomIsMotorola" SG_ 2023 D_RQ_BPCM 1;
BA_ "FlexKomComment" SG_ 2023 D_RQ_BPCM "Diagnostic-Request";
BA_ "GenSigSNA" SG_ 2020 D_RQ_BSMO "0h";
BA_ "GenSigSendType" SG_ 2020 D_RQ_BSMO 1;
BA_ "FlexKomSigStartValue" SG_ 2020 D_RQ_BSMO "0000000000000000h";
BA_ "FlexKomSigStartPos" SG_ 2020 D_RQ_BSMO 7;
BA_ "FlexKomSigName" SG_ 2020 D_RQ_BSMO "D_RQ_BSMO";
BA_ "FlexKomSigLaenge" SG_ 2020 D_RQ_BSMO 64;
BA_ "FlexKomSID" SG_ 2020 D_RQ_BSMO 2284;
BA_ "FlexKomIsMotorola" SG_ 2020 D_RQ_BSMO 1;
BA_ "FlexKomComment" SG_ 2020 D_RQ_BSMO "Diagnostic-Request";
BA_ "GenSigSNA" SG_ 1568 D_RQ_CBC "0h";
BA_ "GenSigSendType" SG_ 1568 D_RQ_CBC 1;
BA_ "FlexKomSigStartValue" SG_ 1568 D_RQ_CBC "0000000000000000h";
BA_ "FlexKomSigStartPos" SG_ 1568 D_RQ_CBC 7;
BA_ "FlexKomSigName" SG_ 1568 D_RQ_CBC "D_RQ_CBC";
BA_ "FlexKomSigLaenge" SG_ 1568 D_RQ_CBC 64;
BA_ "FlexKomSID" SG_ 1568 D_RQ_CBC 78;
BA_ "FlexKomIsMotorola" SG_ 1568 D_RQ_CBC 1;
BA_ "FlexKomComment" SG_ 1568 D_RQ_CBC "Diagnostic-Request";
BA_ "GenSigSNA" SG_ 1875 D_RQ_DASM "0h";
BA_ "GenSigSendType" SG_ 1875 D_RQ_DASM 1;
BA_ "FlexKomSigStartValue" SG_ 1875 D_RQ_DASM "0000000000000000h";
BA_ "FlexKomSigStartPos" SG_ 1875 D_RQ_DASM 7;
BA_ "FlexKomSigName" SG_ 1875 D_RQ_DASM "D_RQ_DASM";
BA_ "FlexKomSigLaenge" SG_ 1875 D_RQ_DASM 64;
BA_ "FlexKomSID" SG_ 1875 D_RQ_DASM 97;
BA_ "FlexKomIsMotorola" SG_ 1875 D_RQ_DASM 1;
BA_ "FlexKomComment" SG_ 1875 D_RQ_DASM "Diagnostic-Request";
BA_ "GenSigSNA" SG_ 1873 D_RQ_DPDM "0h";
BA_ "GenSigSendType" SG_ 1873 D_RQ_DPDM 1;
BA_ "FlexKomSigStartValue" SG_ 1873 D_RQ_DPDM "0000000000000000h";
BA_ "FlexKomSigStartPos" SG_ 1873 D_RQ_DPDM 7;
BA_ "FlexKomSigName" SG_ 1873 D_RQ_DPDM "D_RQ_DPDM";
BA_ "FlexKomSigLaenge" SG_ 1873 D_RQ_DPDM 64;
BA_ "FlexKomSID" SG_ 1873 D_RQ_DPDM 2660;
BA_ "FlexKomIsMotorola" SG_ 1873 D_RQ_DPDM 1;
BA_ "FlexKomComment" SG_ 1873 D_RQ_DPDM "Diagnostic-Request";
BA_ "GenSigSNA" SG_ 1867 D_RQ_DTCM "0h";
BA_ "GenSigSendType" SG_ 1867 D_RQ_DTCM 1;
BA_ "FlexKomSigStartValue" SG_ 1867 D_RQ_DTCM "0000000000000000h";
BA_ "FlexKomSigStartPos" SG_ 1867 D_RQ_DTCM 7;
BA_ "FlexKomSigName" SG_ 1867 D_RQ_DTCM "D_RQ_DTCM";
BA_ "FlexKomSigLaenge" SG_ 1867 D_RQ_DTCM 64;
BA_ "FlexKomSID" SG_ 1867 D_RQ_DTCM 84;
BA_ "FlexKomIsMotorola" SG_ 1867 D_RQ_DTCM 1;
BA_ "FlexKomComment" SG_ 1867 D_RQ_DTCM "Diagnostic-Request";
BA_ "GenSigSNA" SG_ 2016 D_RQ_ECM "0h";
BA_ "GenSigSendType" SG_ 2016 D_RQ_ECM 1;
BA_ "FlexKomSigStartValue" SG_ 2016 D_RQ_ECM "0000000000000000h";
BA_ "FlexKomSigStartPos" SG_ 2016 D_RQ_ECM 7;
BA_ "FlexKomSigName" SG_ 2016 D_RQ_ECM "D_RQ_ECM";
BA_ "FlexKomSigLaenge" SG_ 2016 D_RQ_ECM 64;
BA_ "FlexKomSID" SG_ 2016 D_RQ_ECM 85;
BA_ "FlexKomIsMotorola" SG_ 2016 D_RQ_ECM 1;
BA_ "FlexKomComment" SG_ 2016 D_RQ_ECM "Diagnostic-Request";
BA_ "GenSigSNA" SG_ 1882 D_RQ_EPS "0h";
BA_ "GenSigSendType" SG_ 1882 D_RQ_EPS 1;
BA_ "FlexKomSigStartValue" SG_ 1882 D_RQ_EPS "0000000000000000h";
BA_ "FlexKomSigStartPos" SG_ 1882 D_RQ_EPS 7;
BA_ "FlexKomSigName" SG_ 1882 D_RQ_EPS "D_RQ_EPS";
BA_ "FlexKomSigLaenge" SG_ 1882 D_RQ_EPS 64;
BA_ "FlexKomSID" SG_ 1882 D_RQ_EPS 87;
BA_ "FlexKomIsMotorola" SG_ 1882 D_RQ_EPS 1;
BA_ "FlexKomComment" SG_ 1882 D_RQ_EPS "Diagnostic-Request";
BA_ "GenSigSNA" SG_ 1863 D_RQ_ESC "0h";
BA_ "GenSigSendType" SG_ 1863 D_RQ_ESC 1;
BA_ "FlexKomSigStartValue" SG_ 1863 D_RQ_ESC "0000000000000000h";
BA_ "FlexKomSigStartPos" SG_ 1863 D_RQ_ESC 7;
BA_ "FlexKomSigName" SG_ 1863 D_RQ_ESC "D_RQ_ESC";
BA_ "FlexKomSigLaenge" SG_ 1863 D_RQ_ESC 64;
BA_ "FlexKomSID" SG_ 1863 D_RQ_ESC 14;
BA_ "FlexKomIsMotorola" SG_ 1863 D_RQ_ESC 1;
BA_ "FlexKomComment" SG_ 1863 D_RQ_ESC "Diagnostic-Request";
BA_ "GenSigSNA" SG_ 1864 D_RQ_ESL "0h";
BA_ "GenSigSendType" SG_ 1864 D_RQ_ESL 1;
BA_ "FlexKomSigStartValue" SG_ 1864 D_RQ_ESL "0000000000000000h";
BA_ "FlexKomSigStartPos" SG_ 1864 D_RQ_ESL 7;
BA_ "FlexKomSigName" SG_ 1864 D_RQ_ESL "D_RQ_ESL";
BA_ "FlexKomSigLaenge" SG_ 1864 D_RQ_ESL 64;
BA_ "FlexKomSID" SG_ 1864 D_RQ_ESL 2339;
BA_ "FlexKomIsMotorola" SG_ 1864 D_RQ_ESL 1;
BA_ "FlexKomComment" SG_ 1864 D_RQ_ESL "Diagnostic-Request";
BA_ "GenSigSNA" SG_ 1865 D_RQ_ESM "0h";
BA_ "GenSigSendType" SG_ 1865 D_RQ_ESM 1;
BA_ "FlexKomSigStartValue" SG_ 1865 D_RQ_ESM "0000000000000000h";
BA_ "FlexKomSigStartPos" SG_ 1865 D_RQ_ESM 7;
BA_ "FlexKomSigName" SG_ 1865 D_RQ_ESM "D_RQ_ESM";
BA_ "FlexKomSigLaenge" SG_ 1865 D_RQ_ESM 64;
BA_ "FlexKomSID" SG_ 1865 D_RQ_ESM 90;
BA_ "FlexKomIsMotorola" SG_ 1865 D_RQ_ESM 1;
BA_ "FlexKomComment" SG_ 1865 D_RQ_ESM "Diagnostic-Request";
BA_ "GenSigSNA" SG_ 1906 D_RQ_GPF "0h";
BA_ "GenSigSendType" SG_ 1906 D_RQ_GPF 1;
BA_ "FlexKomSigStartValue" SG_ 1906 D_RQ_GPF "0000000000000000h";
BA_ "FlexKomSigStartPos" SG_ 1906 D_RQ_GPF 7;
BA_ "FlexKomSigName" SG_ 1906 D_RQ_GPF "D_RQ_EPS";
BA_ "FlexKomSigLaenge" SG_ 1906 D_RQ_GPF 64;
BA_ "FlexKomSID" SG_ 1906 D_RQ_GPF 2826;
BA_ "FlexKomIsMotorola" SG_ 1906 D_RQ_GPF 1;
BA_ "FlexKomComment" SG_ 1906 D_RQ_GPF "Diagnostic-Request";
BA_ "GenSigSNA" SG_ 2018 D_RQ_HCP "0h";
BA_ "GenSigSendType" SG_ 2018 D_RQ_HCP 1;
BA_ "FlexKomSigStartValue" SG_ 2018 D_RQ_HCP "0000000000000000h";
BA_ "FlexKomSigStartPos" SG_ 2018 D_RQ_HCP 7;
BA_ "FlexKomSigName" SG_ 2018 D_RQ_HCP "D_RQ_HCP";
BA_ "FlexKomSigLaenge" SG_ 2018 D_RQ_HCP 64;
BA_ "FlexKomSID" SG_ 2018 D_RQ_HCP 2118;
BA_ "FlexKomIsMotorola" SG_ 2018 D_RQ_HCP 1;
BA_ "FlexKomComment" SG_ 2018 D_RQ_HCP "Diagnostic-Request";
BA_ "GenSigSNA" SG_ 1858 D_RQ_IC "0h";
BA_ "GenSigSendType" SG_ 1858 D_RQ_IC 1;
BA_ "FlexKomSigStartValue" SG_ 1858 D_RQ_IC "0000000000000000h";
BA_ "FlexKomSigStartPos" SG_ 1858 D_RQ_IC 7;
BA_ "FlexKomSigName" SG_ 1858 D_RQ_IC "D_RQ_IC";
BA_ "FlexKomSigLaenge" SG_ 1858 D_RQ_IC 64;
BA_ "FlexKomSID" SG_ 1858 D_RQ_IC 95;
BA_ "FlexKomIsMotorola" SG_ 1858 D_RQ_IC 1;
BA_ "FlexKomComment" SG_ 1858 D_RQ_IC "Diagnostic-Request";
BA_ "GenSigSNA" SG_ 1901 D_RQ_IDCM "0h";
BA_ "GenSigSendType" SG_ 1901 D_RQ_IDCM 1;
BA_ "FlexKomSigStartValue" SG_ 1901 D_RQ_IDCM "0000000000000000h";
BA_ "FlexKomSigStartPos" SG_ 1901 D_RQ_IDCM 7;
BA_ "FlexKomSigName" SG_ 1901 D_RQ_IDCM "D_RQ_IDCM";
BA_ "FlexKomSigLaenge" SG_ 1901 D_RQ_IDCM 64;
BA_ "FlexKomSID" SG_ 1901 D_RQ_IDCM 2967;
BA_ "FlexKomIsMotorola" SG_ 1901 D_RQ_IDCM 1;
BA_ "FlexKomComment" SG_ 1901 D_RQ_IDCM "Diagnostic-Request";
BA_ "GenSigSNA" SG_ 1886 D_RQ_OCM "0h";
BA_ "GenSigSendType" SG_ 1886 D_RQ_OCM 1;
BA_ "FlexKomSigStartValue" SG_ 1886 D_RQ_OCM "0000000000000000h";
BA_ "FlexKomSigStartPos" SG_ 1886 D_RQ_OCM 7;
BA_ "FlexKomSigName" SG_ 1886 D_RQ_OCM "D_RQ_OCM";
BA_ "FlexKomSigLaenge" SG_ 1886 D_RQ_OCM 64;
BA_ "FlexKomSID" SG_ 1886 D_RQ_OCM 1536;
BA_ "FlexKomIsMotorola" SG_ 1886 D_RQ_OCM 1;
BA_ "FlexKomComment" SG_ 1886 D_RQ_OCM "Diagnostic-Request";
BA_ "GenSigSNA" SG_ 1860 D_RQ_ORC "0h";
BA_ "GenSigSendType" SG_ 1860 D_RQ_ORC 1;
BA_ "FlexKomSigStartValue" SG_ 1860 D_RQ_ORC "0000000000000000h";
BA_ "FlexKomSigStartPos" SG_ 1860 D_RQ_ORC 7;
BA_ "FlexKomSigName" SG_ 1860 D_RQ_ORC "D_RQ_ORC";
BA_ "FlexKomSigLaenge" SG_ 1860 D_RQ_ORC 64;
BA_ "FlexKomSID" SG_ 1860 D_RQ_ORC 101;
BA_ "FlexKomIsMotorola" SG_ 1860 D_RQ_ORC 1;
BA_ "FlexKomComment" SG_ 1860 D_RQ_ORC "Diagnostic-Request";
BA_ "GenSigSNA" SG_ 1890 D_RQ_PTS "0h";
BA_ "GenSigSendType" SG_ 1890 D_RQ_PTS 1;
BA_ "FlexKomSigStartValue" SG_ 1890 D_RQ_PTS "0000000000000000h";
BA_ "FlexKomSigStartPos" SG_ 1890 D_RQ_PTS 7;
BA_ "FlexKomSigName" SG_ 1890 D_RQ_PTS "D_RQ_PTS";
BA_ "FlexKomSigLaenge" SG_ 1890 D_RQ_PTS 64;
BA_ "FlexKomSID" SG_ 1890 D_RQ_PTS 109;
BA_ "FlexKomIsMotorola" SG_ 1890 D_RQ_PTS 1;
BA_ "FlexKomComment" SG_ 1890 D_RQ_PTS "Diagnostic-Request";
BA_ "GenSigSNA" SG_ 1856 D_RQ_RF_HUB "0h";
BA_ "GenSigSendType" SG_ 1856 D_RQ_RF_HUB 1;
BA_ "FlexKomSigStartValue" SG_ 1856 D_RQ_RF_HUB "0000000000000000h";
BA_ "FlexKomSigStartPos" SG_ 1856 D_RQ_RF_HUB 7;
BA_ "FlexKomSigName" SG_ 1856 D_RQ_RF_HUB "D_RQ_RF_HUB";
BA_ "FlexKomSigLaenge" SG_ 1856 D_RQ_RF_HUB 64;
BA_ "FlexKomSID" SG_ 1856 D_RQ_RF_HUB 92;
BA_ "FlexKomIsMotorola" SG_ 1856 D_RQ_RF_HUB 1;
BA_ "FlexKomComment" SG_ 1856 D_RQ_RF_HUB "Diagnostic-Request";
BA_ "GenSigSNA" SG_ 1891 D_RQ_SCCM "0h";
BA_ "GenSigSendType" SG_ 1891 D_RQ_SCCM 1;
BA_ "FlexKomSigStartValue" SG_ 1891 D_RQ_SCCM "0000000000000000h";
BA_ "FlexKomSigStartPos" SG_ 1891 D_RQ_SCCM 7;
BA_ "FlexKomSigName" SG_ 1891 D_RQ_SCCM "D_RQ_SCCM";
BA_ "FlexKomSigLaenge" SG_ 1891 D_RQ_SCCM 64;
BA_ "FlexKomSID" SG_ 1891 D_RQ_SCCM 113;
BA_ "FlexKomIsMotorola" SG_ 1891 D_RQ_SCCM 1;
BA_ "FlexKomComment" SG_ 1891 D_RQ_SCCM "Diagnostic-Request";
BA_ "GenSigSNA" SG_ 1150 D_RQ_SGW "0h";
BA_ "GenSigSendType" SG_ 1150 D_RQ_SGW 1;
BA_ "FlexKomSigStartValue" SG_ 1150 D_RQ_SGW "0000000000000000h";
BA_ "FlexKomSigStartPos" SG_ 1150 D_RQ_SGW 7;
BA_ "FlexKomSigName" SG_ 1150 D_RQ_SGW "D_RQ_SGW";
BA_ "FlexKomSigLaenge" SG_ 1150 D_RQ_SGW 64;
BA_ "FlexKomSID" SG_ 1150 D_RQ_SGW 2610;
BA_ "FlexKomIsMotorola" SG_ 1150 D_RQ_SGW 1;
BA_ "FlexKomComment" SG_ 1150 D_RQ_SGW "Diagnostic-Request";
BA_ "GenSigSNA" SG_ 1963 D_RQ_TBM "0h";
BA_ "GenSigSendType" SG_ 1963 D_RQ_TBM 1;
BA_ "FlexKomSigStartValue" SG_ 1963 D_RQ_TBM "0000000000000000h";
BA_ "FlexKomSigStartPos" SG_ 1963 D_RQ_TBM 7;
BA_ "FlexKomSigName" SG_ 1963 D_RQ_TBM "D_RQ_TBM";
BA_ "FlexKomSigLaenge" SG_ 1963 D_RQ_TBM 64;
BA_ "FlexKomSID" SG_ 1963 D_RQ_TBM 2430;
BA_ "FlexKomIsMotorola" SG_ 1963 D_RQ_TBM 1;
BA_ "FlexKomComment" SG_ 1963 D_RQ_TBM "Diagnostic-Request";
BA_ "GenSigSNA" SG_ 2017 D_RQ_TCM "0h";
BA_ "GenSigSendType" SG_ 2017 D_RQ_TCM 1;
BA_ "FlexKomSigStartValue" SG_ 2017 D_RQ_TCM "0000000000000000h";
BA_ "FlexKomSigStartPos" SG_ 2017 D_RQ_TCM 7;
BA_ "FlexKomSigName" SG_ 2017 D_RQ_TCM "D_RQ_TCM";
BA_ "FlexKomSigLaenge" SG_ 2017 D_RQ_TCM 64;
BA_ "FlexKomSID" SG_ 2017 D_RQ_TCM 117;
BA_ "FlexKomIsMotorola" SG_ 2017 D_RQ_TCM 1;
BA_ "FlexKomComment" SG_ 2017 D_RQ_TCM "Diagnostic-Request";
BA_ "GenSigSNA" SG_ 1859 D_RQ_TPM "0h";
BA_ "GenSigSendType" SG_ 1859 D_RQ_TPM 1;
BA_ "FlexKomSigStartValue" SG_ 1859 D_RQ_TPM "0000000000000000h";
BA_ "FlexKomSigStartPos" SG_ 1859 D_RQ_TPM 7;
BA_ "FlexKomSigName" SG_ 1859 D_RQ_TPM "D_RQ_TPM";
BA_ "FlexKomSigLaenge" SG_ 1859 D_RQ_TPM 64;
BA_ "FlexKomSID" SG_ 1859 D_RQ_TPM 120;
BA_ "FlexKomIsMotorola" SG_ 1859 D_RQ_TPM 1;
BA_ "FlexKomComment" SG_ 1859 D_RQ_TPM "Diagnostic-Request";
BA_ "GenSigSNA" SG_ 1260 D_RS_AHCP "0h";
BA_ "GenSigSendType" SG_ 1260 D_RS_AHCP 1;
BA_ "FlexKomSigStartValue" SG_ 1260 D_RS_AHCP "0000000000000000h";
BA_ "FlexKomSigStartPos" SG_ 1260 D_RS_AHCP 7;
BA_ "FlexKomSigName" SG_ 1260 D_RS_AHCP "D_RS_AHCP";
BA_ "FlexKomSigLaenge" SG_ 1260 D_RS_AHCP 64;
BA_ "FlexKomSID" SG_ 1260 D_RS_AHCP 2518;
BA_ "FlexKomIsMotorola" SG_ 1260 D_RS_AHCP 1;
BA_ "FlexKomComment" SG_ 1260 D_RS_AHCP "Diagnostic-Response";
BA_ "GenSigSNA" SG_ 1257 D_RS_AHLM "0h";
BA_ "GenSigSendType" SG_ 1257 D_RS_AHLM 1;
BA_ "FlexKomSigStartValue" SG_ 1257 D_RS_AHLM "0000000000000000h";
BA_ "FlexKomSigStartPos" SG_ 1257 D_RS_AHLM 7;
BA_ "FlexKomSigName" SG_ 1257 D_RS_AHLM "D_RS_AHLM";
BA_ "FlexKomSigLaenge" SG_ 1257 D_RS_AHLM 64;
BA_ "FlexKomSID" SG_ 1257 D_RS_AHLM 127;
BA_ "FlexKomIsMotorola" SG_ 1257 D_RS_AHLM 1;
BA_ "FlexKomComment" SG_ 1257 D_RS_AHLM "Diagnostic-Response";
BA_ "GenSigSNA" SG_ 1226 D_RS_ASBS "0h";
BA_ "GenSigSendType" SG_ 1226 D_RS_ASBS 1;
BA_ "FlexKomSigStartValue" SG_ 1226 D_RS_ASBS "0000000000000000h";
BA_ "FlexKomSigStartPos" SG_ 1226 D_RS_ASBS 7;
BA_ "FlexKomSigName" SG_ 1226 D_RS_ASBS "D_RS_ASBS";
BA_ "FlexKomSigLaenge" SG_ 1226 D_RS_ASBS 64;
BA_ "FlexKomSID" SG_ 1226 D_RS_ASBS 2623;
BA_ "FlexKomIsMotorola" SG_ 1226 D_RS_ASBS 1;
BA_ "FlexKomComment" SG_ 1226 D_RS_ASBS "Diagnostic-Response";
BA_ "GenSigSNA" SG_ 2031 D_RS_BPCM "0h";
BA_ "GenSigSendType" SG_ 2031 D_RS_BPCM 1;
BA_ "FlexKomSigStartValue" SG_ 2031 D_RS_BPCM "0000000000000000h";
BA_ "FlexKomSigStartPos" SG_ 2031 D_RS_BPCM 7;
BA_ "FlexKomSigName" SG_ 2031 D_RS_BPCM "D_RS_BPCM";
BA_ "FlexKomSigLaenge" SG_ 2031 D_RS_BPCM 64;
BA_ "FlexKomSID" SG_ 2031 D_RS_BPCM 2139;
BA_ "FlexKomIsMotorola" SG_ 2031 D_RS_BPCM 1;
BA_ "FlexKomComment" SG_ 2031 D_RS_BPCM "Diagnostic-Response";
BA_ "GenSigSNA" SG_ 2028 D_RS_BSMO "0h";
BA_ "GenSigSendType" SG_ 2028 D_RS_BSMO 1;
BA_ "FlexKomSigStartValue" SG_ 2028 D_RS_BSMO "0000000000000000h";
BA_ "FlexKomSigStartPos" SG_ 2028 D_RS_BSMO 7;
BA_ "FlexKomSigName" SG_ 2028 D_RS_BSMO "D_RS_BSMO";
BA_ "FlexKomSigLaenge" SG_ 2028 D_RS_BSMO 64;
BA_ "FlexKomSID" SG_ 2028 D_RS_BSMO 2281;
BA_ "FlexKomIsMotorola" SG_ 2028 D_RS_BSMO 1;
BA_ "FlexKomComment" SG_ 2028 D_RS_BSMO "Diagnostic-Response";
BA_ "GenSigSNA" SG_ 1284 D_RS_CBC "0h";
BA_ "GenSigSendType" SG_ 1284 D_RS_CBC 1;
BA_ "FlexKomSigStartValue" SG_ 1284 D_RS_CBC "0000000000000000h";
BA_ "FlexKomSigStartPos" SG_ 1284 D_RS_CBC 7;
BA_ "FlexKomSigName" SG_ 1284 D_RS_CBC "D_RS_CBC";
BA_ "FlexKomSigLaenge" SG_ 1284 D_RS_CBC 64;
BA_ "FlexKomSID" SG_ 1284 D_RS_CBC 132;
BA_ "FlexKomIsMotorola" SG_ 1284 D_RS_CBC 1;
BA_ "FlexKomComment" SG_ 1284 D_RS_CBC "Diagnostic-Response";
BA_ "GenSigSNA" SG_ 1235 D_RS_DASM "0h";
BA_ "GenSigSendType" SG_ 1235 D_RS_DASM 1;
BA_ "FlexKomSigStartValue" SG_ 1235 D_RS_DASM "0000000000000000h";
BA_ "FlexKomSigStartPos" SG_ 1235 D_RS_DASM 7;
BA_ "FlexKomSigName" SG_ 1235 D_RS_DASM "D_RS_DASM";
BA_ "FlexKomSigLaenge" SG_ 1235 D_RS_DASM 64;
BA_ "FlexKomSID" SG_ 1235 D_RS_DASM 149;
BA_ "FlexKomIsMotorola" SG_ 1235 D_RS_DASM 1;
BA_ "FlexKomComment" SG_ 1235 D_RS_DASM "Diagnostic-Response";
BA_ "GenSigSNA" SG_ 1233 D_RS_DPDM "0h";
BA_ "GenSigSendType" SG_ 1233 D_RS_DPDM 1;
BA_ "FlexKomSigStartValue" SG_ 1233 D_RS_DPDM "0000000000000000h";
BA_ "FlexKomSigStartPos" SG_ 1233 D_RS_DPDM 7;
BA_ "FlexKomSigName" SG_ 1233 D_RS_DPDM "D_RS_DPDM";
BA_ "FlexKomSigLaenge" SG_ 1233 D_RS_DPDM 64;
BA_ "FlexKomSID" SG_ 1233 D_RS_DPDM 2661;
BA_ "FlexKomIsMotorola" SG_ 1233 D_RS_DPDM 1;
BA_ "FlexKomComment" SG_ 1233 D_RS_DPDM "Diagnostic-Response";
BA_ "GenSigSNA" SG_ 1227 D_RS_DTCM "0h";
BA_ "GenSigSendType" SG_ 1227 D_RS_DTCM 1;
BA_ "FlexKomSigStartValue" SG_ 1227 D_RS_DTCM "0000000000000000h";
BA_ "FlexKomSigStartPos" SG_ 1227 D_RS_DTCM 7;
BA_ "FlexKomSigName" SG_ 1227 D_RS_DTCM "D_RS_DTCM";
BA_ "FlexKomSigLaenge" SG_ 1227 D_RS_DTCM 64;
BA_ "FlexKomSID" SG_ 1227 D_RS_DTCM 138;
BA_ "FlexKomIsMotorola" SG_ 1227 D_RS_DTCM 1;
BA_ "FlexKomComment" SG_ 1227 D_RS_DTCM "Diagnostic-Response";
BA_ "GenSigSNA" SG_ 2024 D_RS_ECM "0h";
BA_ "GenSigSendType" SG_ 2024 D_RS_ECM 1;
BA_ "FlexKomSigStartValue" SG_ 2024 D_RS_ECM "0000000000000000h";
BA_ "FlexKomSigStartPos" SG_ 2024 D_RS_ECM 7;
BA_ "FlexKomSigName" SG_ 2024 D_RS_ECM "D_RS_ECM";
BA_ "FlexKomSigLaenge" SG_ 2024 D_RS_ECM 64;
BA_ "FlexKomSID" SG_ 2024 D_RS_ECM 139;
BA_ "FlexKomIsMotorola" SG_ 2024 D_RS_ECM 1;
BA_ "FlexKomComment" SG_ 2024 D_RS_ECM "Diagnostic-Response";
BA_ "GenSigSNA" SG_ 1242 D_RS_EPS "0h";
BA_ "GenSigSendType" SG_ 1242 D_RS_EPS 1;
BA_ "FlexKomSigStartValue" SG_ 1242 D_RS_EPS "0000000000000000h";
BA_ "FlexKomSigStartPos" SG_ 1242 D_RS_EPS 7;
BA_ "FlexKomSigName" SG_ 1242 D_RS_EPS "D_RS_EPS";
BA_ "FlexKomSigLaenge" SG_ 1242 D_RS_EPS 64;
BA_ "FlexKomSID" SG_ 1242 D_RS_EPS 141;
BA_ "FlexKomIsMotorola" SG_ 1242 D_RS_EPS 1;
BA_ "FlexKomComment" SG_ 1242 D_RS_EPS "Diagnostic-Response";
BA_ "GenSigSNA" SG_ 1223 D_RS_ESC "0h";
BA_ "GenSigSendType" SG_ 1223 D_RS_ESC 1;
BA_ "FlexKomSigStartValue" SG_ 1223 D_RS_ESC "0000000000000000h";
BA_ "FlexKomSigStartPos" SG_ 1223 D_RS_ESC 7;
BA_ "FlexKomSigName" SG_ 1223 D_RS_ESC "D_RS_ESC";
BA_ "FlexKomSigLaenge" SG_ 1223 D_RS_ESC 64;
BA_ "FlexKomSID" SG_ 1223 D_RS_ESC 15;
BA_ "FlexKomIsMotorola" SG_ 1223 D_RS_ESC 1;
BA_ "FlexKomComment" SG_ 1223 D_RS_ESC "Diagnostic-Response";
BA_ "GenSigSNA" SG_ 1224 D_RS_ESL "0h";
BA_ "GenSigSendType" SG_ 1224 D_RS_ESL 1;
BA_ "FlexKomSigStartValue" SG_ 1224 D_RS_ESL "0000000000000000h";
BA_ "FlexKomSigStartPos" SG_ 1224 D_RS_ESL 7;
BA_ "FlexKomSigName" SG_ 1224 D_RS_ESL "D_RS_ESL";
BA_ "FlexKomSigLaenge" SG_ 1224 D_RS_ESL 64;
BA_ "FlexKomSID" SG_ 1224 D_RS_ESL 2340;
BA_ "FlexKomIsMotorola" SG_ 1224 D_RS_ESL 1;
BA_ "FlexKomComment" SG_ 1224 D_RS_ESL "Diagnostic-Response";
BA_ "GenSigSNA" SG_ 1225 D_RS_ESM "0h";
BA_ "GenSigSendType" SG_ 1225 D_RS_ESM 1;
BA_ "FlexKomSigStartValue" SG_ 1225 D_RS_ESM "0000000000000000h";
BA_ "FlexKomSigStartPos" SG_ 1225 D_RS_ESM 7;
BA_ "FlexKomSigName" SG_ 1225 D_RS_ESM "D_RS_ESM";
BA_ "FlexKomSigLaenge" SG_ 1225 D_RS_ESM 64;
BA_ "FlexKomSID" SG_ 1225 D_RS_ESM 142;
BA_ "FlexKomIsMotorola" SG_ 1225 D_RS_ESM 1;
BA_ "FlexKomComment" SG_ 1225 D_RS_ESM "Diagnostic-Response";
BA_ "GenSigSNA" SG_ 1266 D_RS_GPF "0h";
BA_ "GenSigSendType" SG_ 1266 D_RS_GPF 1;
BA_ "FlexKomSigStartValue" SG_ 1266 D_RS_GPF "0000000000000000h";
BA_ "FlexKomSigStartPos" SG_ 1266 D_RS_GPF 7;
BA_ "FlexKomSigName" SG_ 1266 D_RS_GPF "D_RS_GPF";
BA_ "FlexKomSigLaenge" SG_ 1266 D_RS_GPF 64;
BA_ "FlexKomSID" SG_ 1266 D_RS_GPF 2825;
BA_ "FlexKomIsMotorola" SG_ 1266 D_RS_GPF 1;
BA_ "FlexKomComment" SG_ 1266 D_RS_GPF "Diagnostic-Response";
BA_ "GenSigSNA" SG_ 2026 D_RS_HCP "0h";
BA_ "GenSigSendType" SG_ 2026 D_RS_HCP 1;
BA_ "FlexKomSigStartValue" SG_ 2026 D_RS_HCP "0000000000000000h";
BA_ "FlexKomSigStartPos" SG_ 2026 D_RS_HCP 7;
BA_ "FlexKomSigName" SG_ 2026 D_RS_HCP "D_RS_HCP";
BA_ "FlexKomSigLaenge" SG_ 2026 D_RS_HCP 64;
BA_ "FlexKomSID" SG_ 2026 D_RS_HCP 2119;
BA_ "FlexKomIsMotorola" SG_ 2026 D_RS_HCP 1;
BA_ "FlexKomComment" SG_ 2026 D_RS_HCP "Diagnostic-Response";
BA_ "GenSigSNA" SG_ 1218 D_RS_IC "0h";
BA_ "GenSigSendType" SG_ 1218 D_RS_IC 1;
BA_ "FlexKomSigStartValue" SG_ 1218 D_RS_IC "0000000000000000h";
BA_ "FlexKomSigStartPos" SG_ 1218 D_RS_IC 7;
BA_ "FlexKomSigName" SG_ 1218 D_RS_IC "D_RS_IC";
BA_ "FlexKomSigLaenge" SG_ 1218 D_RS_IC 64;
BA_ "FlexKomSID" SG_ 1218 D_RS_IC 147;
BA_ "FlexKomIsMotorola" SG_ 1218 D_RS_IC 1;
BA_ "FlexKomComment" SG_ 1218 D_RS_IC "Diagnostic-Response";
BA_ "GenSigSNA" SG_ 1261 D_RS_IDCM "0h";
BA_ "GenSigSendType" SG_ 1261 D_RS_IDCM 1;
BA_ "FlexKomSigStartValue" SG_ 1261 D_RS_IDCM "0000000000000000h";
BA_ "FlexKomSigStartPos" SG_ 1261 D_RS_IDCM 7;
BA_ "FlexKomSigName" SG_ 1261 D_RS_IDCM "D_RS_IDCM";
BA_ "FlexKomSigLaenge" SG_ 1261 D_RS_IDCM 64;
BA_ "FlexKomSID" SG_ 1261 D_RS_IDCM 2968;
BA_ "FlexKomIsMotorola" SG_ 1261 D_RS_IDCM 1;
BA_ "FlexKomComment" SG_ 1261 D_RS_IDCM "Diagnostic-Response";
BA_ "GenSigSNA" SG_ 1246 D_RS_OCM "0h";
BA_ "GenSigSendType" SG_ 1246 D_RS_OCM 1;
BA_ "FlexKomSigStartValue" SG_ 1246 D_RS_OCM "0000000000000000h";
BA_ "FlexKomSigStartPos" SG_ 1246 D_RS_OCM 7;
BA_ "FlexKomSigName" SG_ 1246 D_RS_OCM "D_RS_OCM";
BA_ "FlexKomSigLaenge" SG_ 1246 D_RS_OCM 64;
BA_ "FlexKomSID" SG_ 1246 D_RS_OCM 1537;
BA_ "FlexKomIsMotorola" SG_ 1246 D_RS_OCM 1;
BA_ "FlexKomComment" SG_ 1246 D_RS_OCM "Diagnostic-Response";
BA_ "GenSigSNA" SG_ 1220 D_RS_ORC "0h";
BA_ "GenSigSendType" SG_ 1220 D_RS_ORC 1;
BA_ "FlexKomSigStartValue" SG_ 1220 D_RS_ORC "0000000000000000h";
BA_ "FlexKomSigStartPos" SG_ 1220 D_RS_ORC 7;
BA_ "FlexKomSigName" SG_ 1220 D_RS_ORC "D_RS_ORC";
BA_ "FlexKomSigLaenge" SG_ 1220 D_RS_ORC 64;
BA_ "FlexKomSID" SG_ 1220 D_RS_ORC 153;
BA_ "FlexKomIsMotorola" SG_ 1220 D_RS_ORC 1;
BA_ "FlexKomComment" SG_ 1220 D_RS_ORC "Diagnostic-Response";
BA_ "GenSigSNA" SG_ 1250 D_RS_PTS "0h";
BA_ "GenSigSendType" SG_ 1250 D_RS_PTS 1;
BA_ "FlexKomSigStartValue" SG_ 1250 D_RS_PTS "0000000000000000h";
BA_ "FlexKomSigStartPos" SG_ 1250 D_RS_PTS 7;
BA_ "FlexKomSigName" SG_ 1250 D_RS_PTS "D_RS_PTS";
BA_ "FlexKomSigLaenge" SG_ 1250 D_RS_PTS 64;
BA_ "FlexKomSID" SG_ 1250 D_RS_PTS 161;
BA_ "FlexKomIsMotorola" SG_ 1250 D_RS_PTS 1;
BA_ "FlexKomComment" SG_ 1250 D_RS_PTS "Diagnostic-Response";
BA_ "GenSigSNA" SG_ 1216 D_RS_RF_HUB "0h";
BA_ "GenSigSendType" SG_ 1216 D_RS_RF_HUB 1;
BA_ "FlexKomSigStartValue" SG_ 1216 D_RS_RF_HUB "0000000000000000h";
BA_ "FlexKomSigStartPos" SG_ 1216 D_RS_RF_HUB 7;
BA_ "FlexKomSigName" SG_ 1216 D_RS_RF_HUB "D_RS_RF_HUB";
BA_ "FlexKomSigLaenge" SG_ 1216 D_RS_RF_HUB 64;
BA_ "FlexKomSID" SG_ 1216 D_RS_RF_HUB 144;
BA_ "FlexKomIsMotorola" SG_ 1216 D_RS_RF_HUB 1;
BA_ "FlexKomComment" SG_ 1216 D_RS_RF_HUB "Diagnostic-Response";
BA_ "GenSigSNA" SG_ 1251 D_RS_SCCM "0h";
BA_ "GenSigSendType" SG_ 1251 D_RS_SCCM 1;
BA_ "FlexKomSigStartValue" SG_ 1251 D_RS_SCCM "0000000000000000h";
BA_ "FlexKomSigStartPos" SG_ 1251 D_RS_SCCM 7;
BA_ "FlexKomSigName" SG_ 1251 D_RS_SCCM "D_RS_SCCM";
BA_ "FlexKomSigLaenge" SG_ 1251 D_RS_SCCM 64;
BA_ "FlexKomSID" SG_ 1251 D_RS_SCCM 165;
BA_ "FlexKomIsMotorola" SG_ 1251 D_RS_SCCM 1;
BA_ "FlexKomComment" SG_ 1251 D_RS_SCCM "Diagnostic-Response";
BA_ "GenSigSNA" SG_ 1151 D_RS_SGW "0h";
BA_ "GenSigSendType" SG_ 1151 D_RS_SGW 1;
BA_ "FlexKomSigStartValue" SG_ 1151 D_RS_SGW "0000000000000000h";
BA_ "FlexKomSigStartPos" SG_ 1151 D_RS_SGW 7;
BA_ "FlexKomSigName" SG_ 1151 D_RS_SGW "D_RS_SGW";
BA_ "FlexKomSigLaenge" SG_ 1151 D_RS_SGW 64;
BA_ "FlexKomSID" SG_ 1151 D_RS_SGW 2611;
BA_ "FlexKomIsMotorola" SG_ 1151 D_RS_SGW 1;
BA_ "FlexKomComment" SG_ 1151 D_RS_SGW "Diagnostic-Response";
BA_ "GenSigSNA" SG_ 1323 D_RS_TBM "0h";
BA_ "GenSigSendType" SG_ 1323 D_RS_TBM 1;
BA_ "FlexKomSigStartValue" SG_ 1323 D_RS_TBM "0000000000000000h";
BA_ "FlexKomSigStartPos" SG_ 1323 D_RS_TBM 7;
BA_ "FlexKomSigName" SG_ 1323 D_RS_TBM "D_RS_TBM";
BA_ "FlexKomSigLaenge" SG_ 1323 D_RS_TBM 64;
BA_ "FlexKomSID" SG_ 1323 D_RS_TBM 2431;
BA_ "FlexKomIsMotorola" SG_ 1323 D_RS_TBM 1;
BA_ "FlexKomComment" SG_ 1323 D_RS_TBM "Diagnostic-Response";
BA_ "GenSigSNA" SG_ 2025 D_RS_TCM "0h";
BA_ "GenSigSendType" SG_ 2025 D_RS_TCM 1;
BA_ "FlexKomSigStartValue" SG_ 2025 D_RS_TCM "0000000000000000h";
BA_ "FlexKomSigStartPos" SG_ 2025 D_RS_TCM 7;
BA_ "FlexKomSigName" SG_ 2025 D_RS_TCM "D_RS_TCM";
BA_ "FlexKomSigLaenge" SG_ 2025 D_RS_TCM 64;
BA_ "FlexKomSID" SG_ 2025 D_RS_TCM 169;
BA_ "FlexKomIsMotorola" SG_ 2025 D_RS_TCM 1;
BA_ "FlexKomComment" SG_ 2025 D_RS_TCM "Diagnostic-Response";
BA_ "GenSigSNA" SG_ 1219 D_RS_TPM "0h";
BA_ "GenSigSendType" SG_ 1219 D_RS_TPM 1;
BA_ "FlexKomSigStartValue" SG_ 1219 D_RS_TPM "0000000000000000h";
BA_ "FlexKomSigStartPos" SG_ 1219 D_RS_TPM 7;
BA_ "FlexKomSigName" SG_ 1219 D_RS_TPM "D_RS_TPM";
BA_ "FlexKomSigLaenge" SG_ 1219 D_RS_TPM 64;
BA_ "FlexKomSID" SG_ 1219 D_RS_TPM 172;
BA_ "FlexKomIsMotorola" SG_ 1219 D_RS_TPM 1;
BA_ "FlexKomComment" SG_ 1219 D_RS_TPM "Diagnostic-Response";
BA_ "GenSigStartValue" SG_ 37 CRC_ECM_A1 255;
BA_ "GenSigSNA" SG_ 37 CRC_ECM_A1 "FFh";
BA_ "GenSigCycleTime" SG_ 37 CRC_ECM_A1 10;
BA_ "FlexKomSigStartValue" SG_ 37 CRC_ECM_A1 "FFFF1FFF1FFF00FFh";
BA_ "FlexKomSigStartPos" SG_ 37 CRC_ECM_A1 7;
BA_ "FlexKomSigName" SG_ 37 CRC_ECM_A1 "ECM_A1_PKT";
BA_ "FlexKomSigLaenge" SG_ 37 CRC_ECM_A1 64;
BA_ "FlexKomSID" SG_ 37 CRC_ECM_A1 446;
BA_ "FlexKomIsMotorola" SG_ 37 CRC_ECM_A1 1;
BA_ "FlexKomComment" SG_ 37 CRC_ECM_A1 "ECM_A1 Packet";
BA_ "GenSigSNA" SG_ 37 ECM_LHOM_Trans "0h";
BA_ "GenSigCycleTime" SG_ 37 ECM_LHOM_Trans 10;
BA_ "FlexKomSigStartValue" SG_ 37 ECM_LHOM_Trans "FFFF1FFF1FFF00FFh";
BA_ "FlexKomSigStartPos" SG_ 37 ECM_LHOM_Trans 7;
BA_ "FlexKomSigName" SG_ 37 ECM_LHOM_Trans "ECM_A1_PKT";
BA_ "FlexKomSigLaenge" SG_ 37 ECM_LHOM_Trans 64;
BA_ "FlexKomSID" SG_ 37 ECM_LHOM_Trans 446;
BA_ "FlexKomIsMotorola" SG_ 37 ECM_LHOM_Trans 1;
BA_ "FlexKomComment" SG_ 37 ECM_LHOM_Trans "ECM_A1 Packet";
BA_ "RID" SG_ 37 EngRPM "2185";
BA_ "GenSigTimeout_TPM" SG_ 37 EngRPM 105;
BA_ "GenSigTimeout_TCM" SG_ 37 EngRPM 105;
BA_ "GenSigTimeout_ORC" SG_ 37 EngRPM 35;
BA_ "GenSigTimeout_IC" SG_ 37 EngRPM 105;
BA_ "GenSigTimeout_ESM" SG_ 37 EngRPM 105;
BA_ "GenSigTimeout_EHPS" SG_ 37 EngRPM 105;
BA_ "GenSigTimeout_DTCM" SG_ 37 EngRPM 105;
BA_ "GenSigTimeout_CBC" SG_ 37 EngRPM 105;
BA_ "GenSigStartValue" SG_ 37 EngRPM 65535;
BA_ "GenSigSNA" SG_ 37 EngRPM "FFFFh";
BA_ "GenSigCycleTime" SG_ 37 EngRPM 10;
BA_ "FlexKomSigStartValue" SG_ 37 EngRPM "FFFF1FFF1FFF00FFh";
BA_ "FlexKomSigStartPos" SG_ 37 EngRPM 7;
BA_ "FlexKomSigName" SG_ 37 EngRPM "ECM_A1_PKT";
BA_ "FlexKomSigLaenge" SG_ 37 EngRPM 64;
BA_ "FlexKomSID" SG_ 37 EngRPM 446;
BA_ "FlexKomIsMotorola" SG_ 37 EngRPM 1;
BA_ "FlexKomComment" SG_ 37 EngRPM "ECM_A1 Packet";
BA_ "RID" SG_ 37 EngTrqStatic "2184";
BA_ "GenSigTimeout_TCM" SG_ 37 EngTrqStatic 105;
BA_ "GenSigTimeout_IC" SG_ 37 EngTrqStatic 105;
BA_ "GenSigTimeout_DTCM" SG_ 37 EngTrqStatic 105;
BA_ "GenSigTimeout_CBC" SG_ 37 EngTrqStatic 105;
BA_ "GenSigStartValue" SG_ 37 EngTrqStatic 8191;
BA_ "GenSigSNA" SG_ 37 EngTrqStatic "1FFFh";
BA_ "GenSigCycleTime" SG_ 37 EngTrqStatic 10;
BA_ "FlexKomSigStartValue" SG_ 37 EngTrqStatic "FFFF1FFF1FFF00FFh";
BA_ "FlexKomSigStartPos" SG_ 37 EngTrqStatic 7;
BA_ "FlexKomSigName" SG_ 37 EngTrqStatic "ECM_A1_PKT";
BA_ "FlexKomSigLaenge" SG_ 37 EngTrqStatic 64;
BA_ "FlexKomSID" SG_ 37 EngTrqStatic 446;
BA_ "FlexKomIsMotorola" SG_ 37 EngTrqStatic 1;
BA_ "FlexKomComment" SG_ 37 EngTrqStatic "ECM_A1 Packet";
BA_ "GenSigTimeout_DTCM" SG_ 37 ExpEngTrq 105;
BA_ "GenSigStartValue" SG_ 37 ExpEngTrq 8191;
BA_ "GenSigSNA" SG_ 37 ExpEngTrq "1FFFh";
BA_ "GenSigCycleTime" SG_ 37 ExpEngTrq 10;
BA_ "FlexKomSigStartValue" SG_ 37 ExpEngTrq "FFFF1FFF1FFF00FFh";
BA_ "FlexKomSigStartPos" SG_ 37 ExpEngTrq 7;
BA_ "FlexKomSigName" SG_ 37 ExpEngTrq "ECM_A1_PKT";
BA_ "FlexKomSigLaenge" SG_ 37 ExpEngTrq 64;
BA_ "FlexKomSID" SG_ 37 ExpEngTrq 446;
BA_ "FlexKomIsMotorola" SG_ 37 ExpEngTrq 1;
BA_ "FlexKomComment" SG_ 37 ExpEngTrq "ECM_A1 Packet";
BA_ "GenSigSNA" SG_ 37 MC_ECM_A1 "0h";
BA_ "GenSigCycleTime" SG_ 37 MC_ECM_A1 10;
BA_ "FlexKomSigStartValue" SG_ 37 MC_ECM_A1 "FFFF1FFF1FFF00FFh";
BA_ "FlexKomSigStartPos" SG_ 37 MC_ECM_A1 7;
BA_ "FlexKomSigName" SG_ 37 MC_ECM_A1 "ECM_A1_PKT";
BA_ "FlexKomSigLaenge" SG_ 37 MC_ECM_A1 64;
BA_ "FlexKomSID" SG_ 37 MC_ECM_A1 446;
BA_ "FlexKomIsMotorola" SG_ 37 MC_ECM_A1 1;
BA_ "FlexKomComment" SG_ 37 MC_ECM_A1 "ECM_A1 Packet";
BA_ "GenSigTimeout_CBC" SG_ 38 ANL_LFT_PHEV 105;
BA_ "GenSigSNA" SG_ 38 ANL_LFT_PHEV "0h";
BA_ "GenSigCycleTime" SG_ 38 ANL_LFT_PHEV 10;
BA_ "FlexKomSigStartValue" SG_ 38 ANL_LFT_PHEV "FFFFFF00201E00FFh";
BA_ "FlexKomSigStartPos" SG_ 38 ANL_LFT_PHEV 7;
BA_ "FlexKomSigName" SG_ 38 ANL_LFT_PHEV "ECM_A1_PHEV_PKT";
BA_ "FlexKomSigLaenge" SG_ 38 ANL_LFT_PHEV 64;
BA_ "FlexKomSID" SG_ 38 ANL_LFT_PHEV 2992;
BA_ "FlexKomIsMotorola" SG_ 38 ANL_LFT_PHEV 1;
BA_ "FlexKomComment" SG_ 38 ANL_LFT_PHEV "ECM_A1_PHEV_PKT";
BA_ "GenSigStartValue" SG_ 38 CRC_ECM_A1_PHEV 255;
BA_ "GenSigSNA" SG_ 38 CRC_ECM_A1_PHEV "FFh";
BA_ "GenSigCycleTime" SG_ 38 CRC_ECM_A1_PHEV 10;
BA_ "FlexKomSigStartValue" SG_ 38 CRC_ECM_A1_PHEV "FFFFFF00201E00FFh";
BA_ "FlexKomSigStartPos" SG_ 38 CRC_ECM_A1_PHEV 7;
BA_ "FlexKomSigName" SG_ 38 CRC_ECM_A1_PHEV "ECM_A1_PHEV_PKT";
BA_ "FlexKomSigLaenge" SG_ 38 CRC_ECM_A1_PHEV 64;
BA_ "FlexKomSID" SG_ 38 CRC_ECM_A1_PHEV 2992;
BA_ "FlexKomIsMotorola" SG_ 38 CRC_ECM_A1_PHEV 1;
BA_ "FlexKomComment" SG_ 38 CRC_ECM_A1_PHEV "ECM_A1_PHEV_PKT";
BA_ "GenSigSNA" SG_ 38 CYL_CUT_POSS_PHEV "0h";
BA_ "GenSigCycleTime" SG_ 38 CYL_CUT_POSS_PHEV 10;
BA_ "FlexKomSigStartValue" SG_ 38 CYL_CUT_POSS_PHEV "FFFFFF00201E00FFh";
BA_ "FlexKomSigStartPos" SG_ 38 CYL_CUT_POSS_PHEV 7;
BA_ "FlexKomSigName" SG_ 38 CYL_CUT_POSS_PHEV "ECM_A1_PHEV_PKT";
BA_ "FlexKomSigLaenge" SG_ 38 CYL_CUT_POSS_PHEV 64;
BA_ "FlexKomSID" SG_ 38 CYL_CUT_POSS_PHEV 2992;
BA_ "FlexKomIsMotorola" SG_ 38 CYL_CUT_POSS_PHEV 1;
BA_ "FlexKomComment" SG_ 38 CYL_CUT_POSS_PHEV "ECM_A1_PHEV_PKT";
BA_ "GenSigSNA" SG_ 38 ECM_IMMO_STAT_CANC_PHEV "3h";
BA_ "GenSigCycleTime" SG_ 38 ECM_IMMO_STAT_CANC_PHEV 10;
BA_ "FlexKomSigStartValue" SG_ 38 ECM_IMMO_STAT_CANC_PHEV "FFFFFF00201E00FFh";
BA_ "FlexKomSigStartPos" SG_ 38 ECM_IMMO_STAT_CANC_PHEV 7;
BA_ "FlexKomSigName" SG_ 38 ECM_IMMO_STAT_CANC_PHEV "ECM_A1_PHEV_PKT";
BA_ "FlexKomSigLaenge" SG_ 38 ECM_IMMO_STAT_CANC_PHEV 64;
BA_ "FlexKomSID" SG_ 38 ECM_IMMO_STAT_CANC_PHEV 2992;
BA_ "FlexKomIsMotorola" SG_ 38 ECM_IMMO_STAT_CANC_PHEV 1;
BA_ "FlexKomComment" SG_ 38 ECM_IMMO_STAT_CANC_PHEV "ECM_A1_PHEV_PKT";
BA_ "GenSigSNA" SG_ 38 ECM_LHOM_Trans_PHEV "0h";
BA_ "GenSigCycleTime" SG_ 38 ECM_LHOM_Trans_PHEV 10;
BA_ "FlexKomSigStartValue" SG_ 38 ECM_LHOM_Trans_PHEV "FFFFFF00201E00FFh";
BA_ "FlexKomSigStartPos" SG_ 38 ECM_LHOM_Trans_PHEV 7;
BA_ "FlexKomSigName" SG_ 38 ECM_LHOM_Trans_PHEV "ECM_A1_PHEV_PKT";
BA_ "FlexKomSigLaenge" SG_ 38 ECM_LHOM_Trans_PHEV 64;
BA_ "FlexKomSID" SG_ 38 ECM_LHOM_Trans_PHEV 2992;
BA_ "FlexKomIsMotorola" SG_ 38 ECM_LHOM_Trans_PHEV 1;
BA_ "FlexKomComment" SG_ 38 ECM_LHOM_Trans_PHEV "ECM_A1_PHEV_PKT";
BA_ "GenSigSNA" SG_ 38 ECM_ParkSL_Status "3h";
BA_ "GenSigCycleTime" SG_ 38 ECM_ParkSL_Status 10;
BA_ "FlexKomSigStartValue" SG_ 38 ECM_ParkSL_Status "FFFFFF00201E00FFh";
BA_ "FlexKomSigStartPos" SG_ 38 ECM_ParkSL_Status 7;
BA_ "FlexKomSigName" SG_ 38 ECM_ParkSL_Status "ECM_A1_PHEV_PKT";
BA_ "FlexKomSigLaenge" SG_ 38 ECM_ParkSL_Status 64;
BA_ "FlexKomSID" SG_ 38 ECM_ParkSL_Status 2992;
BA_ "FlexKomIsMotorola" SG_ 38 ECM_ParkSL_Status 1;
BA_ "FlexKomComment" SG_ 38 ECM_ParkSL_Status "ECM_A1_PHEV_PKT";
BA_ "RID" SG_ 38 ESS_ENG_ST_PHEV "1653";
BA_ "GenSigTimeout_RF_HUB" SG_ 38 ESS_ENG_ST_PHEV 105;
BA_ "GenSigTimeout_ORC" SG_ 38 ESS_ENG_ST_PHEV 35;
BA_ "GenSigTimeout_CBC" SG_ 38 ESS_ENG_ST_PHEV 105;
BA_ "GenSigStartValue" SG_ 38 ESS_ENG_ST_PHEV 15;
BA_ "GenSigSNA" SG_ 38 ESS_ENG_ST_PHEV "Fh";
BA_ "GenSigCycleTime" SG_ 38 ESS_ENG_ST_PHEV 10;
BA_ "FlexKomSigStartValue" SG_ 38 ESS_ENG_ST_PHEV "FFFFFF00201E00FFh";
BA_ "FlexKomSigStartPos" SG_ 38 ESS_ENG_ST_PHEV 7;
BA_ "FlexKomSigName" SG_ 38 ESS_ENG_ST_PHEV "ECM_A1_PHEV_PKT";
BA_ "FlexKomSigLaenge" SG_ 38 ESS_ENG_ST_PHEV 64;
BA_ "FlexKomSID" SG_ 38 ESS_ENG_ST_PHEV 2992;
BA_ "FlexKomIsMotorola" SG_ 38 ESS_ENG_ST_PHEV 1;
BA_ "FlexKomComment" SG_ 38 ESS_ENG_ST_PHEV "ECM_A1_PHEV_PKT";
BA_ "GenSigSNA" SG_ 38 ESS_ReqShiftPark_PHEV "0h";
BA_ "GenSigCycleTime" SG_ 38 ESS_ReqShiftPark_PHEV 10;
BA_ "FlexKomSigStartValue" SG_ 38 ESS_ReqShiftPark_PHEV "FFFFFF00201E00FFh";
BA_ "FlexKomSigStartPos" SG_ 38 ESS_ReqShiftPark_PHEV 7;
BA_ "FlexKomSigName" SG_ 38 ESS_ReqShiftPark_PHEV "ECM_A1_PHEV_PKT";
BA_ "FlexKomSigLaenge" SG_ 38 ESS_ReqShiftPark_PHEV 64;
BA_ "FlexKomSID" SG_ 38 ESS_ReqShiftPark_PHEV 2992;
BA_ "FlexKomIsMotorola" SG_ 38 ESS_ReqShiftPark_PHEV 1;
BA_ "FlexKomComment" SG_ 38 ESS_ReqShiftPark_PHEV "ECM_A1_PHEV_PKT";
BA_ "GenSigStartValue" SG_ 38 EngMaxRPM_PHEV 255;
BA_ "GenSigSNA" SG_ 38 EngMaxRPM_PHEV "FFh";
BA_ "GenSigCycleTime" SG_ 38 EngMaxRPM_PHEV 10;
BA_ "FlexKomSigStartValue" SG_ 38 EngMaxRPM_PHEV "FFFFFF00201E00FFh";
BA_ "FlexKomSigStartPos" SG_ 38 EngMaxRPM_PHEV 7;
BA_ "FlexKomSigName" SG_ 38 EngMaxRPM_PHEV "ECM_A1_PHEV_PKT";
BA_ "FlexKomSigLaenge" SG_ 38 EngMaxRPM_PHEV 64;
BA_ "FlexKomSID" SG_ 38 EngMaxRPM_PHEV 2992;
BA_ "FlexKomIsMotorola" SG_ 38 EngMaxRPM_PHEV 1;
BA_ "FlexKomComment" SG_ 38 EngMaxRPM_PHEV "ECM_A1_PHEV_PKT";
BA_ "RID" SG_ 38 EngRPM_PHEV "2185";
BA_ "GenSigTimeout_TPM" SG_ 38 EngRPM_PHEV 105;
BA_ "GenSigTimeout_TCM" SG_ 38 EngRPM_PHEV 105;
BA_ "GenSigTimeout_ORC" SG_ 38 EngRPM_PHEV 35;
BA_ "GenSigTimeout_IC" SG_ 38 EngRPM_PHEV 105;
BA_ "GenSigTimeout_ESM" SG_ 38 EngRPM_PHEV 105;
BA_ "GenSigTimeout_EHPS" SG_ 38 EngRPM_PHEV 105;
BA_ "GenSigTimeout_DTCM" SG_ 38 EngRPM_PHEV 105;
BA_ "GenSigTimeout_CBC" SG_ 38 EngRPM_PHEV 105;
BA_ "GenSigStartValue" SG_ 38 EngRPM_PHEV 65535;
BA_ "GenSigSNA" SG_ 38 EngRPM_PHEV "FFFFh";
BA_ "GenSigCycleTime" SG_ 38 EngRPM_PHEV 10;
BA_ "FlexKomSigStartValue" SG_ 38 EngRPM_PHEV "FFFFFF00201E00FFh";
BA_ "FlexKomSigStartPos" SG_ 38 EngRPM_PHEV 7;
BA_ "FlexKomSigName" SG_ 38 EngRPM_PHEV "ECM_A1_PHEV_PKT";
BA_ "FlexKomSigLaenge" SG_ 38 EngRPM_PHEV 64;
BA_ "FlexKomSID" SG_ 38 EngRPM_PHEV 2992;
BA_ "FlexKomIsMotorola" SG_ 38 EngRPM_PHEV 1;
BA_ "FlexKomComment" SG_ 38 EngRPM_PHEV "ECM_A1_PHEV_PKT";
BA_ "RID" SG_ 38 FullOFC_Actv_PHEV "1822";
BA_ "GenSigSNA" SG_ 38 FullOFC_Actv_PHEV "0h";
BA_ "GenSigCycleTime" SG_ 38 FullOFC_Actv_PHEV 10;
BA_ "FlexKomSigStartValue" SG_ 38 FullOFC_Actv_PHEV "FFFFFF00201E00FFh";
BA_ "FlexKomSigStartPos" SG_ 38 FullOFC_Actv_PHEV 7;
BA_ "FlexKomSigName" SG_ 38 FullOFC_Actv_PHEV "ECM_A1_PHEV_PKT";
BA_ "FlexKomSigLaenge" SG_ 38 FullOFC_Actv_PHEV 64;
BA_ "FlexKomSID" SG_ 38 FullOFC_Actv_PHEV 2992;
BA_ "FlexKomIsMotorola" SG_ 38 FullOFC_Actv_PHEV 1;
BA_ "FlexKomComment" SG_ 38 FullOFC_Actv_PHEV "ECM_A1_PHEV_PKT";
BA_ "GenSigSNA" SG_ 38 MC_ECM_A1_PHEV "0h";
BA_ "GenSigCycleTime" SG_ 38 MC_ECM_A1_PHEV 10;
BA_ "FlexKomSigStartValue" SG_ 38 MC_ECM_A1_PHEV "FFFFFF00201E00FFh";
BA_ "FlexKomSigStartPos" SG_ 38 MC_ECM_A1_PHEV 7;
BA_ "FlexKomSigName" SG_ 38 MC_ECM_A1_PHEV "ECM_A1_PHEV_PKT";
BA_ "FlexKomSigLaenge" SG_ 38 MC_ECM_A1_PHEV 64;
BA_ "FlexKomSID" SG_ 38 MC_ECM_A1_PHEV 2992;
BA_ "FlexKomIsMotorola" SG_ 38 MC_ECM_A1_PHEV 1;
BA_ "FlexKomComment" SG_ 38 MC_ECM_A1_PHEV "ECM_A1_PHEV_PKT";
BA_ "RID" SG_ 38 ThrmlMngActv_PHEV "1613";
BA_ "GenSigSNA" SG_ 38 ThrmlMngActv_PHEV "0h";
BA_ "GenSigCycleTime" SG_ 38 ThrmlMngActv_PHEV 10;
BA_ "FlexKomSigStartValue" SG_ 38 ThrmlMngActv_PHEV "FFFFFF00201E00FFh";
BA_ "FlexKomSigStartPos" SG_ 38 ThrmlMngActv_PHEV 7;
BA_ "FlexKomSigName" SG_ 38 ThrmlMngActv_PHEV "ECM_A1_PHEV_PKT";
BA_ "FlexKomSigLaenge" SG_ 38 ThrmlMngActv_PHEV 64;
BA_ "FlexKomSID" SG_ 38 ThrmlMngActv_PHEV 2992;
BA_ "FlexKomIsMotorola" SG_ 38 ThrmlMngActv_PHEV 1;
BA_ "FlexKomComment" SG_ 38 ThrmlMngActv_PHEV "ECM_A1_PHEV_PKT";
VAL_ 155 AC_OutptCurrStat 255 "SNA" ;
VAL_ 155 BonnetAjarRawValSts 0 "LVL0" 1 "LVL1" 2 "LVL2" 3 "LVL3" 4 "LVL4" 5 "LVL5" 6 "LVL6" 7 "LVL7" 8 "LVL8" 9 "LVL9" 10 "LVL10" 11 "LVL11" 12 "LVL12" 13 "LVL13" 14 "LVL14" 15 "LVL15" ;
VAL_ 155 BrkPdlStat_CBC 0 "UPSTOP" 1 "PSD" 2 "NDEF2" 3 "SNA" ;
VAL_ 155 DriverDoor2AjarRawValSts 0 "LVL0" 1 "LVL1" 2 "LVL2" 3 "LVL3" 4 "LVL4" 5 "LVL5" 6 "LVL6" 7 "LVL7" 8 "LVL8" 9 "LVL9" 10 "LVL10" 11 "LVL11" 12 "LVL12" 13 "LVL13" 14 "LVL14" 15 "LVL15" ;
VAL_ 155 DriverDoor2AjarXtionSts 1 "NONE" 2 "TRNS" 3 "SNA" ;
VAL_ 155 DriverDoorAjarRawValSts 0 "LVL0" 1 "LVL1" 2 "LVL2" 3 "LVL3" 4 "LVL4" 5 "LVL5" 6 "LVL6" 7 "LVL7" 8 "LVL8" 9 "LVL9" 10 "LVL10" 11 "LVL11" 12 "LVL12" 13 "LVL13" 14 "LVL14" 15 "LVL15" ;
VAL_ 155 DriverDoorAjarXtionSts 1 "NONE" 2 "TRNS" 3 "SNA" ;
VAL_ 155 FuelDrRelSwRawSt 255 "SNA" ;
VAL_ 155 LeakCheckTimerExpired 0 "NOT" 1 "ELAPSED" 3 "SNA" ;
VAL_ 155 PsngrDoorAjarRawValSts 0 "LVL0" 1 "LVL1" 2 "LVL2" 3 "LVL3" 4 "LVL4" 5 "LVL5" 6 "LVL6" 7 "LVL7" 8 "LVL8" 9 "LVL9" 10 "LVL10" 11 "LVL11" 12 "LVL12" 13 "LVL13" 14 "LVL14" 15 "LVL15" ;
VAL_ 155 PsngrDoorAjarXtionSts 1 "NONE" 2 "TRNS" 3 "SNA" ;
VAL_ 155 RefuelRequest 0 "NO" 1 "REFUEL" 3 "SNA" ;
VAL_ 307 AM_ECM_Trace 0 "DEFAULT" 2 "AM_ECM_TRACE" 3 "SNA" ;
VAL_ 307 DRV_DR_LOCKING 0 "Inactive" 1 "Active" ;
VAL_ 307 DRV_DR_UNLOCKING 0 "Inactive" 1 "Active" ;
VAL_ 307 DoorLockLastElSts 0 "LKD" 1 "DRV_DR_UNLKD" 2 "ALL_DR_UNLKD" 3 "SNA" ;
VAL_ 607 CBC_Reset_Flag 0 "DEFAULT" 2 "CBC_RESET_STATUS" 3 "SNA" ;
VAL_ 607 EngineOffTimer 4095 "SNA" ;
VAL_ 607 GlobDrvMdSts 0 "NONE" 1 "AUTO" 2 "SPORT" 3 "TRACK" 4 "SNOW" 5 "VALET" 6 "ROCK" 7 "TOW" 8 "ECO" 9 "LAUNCH" 10 "ALL" 11 "CUSTOM" 12 "MUD" 13 "SAND" 14 "PLUS" 15 "ICE" 16 "DYNAMIC" 17 "OFFROAD" 31 "SNA" ;
VAL_ 607 HRD_TOP_OFF 0 "TOP_ON" 1 "TOP_OFF" ;
VAL_ 319 CBCSAMFailSts 0 "Fail_not_present" 1 "Fail_present" ;
VAL_ 319 CurrBattFailStatus 0 "Fail_not_present" 1 "Fail_present" ;
VAL_ 319 IBS3_Error_Internal 0 "NO_ERROR" 1 "ERROR" ;
VAL_ 319 IBS3_Ibatt 65535 "SNA" ;
VAL_ 319 IBS3_Vbatt 511 "SNA" ;
VAL_ 319 Pitch_Angle 255 "SNA" ;
VAL_ 319 Roll_Angle 255 "SNA" ;
VAL_ 319 RsErrIBS3 0 "NO_ERROR" 1 "ERROR" ;
VAL_ 319 VoltBattFailStatus 0 "Fail_not_present" 1 "Fail_present" ;
VAL_ 456 VTA_STAT 0 "VTA_DISARM" 1 "VTA_PREARM" 2 "VTA_ARM" 3 "VTA_LGT" 4 "VTA_LGT_HORN" 5 "VTA_TAMP" 6 "VTA_ITM_Alarm" 7 "SNA" ;
VAL_ 788 CFG_FEATURE 0 "CFG_NONE" 1 "CFG_AUTO_LK" 2 "CFG_AUTO_UNLK" 3 "CFG_DLY_LK" 4 "CFG_DRV_FST" 5 "CFG_SOUND_LK" 6 "CFG_HORN_DUR" 7 "CFG_FLASH_LK" 8 "CFG_DrAlrPrsnt" 9 "CFG_PARK_ASSIST" 10 "CFG_LANG" 11 "CFG_US_METRIC" 12 "CFG_SRV_INTV" 13 "CFG_AUTO_WPR" 14 "CFG_HL_DLY" 15 "CFG_HL_WPR" 16 "CFG_ACC_DLY" 18 "CFG_REM_MEM" 19 "CFG_EASY_EXIT" 20 "CFG_LO_VEH" 21 "CFG_TILT_IN_REV" 22 "CFG_ILL_APRCH" 23 "CFG_ILL_ENTRY" 24 "CFG_GLBL_UP_WIN" 25 "CFG_GLBL_DN_WIN" 26 "CFG_DRL_ON" 27 "CFG_AHB" 28 "REST_FACT_DEF" 29 "CFG_CMP_CAL" 30 "CFG_CMP_VAR" 31 "CFG_VOICE_COMF" 32 "CFG_NAV_TBYT" 33 "CFG_HILL_ST" 34 "CFG_AFS" 35 "CFG_BSD" 36 "CFG_PE" 37 "CFG_WAL" 38 "CFG_DSS" 39 "CFG_SOUND_RS" 40 "CFG_DCS" 41 "CFG_AUTO_RELK" 42 "CFG_CMS" 43 "CFG_FCW" 44 "CFG_PRE_SAFE" 45 "CFG_BELT_SLAK" 46 "CFG_FUEL_SAV" 47 "CFG_FCW_SENS" 48 "CFG_HDLP_DROP" 49 "CFG_ECMM" 50 "PASS_WIN_LKOUT" 51 "AERO" 52 "JACK" 53 "CFG_TRLR" 54 "CFG_ALIGNMENT" 55 "CFG_ASCM_WMO" 57 "CFG_LDW" 58 "OIL" 59 "CFG_NORMAL_DCS" 61 "CFG_TRANSPORT" 62 "CFG_PTO_MODE" 63 "CFG_PTO_SINGLE_RPM" 64 "CFG_PTO_RPM1" 65 "CFG_PTO_RPM2" 66 "CFG_PTO_RPM3" 67 "CFG_PTO_Type" 68 "CFG_PTO_Auto_Resume" 69 "CFG_MAX_PTO_VEH_SPEED" 70 "RVC_GRID" 71 "DIMMER" 72 "RLE_LIGHT" 73 "RLE_HORN" 76 "CFG_TRLR_TYP" 77 "CFG_TRLR_NAME" 81 "CFG_PTS_FT" 82 "CFG_PTS_RR" 83 "CFG_PTS_FT_VOL" 84 "CFG_PTS_RR_VOL" 86 "CFG_PLG" 87 "CFG_AUX1" 88 "CFG_AUX2" 89 "CFG_AUX3" 90 "CFG_AUX4" 91 "CFG_AUX5" 93 "CFG_LDWTRQ" 94 "CFG_PTO_REM_Throttle" 95 "CFG_UNIT_DEFAULT" 96 "CFG_PressureUnit" 97 "CFG_SpeedUnit" 98 "CFG_DistanceUnit" 99 "CFG_ConsumptionUnit" 100 "CFG_CapacityUnit" 101 "CFG_TemperatureUnit" 102 "CFG_PowerUnit" 103 "CFG_TorqueUnit" 104 "CFG_EPS" 105 "CFG_CHMSL_LINES" 106 "CFG_POLICE_PE" 107 "EPB_AUTO_PRK" 108 "EPB_SERVICE" 109 "HOLD_N_GO" 110 "PWR_FLD_MRR" 111 "HANDS_FREE_LFT" 112 "HANDS_FREE_SLDR" 113 "SVC_GRIDLINES" 114 "SVC_DELAY" 115 "SLD_DR_ALRT" 116 "TEEN_FCW_SENS" 117 "TEEN_FCW_BRK" 118 "TEEN_PRK_ASST" 119 "TEEN_PRK_ASST_BRK" 120 "TEEN_FT_PRK_VOL" 121 "TEEN_RR_PRK_VOL" 122 "TEEN_MAX_SPEED" 123 "TEEN_FUEL_WRN" 124 "TEEN_FUEL_POPUP" 125 "TEEN_BLIND_SPOT" 126 "TEEN_RAIN_WPR" 127 "TEEN_AUTO_HB" 128 "TEEN_LGHT_WPR" 129 "TEEN_SLD_DR_ALRT" 130 "TEEN_PLG_CHIME" 131 "SLD_DR_CHM" 132 "TEEN_SLD_DR_CHM" 133 "CFG_ABSM" 134 "CFG_PADDLE_SHIFT" 137 "CFG_PRK_ASST_BRK" 138 "CFG_LDW_ON" 139 "CFG_PRK_ASST_TYPE" 140 "CFG_DR_ALR" 141 "CFG_RDY_DRV" 142 "CFG_PANEL_INTS" 143 "CFG_MOOD_LGT_INTS" 144 "CFG_ML_HDLP_LVL" 145 "CFG_BSM_TRLR" 146 "CFG_AUTO_SS" 147 "CFG_PCS" 148 "CFG_UNIT_SET" 149 "CFG_DOORS_OFF_ACC_DLY" 150 "CFG_MOTORIZED_SEATBELT" 151 "CFG_MOTORIZED_SEATBELT_STRN" 152 "CFG_TSI" 153 "CFG_LKA" 154 "CFG_LKA_SENS" 155 "CFG_LKA_STRN" 156 "CFG_ABSD" 157 "CFG_ABSD_SENS" 158 "CFG_ABSD_STRN" 162 "CFG_TIRE_FILL_ALERT" 163 "CFG_POWER_SIDE_STEP" 164 "CFG_AUTO_STOP_START" 165 "CFG_PEB" 166 "CFG_FFC_GRIDLINES" 167 "CFG_RVC_CVPM_DGRID" 168 "CFG_RVC_CVPM_SGRID" 169 "CFG_SPEED_THRESHOLD_VALUE" 170 "CFG_SPEED_THRESHOLD_CHECK_BOX" 171 "CFG_EXTERNAL_LIGHT_SENSOR" 172 "CFG_BUZZER_VOLUME_LEVEL" 173 "CFG_TRUNK_UNLOCK_ENABLE" 174 "CFG_BACKUP_ALARM" 175 "CFG_RR_CARGO_GUIDE_LGT" 176 "CFG_PTO_HI_IDLE" 177 "CFG_PTO_HI_IDLE_RPM" 178 "CFG_PTO_RMT_RPM_CTRL" 179 "CFG_PTO_SS_GEAR_RATIO" 180 "CFG_PTO_ACC_INT" 181 "CFG_PTO_RAMP_RATE" 182 "CFG_PTO_PB" 183 "CFG_HWRSS" 184 "CFG_SEIU_INPUT_WIRE" 185 "CFG_SEIU_RPM" 186 "CFG_BED_LOWER" 187 "CFG_TSR_WARNING_MODE" 188 "CFG_TSR_WARNING_MODE_OFFSET" 189 "CFG_FT_PK_LOOSE_SHIP" 190 "CFG_RR_PK_LOOSE_SHIP" 191 "CFG_AUX6" 192 "CFG_CHMSL_DYN_CNTR" 193 "CFG_3RD_ROW_LOCK" 194 "CFG_CHARGE_LOW_POPUP" 195 "CFG_ESAVE" 196 "CFG_ESAVE_BATT_LVL" 197 "CFG_FOBIK_SAFE" 198 "CFG_FOB_Left_Vehicle_Chime" 199 "CFG_Theft_Alarm" 200 "CFG_PANIC_ALARM" 201 "CFG_SECURE_PARK_ACTIVATION" 202 "CFG_SECURE_PARK_DEACTIVATION" 203 "CFG_LIFTGATE_RELEASE_INSIDEBUTTON" 204 "CFG_LIFTGATE_RELEASE_UNLOCKWITHDOORS" 205 "CFG_VISM_KEEP_AWAKE" ;
VAL_ 788 CFG_STAT_RQ 0 "CFG_DEF" 1 "CFG_DSBL" 2 "CFG_ENBL" 3 "CFG_SPEC" ;
VAL_ 805 Next_Charge_EndDay 0 "No_Selection" 1 "M" 2 "T" 3 "W" 4 "Th" 5 "F" 6 "Sa" 7 "S" 9 "No_Schedule_Set" 15 "SNA" ;
VAL_ 805 Next_Charge_End_Time_Hr 25 "Charge_Until_Full" 31 "SNA" ;
VAL_ 805 Next_Charge_End_Time_Min 15 "SNA" ;
VAL_ 805 Next_Charge_StartDay 0 "No_Selection" 1 "M" 2 "T" 3 "W" 4 "Th" 5 "F" 6 "Sa" 7 "S" 9 "No_Schedule_Set" 15 "SNA" ;
VAL_ 805 Next_Charge_Start_Time_Hr 31 "SNA" ;
VAL_ 805 Next_Charge_Start_Time_Min 15 "SNA" ;
VAL_ 805 Next_Climate_Day 0 "No_Selection" 1 "M" 2 "T" 3 "W" 4 "Th" 5 "F" 6 "Sa" 7 "S" 9 "No_Schedule_Set" 15 "SNA" ;
VAL_ 805 Next_Climate_Time_Hr 31 "SNA" ;
VAL_ 805 Next_Climate_Time_Min 15 "SNA" ;
VAL_ 856 CMP_DIR 0 "CMP_N" 1 "CMP_N_E" 2 "CMP_E" 3 "CMP_S_E" 4 "CMP_S" 5 "CMP_S_W" 6 "CMP_W" 7 "CMP_N_W" 8 "NONE" 15 "SNA" ;
VAL_ 856 CMP_DIR_RAW 511 "SNA_Default" ;
VAL_ 856 VAR_VAL 15 "SNA_Default" ;
VAL_ 219 CfgFeature 0 "CFG_NONE" 1 "ABEV" 2 "TPM_RESET" 3 "EPB_OFF" 4 "PASS_AB_RQ_STAT" 5 "WIPER_SP" 6 "CFG_StopStart" ;
VAL_ 219 CfgStatRq 0 "CFG_DEF" 1 "CFG_DSBL" 2 "CFG_ENBL" 3 "CFG_SPEC" ;
VAL_ 848 DateTmDay 255 "SNA" ;
VAL_ 848 DateTmFormat 0 "NDEF0" 1 "FORMAT_12H" 2 "FORMAT_24H" 3 "FORMAT_0" 4 "FORMAT_1" 5 "FORMAT_2" 6 "FORMAT_3" 7 "SNA" ;
VAL_ 848 DateTmHour 255 "SNA" ;
VAL_ 848 DateTmMinute 255 "SNA" ;
VAL_ 848 DateTmMonth 255 "SNA" ;
VAL_ 848 DateTmSec 255 "SNA" ;
VAL_ 848 DateTmYear 65535 "SNA" ;
VAL_ 153 As_DispRq 0 "No_RQ" 1 "ACC" 2 "FCW" 3 "SNA" ;
VAL_ 153 DAS_ACCEL_Rq 4095 "SNA" ;
VAL_ 153 DAS_Rq_ID 0 "IDLE" 1 "ACC" 2 "CMS" 3 "ABA" 4 "LSCM" 5 "CMS_XTD" 6 "PEB" 7 "SNA" ;
VAL_ 153 DAS_Sts 0 "OK" 1 "INTERNAL" 2 "EXTERNAL" 3 "SNA" ;
VAL_ 153 EngTrqRq_DAS 8191 "SNA" ;
VAL_ 153 GrMax_RqDAS 0 "PASSIVE" 1 "G1" 2 "G2" 3 "G3" 4 "G4" 5 "G5" 6 "G6" 7 "G7" 8 "G8" 9 "G9" 10 "G10" 11 "G11" 12 "G12" ;
VAL_ 232 ACCOnOff 0 "OFF" 1 "NCC" 2 "NCC_SET" 3 "ACC_ON" 4 "ACC_SET" 7 "SNA" ;
VAL_ 232 FCW_Error 0 "No_Error" 1 "FCW_Error" 2 "Limited_FCW" 3 "SNA" ;
VAL_ 232 HMI_Screens 255 "SNA" ;
VAL_ 232 ObjIntrstDist 255 "SNA" ;
VAL_ 232 SetSpeed_KPH 255 "SNA" ;
VAL_ 232 SetSpeed_MPH 255 "SNA" ;
VAL_ 232 Sm_ICON_Dspl 0 "NONE" 1 "OFF" 2 "READY_TG1" 3 "READY_TG2" 4 "READY_TG3" 5 "READY_TG4" 8 "ACC_E_NT_TG1" 9 "ACC_E_NT_TG2" 10 "ACC_E_NT_TG3" 11 "ACC_E_NT_TG4" 12 "ACC_E_WT_TG1" 13 "ACC_E_WT_TG2" 14 "ACC_E_WT_TG3" 15 "ACC_E_WT_TG4" 33 "NCC_OFF" 34 "NCC_READY" 40 "NCC_ENGAGED" 63 "SNA" ;
VAL_ 163 DsrSpeed_KPH 255 "SNA" ;
VAL_ 163 FCWSetting 0 "OFF" 1 "NEAR" 2 "MEDIUM" 3 "FAR" ;
VAL_ 163 WhlTrqRq_DAS_2 65535 "SNA" ;
VAL_ 250 IRCM_AHB_On 0 "OFF" 1 "ON" ;
VAL_ 250 Lane_DispPopupSts 255 "SNA" ;
VAL_ 860 DIST_TO_TURN 65535 "SNA" ;
VAL_ 860 NAV_ARROW 0 "NAV_NOT_ACT" ;
VAL_ 860 UNITS 0 "NO_UNITS" 1 "MILE" 2 "FEET" 3 "KM" 4 "METER" 5 "YARD" 7 "SNA" ;
VAL_ 967 DrvSeatDPFaultSts 0 "NO_FAULT" 1 "FAULTED" ;
VAL_ 967 DrvSeatDPSts 0 "Unoccupied" 1 "Occupied" 2 "Undetermined" 3 "SNA" ;
VAL_ 167 SyncPos 0 "LOW" 1 "HIGH" 2 "PRESS" 3 "TEMP" 4 "NS" 7 "SNA" ;
VAL_ 141 ACT_CNT_DIF_TRQ 255 "SNA" ;
VAL_ 141 DES_CNT_DIF_TRQ 255 "SNA" ;
VAL_ 141 SHFT_ABRT 1 "SNA" ;
VAL_ 141 TCASERANGESTATUS 0 "HIGH" 1 "NTRL" 2 "LOW" 3 "SNA" ;
VAL_ 141 TCASE_STAT 0 "SH_IPG" 1 "4LO" 2 "4HI" 3 "2WD" 4 "N" 5 "AUTO" 6 "PT" 7 "SNA" ;
VAL_ 145 DrvLnTrqRq 511 "SNA" ;
VAL_ 631 AXLELCKR_SRV_RQ 0 "OFF" 1 "ON" 2 "BLINK" 3 "SNA" ;
VAL_ 631 AxleLckrEVICDisplay 0 "NONE" 1 "SCREEN_1" 2 "SCREEN_2" 3 "SCREEN_3" 4 "SCREEN_4" 5 "SCREEN_5" 6 "SCREEN_6" 7 "SCREEN_7" 8 "SCREEN_8" 9 "SCREEN_9" 10 "SCREEN_10" 11 "SCREEN_11" 12 "SCREEN_12" 13 "SCREEN_13" 14 "SCREEN_14" 15 "SNA" ;
VAL_ 631 AxleLckrSts 0 "UNLOCKED" 1 "RR_LKD" 2 "FR_RR_LKD" 3 "SNA" ;
VAL_ 631 CNT_DIFF_MOD 0 "FREE" 1 "LM" 2 "ESP" 3 "SNA" ;
VAL_ 631 DTCM_HMI_Rq 0 "NONE" 1 "SCREEN_1" 2 "SCREEN_2" 3 "SCREEN_3" 4 "SCREEN_4" 5 "SCREEN_5" 6 "SCREEN_6" 7 "SCREEN_7" 8 "SCREEN_8" 9 "SCREEN_9" 10 "SCREEN_10" 11 "SCREEN_11" 12 "SCREEN_12" 13 "SCREEN_13" 14 "SCREEN_14" 15 "SCREEN_15" 16 "SCREEN_16" 17 "SCREEN_17" 18 "SCREEN_18" 19 "SCREEN_19" 20 "SCREEN_20" 21 "SCREEN_21" 22 "SCREEN_22" 23 "SCREEN_23" 24 "SCREEN_24" 25 "SCREEN_25" 26 "SCREEN_26" 27 "SCREEN_27" 28 "SCREEN_28" 29 "SCREEN_29" 30 "SCREEN_30" 31 "SNA" ;
VAL_ 631 Ft_RrAxleLkIndRq 0 "OFF" 1 "ON" 2 "BLINK" 3 "SNA" ;
VAL_ 631 RrAxleLkIndRq 0 "OFF" 1 "ON" 2 "BLINK" 3 "SNA" ;
VAL_ 631 TCASE_SRV_RQ 0 "OFF" 1 "ON" 2 "BLINK" 3 "SNA" ;
VAL_ 631 Tcase2WD_Stat 0 "OFF" 1 "ON" 2 "BLINK" 3 "SNA" ;
VAL_ 631 Tcase4Lock 0 "OFF" 1 "ON" 2 "BLINK" 3 "SNA" ;
VAL_ 631 Tcase4Low 0 "OFF" 1 "ON" 2 "BLINK" 3 "SNA" ;
VAL_ 631 TcaseAWD 0 "OFF" 1 "ON" 2 "BLINK" 3 "SNA" ;
VAL_ 631 TcaseNtrlStat 0 "OFF" 1 "ON" 2 "BLINK" 3 "SNA" ;
VAL_ 37 ECM_LHOM_Trans 0 "LH_NOT_ACTIVE" 1 "RM_UNAVAILABLE" 2 "PRECISE_TRQ" 3 "IMPRECISE_TRQ" ;
VAL_ 37 EngRPM 65535 "SNA" ;
VAL_ 37 EngTrqStatic 8191 "SNA" ;
VAL_ 37 ExpEngTrq 8191 "SNA" ;
VAL_ 38 ECM_IMMO_STAT_CANC_PHEV 0 "IS" 1 "KILL" 2 "RUN" 3 "SNA" ;
VAL_ 38 ECM_LHOM_Trans_PHEV 0 "LH_NOT_ACTIVE" 1 "RM_UNAVAILABLE" 2 "PRECISE_TRQ" 3 "IMPRECISE_TRQ" ;
VAL_ 38 ECM_ParkSL_Status 0 "Initialization" 1 "ParkLk_Sol_DeEnergized" 2 "ParkLk_Sol_Energized" 3 "SNA" ;
VAL_ 38 ESS_ENG_ST_PHEV 1 "ENS_STOPPED" 2 "ENS_RQ_ST" 3 "ENS_RUN" 4 "ENS_STOP_PEND" 5 "ENS_ST_PRTCT" 6 "ENS_ST_INH" 7 "ENS_DSBL" 8 "ENS_IHB_LATCH" 9 "ENS_STARTING" 10 "KEY_START" 11 "ENS_CHANGE_MIND" 15 "SNA" ;
VAL_ 38 EngMaxRPM_PHEV 255 "SNA" ;
VAL_ 38 EngRPM_PHEV 65535 "SNA" ;
